VERSION ""

NS_ :

BS_:

BU_: GENERIC_GWMWakeup Generic_BCM TRM GWM _delete APIM SODL RTM FCIM PDM SCMH SCMG HSWM GPSM RSM SODR DDM RBM DSM SCME TSTR

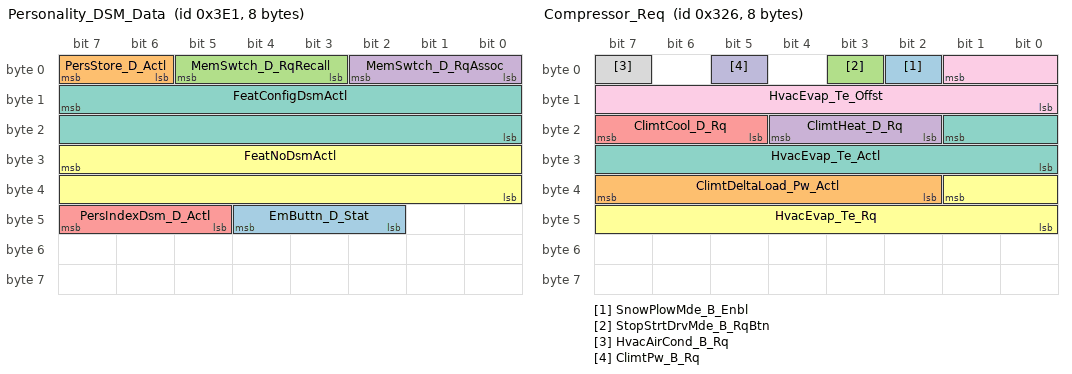
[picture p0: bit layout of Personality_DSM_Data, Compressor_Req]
BO_ 993 Personality_DSM_Data: 8 DSM
 SG_ EmButtn_D_Stat : 44|3@0+ (1,0) [0|7] "SED"  GWM
 SG_ PersStore_D_Actl : 7|2@0+ (1,0) [0|3] "SED"  GWM
 SG_ MemSwtch_D_RqRecall : 5|3@0+ (1,0) [0|7] "SED"  GWM
 SG_ MemSwtch_D_RqAssoc : 2|3@0+ (1,0) [0|7] "SED"  GWM
 SG_ PersIndexDsm_D_Actl : 47|3@0+ (1,0) [0|7] "SED"  GWM
 SG_ FeatNoDsmActl : 31|16@0+ (1,0) [0|65535] "Number"  GWM
 SG_ FeatConfigDsmActl : 15|16@0+ (1,0) [0|65535] "Undefined"  GWM

BO_ 1881 TesterPhysicalResRTM: 8 RTM
 SG_ TesterPhysicalResRTM : 7|64@0+ (1,0) [0|1.84467E+019] "unitless"  TSTR

BO_ 1873 TesterPhysicalReqRTM: 8 TSTR
 SG_ TesterPhysicalReqRTM : 7|64@0+ (1,0) [0|1.84467E+019] "unitless"  RTM

BO_ 2015 TesterFunctionalReq_M1: 8 TSTR
 SG_ TesterFunctionalReq : 7|64@0+ (1,0) [0|1.84467E+019] ""  APIM,PDM,SCMG,SCMH,TRM,RSM,RTM,GWM,DDM,DSM,FCIM,GPSM,HSWM,RBM,SCME,SODL,SODR

BO_ 806 Compressor_Req: 8 FCIM
 SG_ SnowPlowMde_B_Enbl : 2|1@0+ (1,0) [0|1] "SED"  GWM,SCMG,SCMH
 SG_ ClimtDeltaLoad_Pw_Actl : 39|6@0+ (50,-1600) [-1600|1450] "watts"  GWM
 SG_ StopStrtDrvMde_B_RqBtn : 3|1@0+ (1,0) [0|1] "SED"  GWM
 SG_ ClimtHeat_D_Rq : 20|3@0+ (1,0) [0|7] "SED"  GWM
 SG_ ClimtCool_D_Rq : 23|3@0+ (1,0) [0|7] "SED"  GWM
 SG_ HvacEvap_Te_Rq : 33|10@0+ (0.125,-50) [-50|77.875] "Degrees C"  GWM
 SG_ HvacEvap_Te_Actl : 17|10@0+ (0.125,-50) [-50|77.75] "Degrees C"  GWM
 SG_ HvacAirCond_B_Rq : 7|1@0+ (1,0) [0|1] "SED"  GWM
 SG_ HvacEvap_Te_Offst : 1|10@0+ (0.125,-50) [-50|77.875] "Degrees C"  GWM
 SG_ ClimtPw_B_Rq : 5|1@0+ (1,0) [0|1] "SED"  GWM

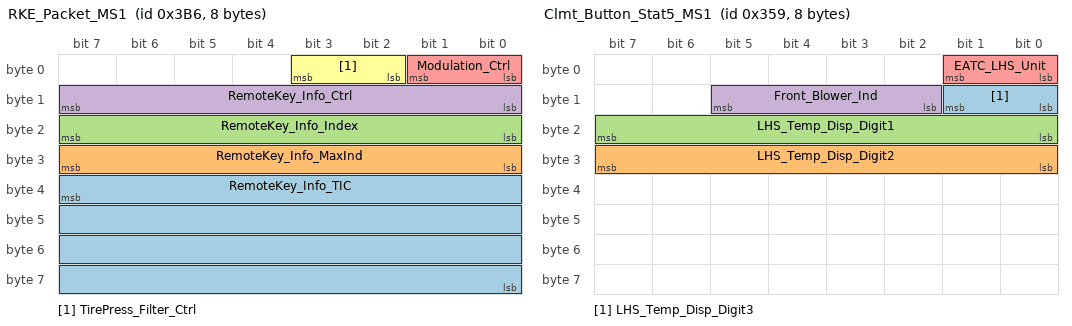
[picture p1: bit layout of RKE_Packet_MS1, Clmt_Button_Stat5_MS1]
BO_ 950 RKE_Packet_MS1: 8 GWM
 SG_ RemoteKey_Info_TIC : 39|32@0+ (1,0) [0|4294967295] "Unitless"  RTM
 SG_ RemoteKey_Info_MaxInd : 31|8@0+ (1,0) [0|255] "Unitless"  RTM
 SG_ RemoteKey_Info_Index : 23|8@0+ (1,0) [0|255] "Unitless"  RTM
 SG_ RemoteKey_Info_Ctrl : 15|8@0+ (1,0) [0|255] "Unitless" Vector__XXX
 SG_ Modulation_Ctrl : 1|2@0+ (1,0) [0|3] "SED" Vector__XXX
 SG_ TirePress_Filter_Ctrl : 3|2@0+ (1,0) [0|3] "SED"  RTM

BO_ 857 Clmt_Button_Stat5_MS1: 8 GWM
 SG_ LHS_Temp_Disp_Digit3 : 9|2@0+ (1,0) [0|3] "SED"  FCIM
 SG_ LHS_Temp_Disp_Digit2 : 31|8@0+ (1,0) [0|255] "ASCII"  FCIM
 SG_ LHS_Temp_Disp_Digit1 : 23|8@0+ (1,0) [0|255] "ASCII"  FCIM
 SG_ Front_Blower_Ind : 13|4@0+ (1,0) [0|15] "SED"  FCIM
 SG_ EATC_LHS_Unit : 1|2@0+ (1,0) [0|3] "SED"  FCIM

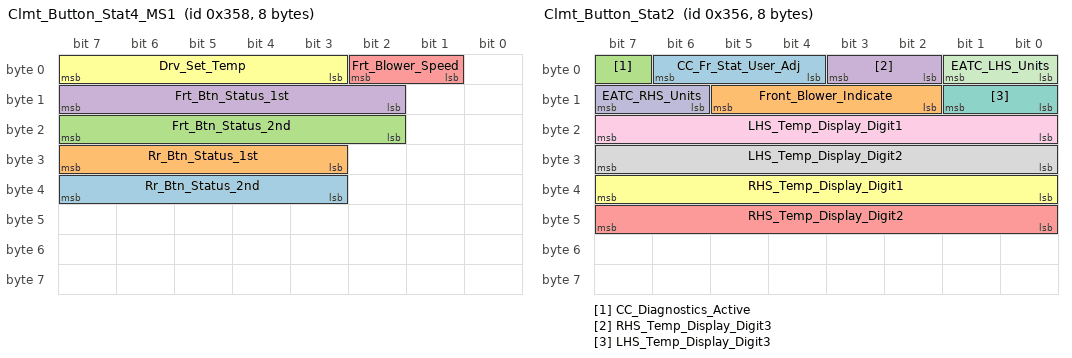
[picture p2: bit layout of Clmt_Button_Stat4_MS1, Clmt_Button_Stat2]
BO_ 856 Clmt_Button_Stat4_MS1: 8 GWM
 SG_ Rr_Btn_Status_2nd : 39|5@0+ (1,0) [0|31] "SED"  FCIM
 SG_ Rr_Btn_Status_1st : 31|5@0+ (1,0) [0|31] "SED"  FCIM
 SG_ Frt_Btn_Status_2nd : 23|6@0+ (1,0) [0|63] "SED"  FCIM
 SG_ Frt_Btn_Status_1st : 15|6@0+ (1,0) [0|63] "SED"  FCIM
 SG_ Frt_Blower_Speed : 2|2@0+ (1,0) [0|3] "SED"  FCIM
 SG_ Drv_Set_Temp : 7|5@0+ (1,0) [0|31] "SED"  FCIM

BO_ 854 Clmt_Button_Stat2: 8 FCIM
 SG_ CC_Fr_Stat_User_Adj : 6|3@0+ (1,0) [0|7] "SED"  GWM
 SG_ Front_Blower_Indicate : 13|4@0+ (1,0) [0|15] "SED"  GWM
 SG_ CC_Diagnostics_Active : 7|1@0+ (1,0) [0|1] "SED"  GWM
 SG_ RHS_Temp_Display_Digit3 : 3|2@0+ (1,0) [0|3] "SED"  GWM
 SG_ RHS_Temp_Display_Digit2 : 47|8@0+ (1,0) [0|255] "ASCII"  GWM
 SG_ RHS_Temp_Display_Digit1 : 39|8@0+ (1,0) [0|255] "ASCII"  GWM
 SG_ LHS_Temp_Display_Digit3 : 9|2@0+ (1,0) [0|3] "SED"  GWM
 SG_ LHS_Temp_Display_Digit2 : 31|8@0+ (1,0) [0|255] "ASCII"  GWM
 SG_ LHS_Temp_Display_Digit1 : 23|8@0+ (1,0) [0|255] "ASCII"  GWM
 SG_ EATC_RHS_Units : 15|2@0+ (1,0) [0|3] "SED"  GWM
 SG_ EATC_LHS_Units : 1|2@0+ (1,0) [0|3] "SED"  GWM

BO_ 1959 TesterPhysicalReqFCIM: 8 TSTR
 SG_ TesterPhysicalReqFCIM : 7|64@0+ (1,0) [0|1.84467E+019] "unitless"  FCIM

BO_ 1967 TesterPhysicalResFCIM: 8 FCIM
 SG_ TesterPhysicalResFCIM : 7|64@0+ (1,0) [0|1.84467E+019] "unitless"  TSTR

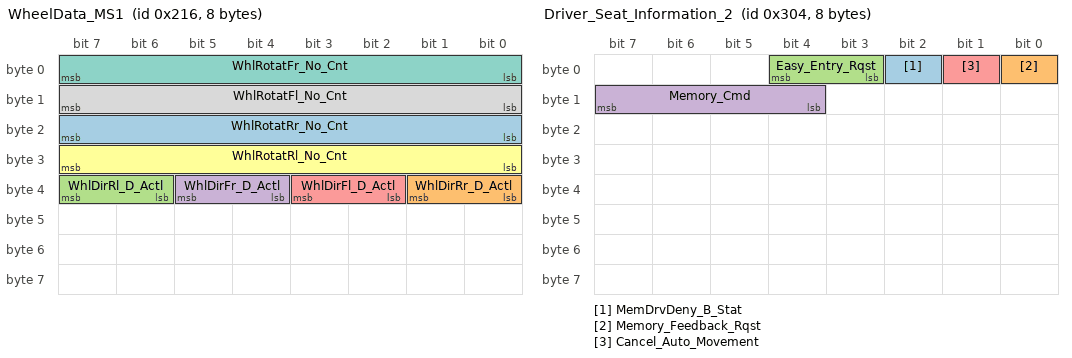
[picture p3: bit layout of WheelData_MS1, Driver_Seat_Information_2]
BO_ 534 WheelData_MS1: 8 GWM
 SG_ WhlRotatRr_No_Cnt : 23|8@0+ (1,0) [0|255] "Unitless"  GPSM
 SG_ WhlDirRr_D_Actl : 33|2@0+ (1,0) [0|3] "SED"  GPSM
 SG_ WhlDirRl_D_Actl : 39|2@0+ (1,0) [0|3] "SED"  GPSM
 SG_ WhlDirFr_D_Actl : 37|2@0+ (1,0) [0|3] "SED"  GPSM
 SG_ WhlDirFl_D_Actl : 35|2@0+ (1,0) [0|3] "SED"  GPSM
 SG_ WhlRotatRl_No_Cnt : 31|8@0+ (1,0) [0|255] "Unitless"  GPSM
 SG_ WhlRotatFr_No_Cnt : 7|8@0+ (1,0) [0|255] "Unitless"  SODL,SODR,GPSM
 SG_ WhlRotatFl_No_Cnt : 15|8@0+ (1,0) [0|255] "Unitless"  GPSM

BO_ 2008 TesterPhysicalResAPIM: 8 APIM
 SG_ TesterPhysicalResAPIM : 7|64@0+ (1,0) [0|1.84467E+019] "unitless"  TSTR

BO_ 772 Driver_Seat_Information_2: 8 DSM
 SG_ MemDrvDeny_B_Stat : 2|1@0+ (1,0) [0|1] "SED"  GWM
 SG_ Memory_Feedback_Rqst : 0|1@0+ (1,0) [0|1] "SED"  GWM
 SG_ Easy_Entry_Rqst : 4|2@0+ (1,0) [0|3] "SED"  SCMH,SCMG
 SG_ Memory_Cmd : 15|4@0+ (1,0) [0|15] "SED"  GWM,SCMH,DDM,PDM,SCMG
 SG_ Cancel_Auto_Movement : 1|1@0+ (1,0) [0|1] "SED"  PDM,DDM,SCMG

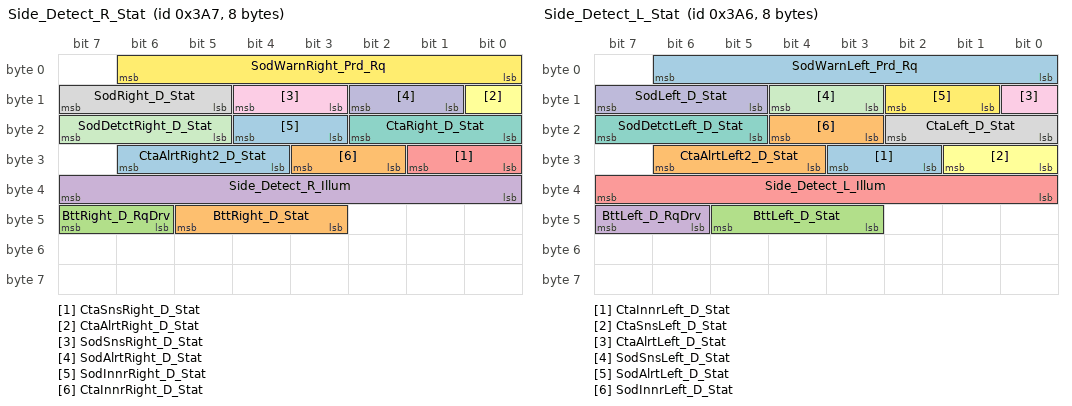
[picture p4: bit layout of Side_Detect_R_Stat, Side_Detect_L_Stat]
BO_ 935 Side_Detect_R_Stat: 8 SODR
 SG_ CtaAlrtRight2_D_Stat : 30|3@0+ (1,0) [0|7] "SED"  GWM
 SG_ BttRight_D_Stat : 45|3@0+ (1,0) [0|7] "SED"  GWM,SODL
 SG_ BttRight_D_RqDrv : 47|2@0+ (1,0) [0|3] "SED"  GWM,SODL
 SG_ Side_Detect_R_Illum : 39|8@0+ (1,0) [0|255] "Percent"  DDM,PDM,GWM
 SG_ CtaSnsRight_D_Stat : 25|2@0+ (1,0) [0|3] "SED"  SODL,GWM
 SG_ CtaAlrtRight_D_Stat : 8|1@0+ (1,0) [0|1] "SED"  DDM,PDM,GWM
 SG_ CtaRight_D_Stat : 18|3@0+ (1,0) [0|7] "SED"  SODL,GWM
 SG_ SodRight_D_Stat : 15|3@0+ (1,0) [0|7] "SED"  SODL,GWM
 SG_ SodSnsRight_D_Stat : 12|2@0+ (1,0) [0|3] "SED"  DDM,PDM,GWM,SODL
 SG_ SodAlrtRight_D_Stat : 10|2@0+ (1,0) [0|3] "SED"  DDM,PDM,GWM
 SG_ SodDetctRight_D_Stat : 23|3@0+ (1,0) [0|7] "SED"  GWM
 SG_ SodWarnRight_Prd_Rq : 6|7@0+ (1,0) [0|127] "millisecond"  DDM,PDM,GWM
 SG_ SodInnrRight_D_Stat : 20|2@0+ (1,0) [0|3] "SED"  GWM
 SG_ CtaInnrRight_D_Stat : 27|2@0+ (1,0) [0|3] "SED"  GWM

BO_ 934 Side_Detect_L_Stat: 8 SODL
 SG_ CtaInnrLeft_D_Stat : 27|2@0+ (1,0) [0|3] "SED"  GWM
 SG_ CtaAlrtLeft2_D_Stat : 30|3@0+ (1,0) [0|7] "SED"  GWM
 SG_ BttLeft_D_Stat : 45|3@0+ (1,0) [0|7] "SED"  GWM,SODR
 SG_ BttLeft_D_RqDrv : 47|2@0+ (1,0) [0|3] "SED"  GWM,SODR
 SG_ Side_Detect_L_Illum : 39|8@0+ (1,0) [0|255] "Percent"  GWM,DDM,PDM
 SG_ CtaSnsLeft_D_Stat : 25|2@0+ (1,0) [0|3] "SED"  SODR,GWM
 SG_ SodDetctLeft_D_Stat : 23|3@0+ (1,0) [0|7] "SED"  GWM
 SG_ CtaLeft_D_Stat : 18|3@0+ (1,0) [0|7] "SED"  SODR,GWM
 SG_ CtaAlrtLeft_D_Stat : 8|1@0+ (1,0) [0|1] "SED"  DDM,PDM,GWM
 SG_ SodLeft_D_Stat : 15|3@0+ (1,0) [0|7] "SED"  SODR,GWM
 SG_ SodSnsLeft_D_Stat : 12|2@0+ (1,0) [0|3] "SED"  DDM,PDM,SODR,GWM
 SG_ SodAlrtLeft_D_Stat : 10|2@0+ (1,0) [0|3] "SED"  DDM,PDM,GWM
 SG_ SodWarnLeft_Prd_Rq : 6|7@0+ (1,0) [0|127] "millisecond"  DDM,PDM,GWM
 SG_ SodInnrLeft_D_Stat : 20|2@0+ (1,0) [0|3] "SED"  GWM

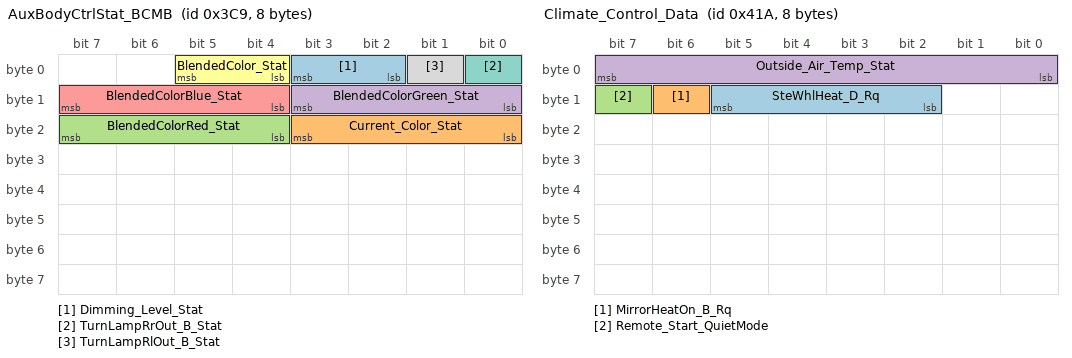
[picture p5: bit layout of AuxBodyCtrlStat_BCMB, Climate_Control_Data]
BO_ 969 AuxBodyCtrlStat_BCMB: 8 Generic_BCM
 SG_ Dimming_Level_Stat : 3|2@0+ (1,0) [0|3] "SED"  GWM
 SG_ Current_Color_Stat : 19|4@0+ (1,0) [0|15] "SED"  GWM
 SG_ BlendedColorRed_Stat : 23|4@0+ (1,0) [0|15] "SED"  GWM
 SG_ BlendedColorGreen_Stat : 11|4@0+ (1,0) [0|15] "SED"  GWM
 SG_ BlendedColorBlue_Stat : 15|4@0+ (1,0) [0|15] "SED"  GWM
 SG_ BlendedColor_Stat : 5|2@0+ (1,0) [0|3] "SED"  GWM
 SG_ TurnLampRrOut_B_Stat : 0|1@0+ (1,0) [0|1] "SED"  GWM
 SG_ TurnLampRlOut_B_Stat : 1|1@0+ (1,0) [0|1] "SED"  GWM

BO_ 1070 EngineData_2_MS1: 8 GWM
 SG_ StopStrtStdby_D_Indic_UB : 43|1@0+ (1,0) [0|1] "SED"  FCIM
 SG_ PassRstrnInd_Req_UB : 42|1@0+ (1,0) [0|1] "SED"  FCIM
 SG_ HiElPwInhbt_B_Stat_UB : 61|1@0+ (1,0) [0|1] "SED"  DDM,PDM
 SG_ HiElPwInhbt_B_Stat : 47|1@0+ (1,0) [0|1] "SED"  DDM,PDM
 SG_ StopStrtStdby_D_Indic : 46|3@0+ (1,0) [0|7] "SED"  FCIM
 SG_ CoolantFanStepAct_UB : 2|1@0+ (1,0) [0|1] "SED"  FCIM
 SG_ CoolantFanStepAct : 7|5@0+ (1,0) [0|31] "Steps"  FCIM
 SG_ VehVActlEng_D_Qf_UB : 1|1@0+ (1,0) [0|1] "SED"  DDM,PDM,RTM
 SG_ RstrnImpactEvntStatus_UB : 56|1@0+ (1,0) [0|1] "SED"  FCIM
 SG_ EngAirIn_Te_Actl_UB : 60|1@0+ (1,0) [0|1] "SED"  FCIM
 SG_ RstrnImpactEvntStatus : 59|3@0+ (1,0) [0|7] "SED"  FCIM
 SG_ EngAirIn_Te_Actl : 55|10@0+ (0.25,-128) [-128|127.25] "degC"  FCIM
 SG_ EngAout_N_Actl_UB : 0|1@0+ (1,0) [0|1] "SED"  FCIM
 SG_ EngAout_N_Actl : 28|13@0+ (2,0) [0|16382] "rpm"  FCIM
 SG_ VehVActlEng_D_Qf : 31|2@0+ (1,0) [0|3] "SED"  DSM,RBM,RTM,DDM,PDM,FCIM,SODL,SODR
 SG_ Veh_V_ActlEng_UB : 29|1@0+ (1,0) [0|1] "SED"  RBM,DSM,SCMG,SCMH,DDM,PDM,RTM,GPSM,FCIM,SODL,SODR
 SG_ Veh_V_ActlEng : 15|16@0+ (0.01,0) [0|655.35] "kph"  RBM,DSM,SCMG,SCMH,DDM,PDM,RTM,GPSM,FCIM,SODL,SODR
 SG_ PassRstrnInd_Req : 41|2@0+ (1,0) [0|3] "SED"  FCIM

BO_ 1050 Climate_Control_Data: 8 FCIM
 SG_ SteWhlHeat_D_Rq : 13|4@0+ (1,0) [0|15] "SED"  GWM,HSWM
 SG_ MirrorHeatOn_B_Rq : 14|1@0+ (1,0) [0|1] "SED"  DDM,PDM
 SG_ Remote_Start_QuietMode : 15|1@0+ (1,0) [0|1] "SED"  GWM
 SG_ Outside_Air_Temp_Stat : 7|8@0+ (0.5,-40) [-40|86.5] "Degrees C"  GWM,DDM,PDM

BO_ 1856 TesterPhysicalReqDDM: 8 TSTR
 SG_ TesterPhysicalReqDDM : 7|64@0+ (1,0) [0|1.84467E+019] "unitless"  DDM

BO_ 1864 TesterPhysicalResDDM: 8 DDM
 SG_ TesterPhysicalResDDM : 7|64@0+ (1,0) [0|1.84467E+019] "unitless"  TSTR

BO_ 1937 TesterPhysicalReqTRM: 8 TSTR
 SG_ TesterPhysicalReqTRM : 7|64@0+ (1,0) [0|1.84467E+019] "unitless"  TRM

BO_ 1364 TRM_Network_MgmtM: 8 TRM
 SG_ TRM_Network_Mgmt : 7|64@0+ (1,0) [0|1.844674407371E+019] "unitless"  DDM,DSM,FCIM,GPSM,GWM,PDM,RBM,RTM,SCME

BO_ 947 BodyInfo_3_MS1: 8 GWM
 SG_ ValetMode_D_Mem : 16|1@0+ (1,0) [0|1] "SED" Vector__XXX
 SG_ DrStatDrvErrCnt_B_Stat : 19|1@0+ (1,0) [0|1] "SED" Vector__XXX
 SG_ DimmingLvlEvnt_No_Actl : 18|2@0+ (1,0) [0|3] "unitless" Vector__XXX
 SG_ TurnLghtRightOn_B_Stat : 35|1@0+ (1,0) [0|1] "SED" Vector__XXX
 SG_ TurnLghtLeftOn_B_Stat : 54|1@0+ (1,0) [0|1] "SED" Vector__XXX
 SG_ Backlit_LED_Status : 23|4@0+ (1,0) [0|15] "SED"  DDM,FCIM,PDM
 SG_ FogLghtRearOn_B_Stat : 1|1@0+ (1,0) [0|1] "SED"  TRM
 SG_ IgnKeyType_D_Actl : 39|4@0+ (1,0) [0|15] "SED"  RSM,SODL,SODR
 SG_ TurnLghtRight_D_Rq : 63|2@0+ (1,0) [0|3] "SED"  RSM,DDM,PDM,TRM
 SG_ Parklamp_Status : 3|2@0+ (1,0) [0|3] "SED"  TRM,PDM,DDM,FCIM,SODL,SODR
 SG_ Litval : 47|8@0+ (1,0) [0|253] "SED"  DDM,FCIM,PDM,SODL,SODR
 SG_ Key_In_Ignition_Stat : 11|1@0+ (1,0) [0|1] "SED"  RSM,SCMG,SCMH,DSM,RTM
 SG_ Ignition_Status : 7|4@0+ (1,0) [0|15] "SED"  SCME,RSM,DDM,DSM,FCIM,GPSM,HSWM,PDM,RBM,RTM,SCMG,SCMH,TRM,SODL,SODR
 SG_ Dimming_Lvl : 31|8@0+ (1,0) [0|253] "SED"  DDM,FCIM,PDM
 SG_ Day_Night_Status : 15|2@0+ (1,0) [0|3] "SED"  DDM,FCIM,PDM
 SG_ Remote_Start_Status : 13|2@0+ (1,0) [0|3] "SED"  RSM,FCIM
 SG_ DrStatTgate_B_Actl : 0|1@0+ (1,0) [0|1] "SED"  RSM
 SG_ DrStatRr_B_Actl : 49|1@0+ (1,0) [0|1] "SED"  RBM,RSM
 SG_ DrStatRl_B_Actl : 48|1@0+ (1,0) [0|1] "SED"  RBM,RSM
 SG_ DrStatPsngr_B_Actl : 60|1@0+ (1,0) [0|1] "SED"  RBM,RSM
 SG_ DrStatInnrTgate_B_Actl : 58|1@0+ (1,0) [0|1] "SED"  RSM
 SG_ DrStatHood_B_Actl : 59|1@0+ (1,0) [0|1] "SED"  RSM
 SG_ DrStatDrv_B_Actl : 61|1@0+ (1,0) [0|1] "SED"  RBM,RSM
 SG_ PrkBrkActv_B_Actl : 55|1@0+ (1,0) [0|1] "SED" Vector__XXX
 SG_ LifeCycMde_D_Actl : 53|4@0+ (1,0) [0|15] "SED"  TRM,RTM,DDM,PDM,FCIM,HSWM
 SG_ Delay_Accy : 57|1@0+ (1,0) [0|1] "SED"  DDM,PDM
 SG_ FogLghtFrontOn_B_Stat : 56|1@0+ (1,0) [0|1] "SED" Vector__XXX
 SG_ TurnLghtLeft_D_Rq : 9|2@0+ (1,0) [0|3] "SED"  RSM,DDM,PDM,TRM
 SG_ CrashEvnt_D_Stat : 34|2@0+ (1,0) [0|3] "SED"  FCIM
 SG_ FuelPmpInhbt_B_Stat : 32|1@0+ (1,0) [0|1] "SED"  FCIM
 SG_ BodySrvcRqd_B_Rq : 10|1@0+ (1,0) [0|1] "SED" Vector__XXX

BO_ 293 ClmtCtrlSeatSet_Stat_v2: 8 SCME
 SG_ ClmtCtrlSeat_SetStat_Psgr : 15|8@0+ (1,0) [0|254] "SED"  FCIM
 SG_ ClmtCtrlSeat_SetStat_Dvr : 7|8@0+ (1,0) [0|254] "SED"  FCIM

CM_ BO_ 2015 "OBDII Request ($7DF) messages are for FNOS 1.0.1 only.
Diagnostic Functional Addressing ($7DF) and Dual Rate Periodic messages are for FNOS I3 only.";
CM_ SG_ 857 LHS_Temp_Disp_Digit3 "Added for MY 08";
CM_ SG_ 857 LHS_Temp_Disp_Digit2 "Added for MY 08";
CM_ SG_ 857 LHS_Temp_Disp_Digit1 "Added for MY 08";
CM_ SG_ 857 EATC_LHS_Unit "Added for MY 08";
CM_ SG_ 854 RHS_Temp_Display_Digit3 "Added for MY 08";
CM_ SG_ 854 RHS_Temp_Display_Digit2 "Added for MY 08";
CM_ SG_ 854 RHS_Temp_Display_Digit1 "Added for MY 08";
CM_ SG_ 854 LHS_Temp_Display_Digit3 "Added for MY 08";
CM_ SG_ 854 LHS_Temp_Display_Digit2 "Added for MY 08";
CM_ SG_ 854 LHS_Temp_Display_Digit1 "Added for MY 08";
CM_ SG_ 854 EATC_RHS_Units "Added for MY 08";
CM_ SG_ 854 EATC_LHS_Units "Added for MY 08";
CM_ SG_ 772 Memory_Feedback_Rqst "Updated to 1 bit for CGEA, Not backwards compatible";
CM_ SG_ 935 Side_Detect_R_Illum "DDMGenSigTimeoutTime=2000";
CM_ SG_ 935 SodRight_D_Stat "IPCGenSigTimeoutTime=1600";
CM_ SG_ 935 SodSnsRight_D_Stat "IPCGenSigTimeoutTime=1600";
CM_ SG_ 935 SodAlrtRight_D_Stat "DDMGenSigTimeoutTime=2000";
CM_ SG_ 935 CtaInnrRight_D_Stat "IPCGenSigTimeoutTime=1600";
CM_ SG_ 934 CtaInnrLeft_D_Stat "IPCGenSigTimeoutTime=1600";
CM_ SG_ 934 Side_Detect_L_Illum "DDMGenSigTimeoutTime=2000";
CM_ SG_ 934 SodLeft_D_Stat "IPCGenSigTimeoutTime=1600";
CM_ SG_ 934 SodSnsLeft_D_Stat "IPCGenSigTimeoutTime=1600";
CM_ SG_ 934 SodAlrtLeft_D_Stat "DDMGenSigTimeoutTime=2000";
CM_ SG_ 969 TurnLampRrOut_B_Stat "Signal not transmitted on vehicles without a BCMB module.";
CM_ SG_ 969 TurnLampRlOut_B_Stat "Signal not transmitted on vehicles without a BCMB module.";
CM_ SG_ 1070 HiElPwInhbt_B_Stat "Signal not transmitted on HEV programs";
CM_ SG_ 1050 Outside_Air_Temp_Stat "Filtered value, i.e. same as disply for customer";
CM_ SG_ 947 Dimming_Lvl "Refer to Vehicle Interior Illum Dimming Ctrl Sys Eng Spec, Table 2

";
CM_ SG_ 947 PrkBrkActv_B_Actl "Signal not transmitted on vehicles with electric park brake. ";
BA_DEF_ SG_  "U_V36X_MY18_5_Gas_Rx" ENUM  "No","Yes";
BA_DEF_ SG_  "U_V36X_MY18_5_Hev_Rx" ENUM  "No","Yes";
BA_DEF_ SG_  "U_U55x_MY18_Gas_Rx" ENUM  "No","Yes";
BA_DEF_ SG_  "U_V408_MY18_Gas_Rx" ENUM  "No","Yes";
BA_DEF_ SG_  "U_V408_MY18_Diesel_Rx" ENUM  "No","Yes";
BA_DEF_ SG_  "U_V36X_MY18_5_Diesel_Rx" ENUM  "No","Yes";
BA_DEF_ SG_  "U_V36X_MY19_5_Diesel_Rx" ENUM  "No","Yes";
BA_DEF_ SG_  "U_V363E_N_MY19_5_20_Gas_Rx" ENUM  "No","Yes";
BA_DEF_ SG_  "U_V363E_N_MY19_5_20_Diesel_Rx" ENUM  "No","Yes";
BA_DEF_ SG_  "U_U55x_MY18_Gas_Tx" ENUM  "No","Yes";
BA_DEF_ SG_  "GenSigTimeoutTime_SCMJ" INT 0 100000;
BA_DEF_ BO_  "FrameGatewayNetwork" STRING ;
BA_DEF_ SG_  "U_CD42_MY16_Diesel_Rx" ENUM  "No","Yes";
BA_DEF_ SG_  "U_CD42_MY16_Gas_Rx" ENUM  "No","Yes";
BA_DEF_ SG_  "U_CD43_MY17_Gas_Rx" ENUM  "No","Yes";
BA_DEF_ SG_  "U_P552_MY17_Gas_Rx" ENUM  "No","Yes";
BA_DEF_ SG_  "U_P552_MY17_Gas_Tx" ENUM  "No","Yes";
BA_DEF_ SG_  "GenSigTimeoutTime_SOBDMD_AHCM_F" INT 0 100000;
BA_DEF_ SG_  "GenSigTimeoutTime_SFMA" INT 0 100000;
BA_DEF_ SG_  "GenSigTimeoutTime_SFMB" INT 0 100000;
BA_DEF_ SG_  "GenSigTimeoutTime_SCMD" INT 0 100000;
BA_DEF_ SG_  "GenSigTimeoutTime_DCMH" INT 0 100000;
BA_DEF_ SG_  "GenSigTimeoutTime_DCMG" INT 0 100000;
BA_DEF_ SG_  "GenSigTimeoutTime_DCMF" INT 0 100000;
BA_DEF_ SG_  "GenSigTimeoutTime_DCME" INT 0 100000;
BA_DEF_ SG_  "GenSigTimeoutTime_BCMB_ABM" INT 0 100000;
BA_DEF_ SG_  "GenSigTimeoutTime_SCMC" INT 0 100000;
BA_DEF_ SG_  "GenSigTimeoutTime_BCMB_CAPM" INT 0 100000;
BA_DEF_ SG_  "GenSigTimeoutTime_GFM_ASM" INT 0 100000;
BA_DEF_ SG_  "GenSigTimeoutTime_SCMB_PSM" INT 0 100000;
BA_DEF_ SG_  "GenSigTimeoutTime_BCMB_ALCM" INT 0 100000;
BA_DEF_ SG_  "U_CD42_MY15_Diesel_Rx" ENUM  "No","Yes";
BA_DEF_ SG_  "U_CD42_MY15_Gas_Rx" ENUM  "No","Yes";
BA_DEF_ SG_  "U_U502_MY16_Gas_Rx" ENUM  "No","Yes";
BA_DEF_ SG_  "U_P558_MY17_Gas_Rx" ENUM  "No","Yes";
BA_DEF_ SG_  "U_P558_MY17_Diesel_Rx" ENUM  "No","Yes";
BA_DEF_ SG_  "U_CD42_MY15_Diesel_Tx" ENUM  "No","Yes";
BA_DEF_ SG_  "U_CD42_MY15_Gas_Tx" ENUM  "No","Yes";
BA_DEF_ SG_  "U_CD4_MY15_Diesel_Tx" ENUM  "No","Yes";
BA_DEF_ SG_  "U_CD4_MY15_Gas_Tx" ENUM  "No","Yes";
BA_DEF_ SG_  "U_CD4_MY15_Hev_Tx" ENUM  "No","Yes";
BA_DEF_ SG_  "U_CD4_MY15_Phev_Tx" ENUM  "No","Yes";
BA_DEF_ SG_  "U_P558_MY17_Gas_Tx" ENUM  "No","Yes";
BA_DEF_ SG_  "U_P558_MY17_Diesel_Tx" ENUM  "No","Yes";
BA_DEF_ SG_  "GenSigTimeoutTime_SCMF" INT 0 100000;
BA_DEF_ SG_  "GenSigTimeoutTime_RGTM" INT 0 100000;
BA_DEF_ SG_  "GenSigTimeoutTime_GENERIC" INT 0 100000;
BA_DEF_ SG_  "GenSigTimeoutTime_AHCM_FOH" INT 0 100000;
BA_DEF_ SG_  "GenSigTimeoutTime_RLCMA" INT 0 100000;
BA_DEF_ SG_  "GenSigTimeoutTime_BCMB" INT 0 100000;
BA_DEF_ SG_  "GenSigTimeoutTime_RHVAC" INT 0 100000;
BA_DEF_ SG_  "GenSigTimeoutTime_MRCMB" INT 0 100000;
BA_DEF_ SG_  "GenSigTimeoutTime_MRCMA" INT 0 100000;
BA_DEF_ SG_  "GenSigTimeoutTime_HVAC_RCCM" INT 0 100000;
BA_DEF_ SG_  "Gateway_ID" INT 0 0;
BA_DEF_ SG_  "GenSigTimeoutTime__delete" INT 0 100000;
BA_DEF_ SG_  "GenSigTimeoutTime_APIM" INT 0 100000;
BA_DEF_ SG_  "GenSigTimeoutTime_Generic_BCM" INT 0 100000;
BA_DEF_ SG_  "GenSigTimeoutTime_RSM" INT 0 100000;
BA_DEF_ SG_  "GenSigTimeoutTime_PDM" INT 0 100000;
BA_DEF_ SG_  "GenSigTimeoutTime_TRM" INT 0 100000;
BA_DEF_ SG_  "GenSigTimeoutTime_SCMG" INT 0 100000;
BA_DEF_ SG_  "GenSigTimeoutTime_SCMH" INT 0 100000;
BA_DEF_ SG_  "GenSigTimeoutTime_RTM" INT 0 100000;
BA_DEF_ SG_  "GenSigTimeoutTime_GWM" INT 0 100000;
BA_DEF_ SG_  "GenSigTimeoutTime_FCIM" INT 0 100000;
BA_DEF_ SG_  "GenSigTimeoutTime_HSWM" INT 0 100000;
BA_DEF_ SG_  "GenSigTimeoutTime_GPSM" INT 0 100000;
BA_DEF_ SG_  "GenSigTimeoutTime_RBM" INT 0 100000;
BA_DEF_ SG_  "GenSigTimeoutTime_DDM" INT 0 100000;
BA_DEF_ SG_  "GenSigTimeoutTime_DSM" INT 0 100000;
BA_DEF_ SG_  "GenSigTimeoutTime_SODR" INT 0 100000;
BA_DEF_ SG_  "GenSigTimeoutTime_SODL" INT 0 100000;
BA_DEF_ SG_  "GenSigTimeoutTime_TSTR" INT 0 100000;
BA_DEF_ SG_  "GenSigTimeoutTime_SCME" INT 0 100000;
BA_DEF_ BO_  "FrameGatewayMS1" HEX 0 1407;
BA_DEF_ BO_  "FrameGatewayHS3" HEX 0 1407;
BA_DEF_ BO_  "FrameGatewayHS2" HEX 0 1407;
BA_DEF_ BO_  "FrameGatewayHS1" HEX 0 1407;
BA_DEF_ BO_  "NetworkInitialization" ENUM  "No","Yes";
BA_DEF_ BO_  "FrameGatewayId" HEX 0 1407;
BA_DEF_ BO_  "EventRateOfChange" INT 10 10000;
BA_DEF_ BO_  "GenMsgStartDelayTime" INT 0 10000;
BA_DEF_ BO_  "GenMsgNrOfRepetition" INT 0 100;
BA_DEF_ BO_  "GenMsgDelayTime" INT 0 1000;
BA_DEF_ BO_  "GenMsgCycleTime" INT 0 100000;
BA_DEF_ BO_  "GenMsgSendType" ENUM  "FixedPeriodic","Event","EnabledPeriodic","NotUsed","NotUsed","EventPeriodic","NotUsed","NotUsed","NoMsgSendType";
BA_DEF_ SG_  "U_CD4_MY14_Phev_Tx" ENUM  "No","Yes";
BA_DEF_ SG_  "U_CD4_MY14_Hev_Tx" ENUM  "No","Yes";
BA_DEF_ SG_  "U_CD4_MY14_Gas_Tx" ENUM  "No","Yes";
BA_DEF_ SG_  "U_CD4_MY14_Diesel_Tx" ENUM  "No","Yes";
BA_DEF_ SG_  "U_CD43_MY16_Gas_Tx" ENUM  "No","Yes";
BA_DEF_ SG_  "U_UP375_MY15_Diesel_Tx" ENUM  "No","Yes";
BA_DEF_ SG_  "U_UP375_MY15_Gas_Tx" ENUM  "No","Yes";
BA_DEF_ SG_  "U_U502_MY15_Gas_Tx" ENUM  "No","Yes";
BA_DEF_ SG_  "U_B562LC_MY14_Gas_Tx" ENUM  "No","Yes";
BA_DEF_ SG_  "U_B562LC_MY14_Diesel_Tx" ENUM  "No","Yes";
BA_DEF_ SG_  "U_C489_MY14_Gas_Tx" ENUM  "No","Yes";
BA_DEF_ SG_  "U_S550_MY15_Gas_Tx" ENUM  "No","Yes";
BA_DEF_ SG_  "U_P552_MY15_Gas_Tx" ENUM  "No","Yes";
BA_DEF_ SG_  "U_CD42_MY14_Gas_Tx" ENUM  "No","Yes";
BA_DEF_ SG_  "U_CD42_MY14_Diesel_Tx" ENUM  "No","Yes";
BA_DEF_ SG_  "U_CD4_MY13_Phev_Tx" ENUM  "No","Yes";
BA_DEF_ SG_  "U_CD4_MY13_Hev_Tx" ENUM  "No","Yes";
BA_DEF_ SG_  "U_CD4_MY13_Gas_Tx" ENUM  "No","Yes";
BA_DEF_ SG_  "U_CD4_MY13_Diesel_Tx" ENUM  "No","Yes";
BA_DEF_ SG_  "U_CD4_MY14_Phev_Rx" ENUM  "No","Yes";
BA_DEF_ SG_  "U_CD4_MY14_Hev_Rx" ENUM  "No","Yes";
BA_DEF_ SG_  "U_CD4_MY14_Gas_Rx" ENUM  "No","Yes";
BA_DEF_ SG_  "U_CD4_MY14_Diesel_Rx" ENUM  "No","Yes";
BA_DEF_ SG_  "U_CD43_MY16_Gas_Rx" ENUM  "No","Yes";
BA_DEF_ SG_  "U_UP375_MY15_Diesel_Rx" ENUM  "No","Yes";
BA_DEF_ SG_  "U_UP375_MY15_Gas_Rx" ENUM  "No","Yes";
BA_DEF_ SG_  "U_B479_MY15_Gas_Rx" ENUM  "No","Yes";
BA_DEF_ SG_  "U_U502_MY15_Gas_Rx" ENUM  "No","Yes";
BA_DEF_ SG_  "U_B562LC_MY14_Gas_Rx" ENUM  "No","Yes";
BA_DEF_ SG_  "U_B562LC_MY14_Diesel_Rx" ENUM  "No","Yes";
BA_DEF_ SG_  "U_C489_MY14_Gas_Rx" ENUM  "No","Yes";
BA_DEF_ SG_  "U_S550_MY15_Gas_Rx" ENUM  "No","Yes";
BA_DEF_ SG_  "U_P552_MY15_Gas_Rx" ENUM  "No","Yes";
BA_DEF_ SG_  "U_CD42_MY14_Gas_Rx" ENUM  "No","Yes";
BA_DEF_ SG_  "U_CD42_MY14_Diesel_Rx" ENUM  "No","Yes";
BA_DEF_ SG_  "U_CD4_MY13_Phev_Rx" ENUM  "No","Yes";
BA_DEF_ SG_  "U_CD4_MY13_Hev_Rx" ENUM  "No","Yes";
BA_DEF_ SG_  "U_CD4_MY13_Gas_Rx" ENUM  "No","Yes";
BA_DEF_ SG_  "U_CD4_MY13_Diesel_Rx" ENUM  "No","Yes";
BA_DEF_ SG_  "ContentDependant" ENUM  "No","Yes";
BA_DEF_ SG_  "GenSigStartValue" INT 0 1000000000;
BA_DEF_ SG_  "UsedOnPgmDBC" ENUM  "No","Yes";
BA_DEF_ SG_  "CrossOver_LIN" ENUM  "No","Yes";
BA_DEF_ SG_  "CrossOver_InfoCAN" ENUM  "No","Yes";
BA_DEF_ SG_  "WakeupSignal" ENUM  "No","Yes";
BA_DEF_ SG_  "FMC_SIG_SSPEC" STRING ;
BA_DEF_ SG_  "GenSigMissingSourceValue" INT 0 1000000000;
BA_DEF_ SG_  "GenSigInactiveValue" INT 0 100000;
BA_DEF_ SG_  "GenSigSendType" ENUM  "Cyclic","OnWrite","vector_leerstring","OnChange","vector_leerstring","IfActive","vector_leerstring","NoSigSendType";
BA_DEF_ BO_  "DiagState" ENUM  "No","Yes";
BA_DEF_ BO_  "TpTxIndex" INT 0 255;
BA_DEF_ BO_  "DiagRequest" ENUM  "No","Yes";
BA_DEF_ BO_  "DiagResponse" ENUM  "No","Yes";
BA_DEF_ BO_  "NmMessage" ENUM  "No","Yes";
BA_DEF_ BO_  "GenMsgILSupport" ENUM  "No","Yes";
BA_DEF_DEF_  "U_V36X_MY18_5_Gas_Rx" "No";
BA_DEF_DEF_  "U_V36X_MY18_5_Hev_Rx" "No";
BA_DEF_DEF_  "U_U55x_MY18_Gas_Rx" "No";
BA_DEF_DEF_  "U_V408_MY18_Gas_Rx" "No";
BA_DEF_DEF_  "U_V408_MY18_Diesel_Rx" "No";
BA_DEF_DEF_  "U_V36X_MY18_5_Diesel_Rx" "No";
BA_DEF_DEF_  "U_V36X_MY19_5_Diesel_Rx" "No";
BA_DEF_DEF_  "U_V363E_N_MY19_5_20_Gas_Rx" "No";
BA_DEF_DEF_  "U_V363E_N_MY19_5_20_Diesel_Rx" "No";
BA_DEF_DEF_  "U_U55x_MY18_Gas_Tx" "No";
BA_DEF_DEF_  "GenSigTimeoutTime_SCMJ" 5000;
BA_DEF_DEF_  "FrameGatewayNetwork" "NONE";
BA_DEF_DEF_  "U_CD42_MY16_Diesel_Rx" "No";
BA_DEF_DEF_  "U_CD42_MY16_Gas_Rx" "No";
BA_DEF_DEF_  "U_CD43_MY17_Gas_Rx" "No";
BA_DEF_DEF_  "U_P552_MY17_Gas_Rx" "No";
BA_DEF_DEF_  "U_P552_MY17_Gas_Tx" "No";
BA_DEF_DEF_  "GenSigTimeoutTime_SOBDMD_AHCM_F" 5000;
BA_DEF_DEF_  "GenSigTimeoutTime_SFMA" 5000;
BA_DEF_DEF_  "GenSigTimeoutTime_SFMB" 5000;
BA_DEF_DEF_  "GenSigTimeoutTime_SCMD" 5000;
BA_DEF_DEF_  "GenSigTimeoutTime_DCMH" 5000;
BA_DEF_DEF_  "GenSigTimeoutTime_DCMG" 5000;
BA_DEF_DEF_  "GenSigTimeoutTime_DCMF" 5000;
BA_DEF_DEF_  "GenSigTimeoutTime_DCME" 5000;
BA_DEF_DEF_  "GenSigTimeoutTime_BCMB_ABM" 5000;
BA_DEF_DEF_  "GenSigTimeoutTime_SCMC" 5000;
BA_DEF_DEF_  "GenSigTimeoutTime_BCMB_CAPM" 5000;
BA_DEF_DEF_  "GenSigTimeoutTime_GFM_ASM" 5000;
BA_DEF_DEF_  "GenSigTimeoutTime_SCMB_PSM" 5000;
BA_DEF_DEF_  "GenSigTimeoutTime_BCMB_ALCM" 5000;
BA_DEF_DEF_  "U_CD42_MY15_Diesel_Rx" "No";
BA_DEF_DEF_  "U_CD42_MY15_Gas_Rx" "No";
BA_DEF_DEF_  "U_U502_MY16_Gas_Rx" "No";
BA_DEF_DEF_  "U_P558_MY17_Gas_Rx" "No";
BA_DEF_DEF_  "U_P558_MY17_Diesel_Rx" "No";
BA_DEF_DEF_  "U_CD42_MY15_Diesel_Tx" "No";
BA_DEF_DEF_  "U_CD42_MY15_Gas_Tx" "No";
BA_DEF_DEF_  "U_CD4_MY15_Diesel_Tx" "No";
BA_DEF_DEF_  "U_CD4_MY15_Gas_Tx" "No";
BA_DEF_DEF_  "U_CD4_MY15_Hev_Tx" "No";
BA_DEF_DEF_  "U_CD4_MY15_Phev_Tx" "No";
BA_DEF_DEF_  "U_P558_MY17_Gas_Tx" "No";
BA_DEF_DEF_  "U_P558_MY17_Diesel_Tx" "No";
BA_DEF_DEF_  "GenSigTimeoutTime_SCMF" 5000;
BA_DEF_DEF_  "GenSigTimeoutTime_RGTM" 5000;
BA_DEF_DEF_  "GenSigTimeoutTime_GENERIC" 5000;
BA_DEF_DEF_  "GenSigTimeoutTime_AHCM_FOH" 5000;
BA_DEF_DEF_  "GenSigTimeoutTime_RLCMA" 5000;
BA_DEF_DEF_  "GenSigTimeoutTime_BCMB" 5000;
BA_DEF_DEF_  "GenSigTimeoutTime_RHVAC" 5000;
BA_DEF_DEF_  "GenSigTimeoutTime_MRCMB" 5000;
BA_DEF_DEF_  "GenSigTimeoutTime_MRCMA" 5000;
BA_DEF_DEF_  "GenSigTimeoutTime_HVAC_RCCM" 5000;
BA_DEF_DEF_  "Gateway_ID" 0;
BA_DEF_DEF_  "GenSigTimeoutTime__delete" 5000;
BA_DEF_DEF_  "GenSigTimeoutTime_APIM" 5000;
BA_DEF_DEF_  "GenSigTimeoutTime_Generic_BCM" 5000;
BA_DEF_DEF_  "GenSigTimeoutTime_RSM" 5000;
BA_DEF_DEF_  "GenSigTimeoutTime_PDM" 5000;
BA_DEF_DEF_  "GenSigTimeoutTime_TRM" 5000;
BA_DEF_DEF_  "GenSigTimeoutTime_SCMG" 5000;
BA_DEF_DEF_  "GenSigTimeoutTime_SCMH" 5000;
BA_DEF_DEF_  "GenSigTimeoutTime_RTM" 5000;
BA_DEF_DEF_  "GenSigTimeoutTime_GWM" 5000;
BA_DEF_DEF_  "GenSigTimeoutTime_FCIM" 5000;
BA_DEF_DEF_  "GenSigTimeoutTime_HSWM" 5000;
BA_DEF_DEF_  "GenSigTimeoutTime_GPSM" 5000;
BA_DEF_DEF_  "GenSigTimeoutTime_RBM" 5000;
BA_DEF_DEF_  "GenSigTimeoutTime_DDM" 5000;
BA_DEF_DEF_  "GenSigTimeoutTime_DSM" 5000;
BA_DEF_DEF_  "GenSigTimeoutTime_SODR" 5000;
BA_DEF_DEF_  "GenSigTimeoutTime_SODL" 5000;
BA_DEF_DEF_  "GenSigTimeoutTime_TSTR" 5000;
BA_DEF_DEF_  "GenSigTimeoutTime_SCME" 5000;
BA_DEF_DEF_  "FrameGatewayMS1" 0;
BA_DEF_DEF_  "FrameGatewayHS3" 0;
BA_DEF_DEF_  "FrameGatewayHS2" 0;
BA_DEF_DEF_  "FrameGatewayHS1" 0;
BA_DEF_DEF_  "NetworkInitialization" "No";
BA_DEF_DEF_  "FrameGatewayId" 0;
BA_DEF_DEF_  "EventRateOfChange" 10000;
BA_DEF_DEF_  "GenMsgStartDelayTime" 0;
BA_DEF_DEF_  "GenMsgNrOfRepetition" 1;
BA_DEF_DEF_  "GenMsgDelayTime" 20;
BA_DEF_DEF_  "GenMsgCycleTime" 0;
BA_DEF_DEF_  "GenMsgSendType" "NoMsgSendType";
BA_DEF_DEF_  "U_CD4_MY14_Phev_Tx" "No";
BA_DEF_DEF_  "U_CD4_MY14_Hev_Tx" "No";
BA_DEF_DEF_  "U_CD4_MY14_Gas_Tx" "No";
BA_DEF_DEF_  "U_CD4_MY14_Diesel_Tx" "No";
BA_DEF_DEF_  "U_CD43_MY16_Gas_Tx" "No";
BA_DEF_DEF_  "U_UP375_MY15_Diesel_Tx" "No";
BA_DEF_DEF_  "U_UP375_MY15_Gas_Tx" "No";
BA_DEF_DEF_  "U_U502_MY15_Gas_Tx" "No";
BA_DEF_DEF_  "U_B562LC_MY14_Gas_Tx" "No";
BA_DEF_DEF_  "U_B562LC_MY14_Diesel_Tx" "No";
BA_DEF_DEF_  "U_C489_MY14_Gas_Tx" "No";
BA_DEF_DEF_  "U_S550_MY15_Gas_Tx" "No";
BA_DEF_DEF_  "U_P552_MY15_Gas_Tx" "No";
BA_DEF_DEF_  "U_CD42_MY14_Gas_Tx" "No";
BA_DEF_DEF_  "U_CD42_MY14_Diesel_Tx" "No";
BA_DEF_DEF_  "U_CD4_MY13_Phev_Tx" "No";
BA_DEF_DEF_  "U_CD4_MY13_Hev_Tx" "No";
BA_DEF_DEF_  "U_CD4_MY13_Gas_Tx" "No";
BA_DEF_DEF_  "U_CD4_MY13_Diesel_Tx" "No";
BA_DEF_DEF_  "U_CD4_MY14_Phev_Rx" "No";
BA_DEF_DEF_  "U_CD4_MY14_Hev_Rx" "No";
BA_DEF_DEF_  "U_CD4_MY14_Gas_Rx" "No";
BA_DEF_DEF_  "U_CD4_MY14_Diesel_Rx" "No";
BA_DEF_DEF_  "U_CD43_MY16_Gas_Rx" "No";
BA_DEF_DEF_  "U_UP375_MY15_Diesel_Rx" "No";
BA_DEF_DEF_  "U_UP375_MY15_Gas_Rx" "No";
BA_DEF_DEF_  "U_B479_MY15_Gas_Rx" "No";
BA_DEF_DEF_  "U_U502_MY15_Gas_Rx" "No";
BA_DEF_DEF_  "U_B562LC_MY14_Gas_Rx" "No";
BA_DEF_DEF_  "U_B562LC_MY14_Diesel_Rx" "No";
BA_DEF_DEF_  "U_C489_MY14_Gas_Rx" "No";
BA_DEF_DEF_  "U_S550_MY15_Gas_Rx" "No";
BA_DEF_DEF_  "U_P552_MY15_Gas_Rx" "No";
BA_DEF_DEF_  "U_CD42_MY14_Gas_Rx" "No";
BA_DEF_DEF_  "U_CD42_MY14_Diesel_Rx" "No";
BA_DEF_DEF_  "U_CD4_MY13_Phev_Rx" "No";
BA_DEF_DEF_  "U_CD4_MY13_Hev_Rx" "No";
BA_DEF_DEF_  "U_CD4_MY13_Gas_Rx" "No";
BA_DEF_DEF_  "U_CD4_MY13_Diesel_Rx" "No";
BA_DEF_DEF_  "ContentDependant" "No";
BA_DEF_DEF_  "GenSigStartValue" 0;
BA_DEF_DEF_  "UsedOnPgmDBC" "Yes";
BA_DEF_DEF_  "CrossOver_LIN" "No";
BA_DEF_DEF_  "CrossOver_InfoCAN" "No";
BA_DEF_DEF_  "WakeupSignal" "No";
BA_DEF_DEF_  "FMC_SIG_SSPEC" "Unknown";
BA_DEF_DEF_  "GenSigMissingSourceValue" 0;
BA_DEF_DEF_  "GenSigInactiveValue" 0;
BA_DEF_DEF_  "GenSigSendType" "NoSigSendType";
BA_DEF_DEF_  "DiagState" "No";
BA_DEF_DEF_  "TpTxIndex" 0;
BA_DEF_DEF_  "DiagRequest" "No";
BA_DEF_DEF_  "DiagResponse" "No";
BA_DEF_DEF_  "NmMessage" "No";
BA_DEF_DEF_  "GenMsgILSupport" "Yes";
BA_ "NetworkInitialization" BO_ 993 1;
BA_ "GenMsgSendType" BO_ 993 5;
BA_ "GenMsgCycleTime" BO_ 993 1000;
BA_ "GenMsgStartDelayTime" BO_ 993 100;
BA_ "GenMsgILSupport" BO_ 1881 0;
BA_ "DiagResponse" BO_ 1881 1;
BA_ "GenMsgSendType" BO_ 1881 1;
BA_ "GenMsgDelayTime" BO_ 1881 0;
BA_ "GenMsgILSupport" BO_ 1873 0;
BA_ "DiagRequest" BO_ 1873 1;
BA_ "GenMsgSendType" BO_ 1873 1;
BA_ "GenMsgDelayTime" BO_ 1873 0;
BA_ "GenMsgILSupport" BO_ 2015 0;
BA_ "DiagState" BO_ 2015 1;
BA_ "GenMsgSendType" BO_ 2015 1;
BA_ "GenMsgDelayTime" BO_ 2015 0;
BA_ "GenMsgSendType" BO_ 806 0;
BA_ "GenMsgCycleTime" BO_ 806 100;
BA_ "FrameGatewayNetwork" BO_ 950 "HS1_CAN";
BA_ "FrameGatewayId" BO_ 950 950;
BA_ "FrameGatewayHS1" BO_ 950 950;
BA_ "FrameGatewayNetwork" BO_ 857 "HS3_CAN";
BA_ "FrameGatewayId" BO_ 857 867;
BA_ "FrameGatewayHS3" BO_ 857 867;
BA_ "FrameGatewayNetwork" BO_ 856 "HS3_CAN";
BA_ "FrameGatewayId" BO_ 856 866;
BA_ "FrameGatewayHS3" BO_ 856 866;
BA_ "GenMsgSendType" BO_ 854 5;
BA_ "GenMsgCycleTime" BO_ 854 1000;
BA_ "GenMsgILSupport" BO_ 1959 0;
BA_ "DiagRequest" BO_ 1959 1;
BA_ "GenMsgSendType" BO_ 1959 1;
BA_ "GenMsgDelayTime" BO_ 1959 0;
BA_ "GenMsgILSupport" BO_ 1967 0;
BA_ "DiagResponse" BO_ 1967 1;
BA_ "GenMsgSendType" BO_ 1967 1;
BA_ "GenMsgDelayTime" BO_ 1967 0;
BA_ "FrameGatewayNetwork" BO_ 534 "HS2_CAN";
BA_ "GenMsgDelayTime" BO_ 534 10;
BA_ "FrameGatewayId" BO_ 534 534;
BA_ "FrameGatewayHS2" BO_ 534 534;
BA_ "GenMsgILSupport" BO_ 2008 0;
BA_ "DiagResponse" BO_ 2008 1;
BA_ "GenMsgSendType" BO_ 2008 1;
BA_ "GenMsgDelayTime" BO_ 2008 0;
BA_ "GenMsgSendType" BO_ 772 5;
BA_ "GenMsgCycleTime" BO_ 772 1000;
BA_ "NetworkInitialization" BO_ 935 1;
BA_ "GenMsgSendType" BO_ 935 5;
BA_ "GenMsgCycleTime" BO_ 935 200;
BA_ "NetworkInitialization" BO_ 934 1;
BA_ "GenMsgSendType" BO_ 934 5;
BA_ "GenMsgCycleTime" BO_ 934 200;
BA_ "GenMsgSendType" BO_ 1070 0;
BA_ "GenMsgCycleTime" BO_ 1070 50;
BA_ "GenMsgSendType" BO_ 1050 5;
BA_ "GenMsgCycleTime" BO_ 1050 1000;
BA_ "GenMsgILSupport" BO_ 1856 0;
BA_ "DiagRequest" BO_ 1856 1;
BA_ "GenMsgSendType" BO_ 1856 1;
BA_ "GenMsgDelayTime" BO_ 1856 0;
BA_ "GenMsgILSupport" BO_ 1864 0;
BA_ "DiagResponse" BO_ 1864 1;
BA_ "GenMsgSendType" BO_ 1864 1;
BA_ "GenMsgDelayTime" BO_ 1864 0;
BA_ "GenMsgILSupport" BO_ 1937 0;
BA_ "DiagRequest" BO_ 1937 1;
BA_ "GenMsgSendType" BO_ 1937 1;
BA_ "GenMsgDelayTime" BO_ 1937 0;
BA_ "GenMsgILSupport" BO_ 1364 0;
BA_ "NmMessage" BO_ 1364 1;
BA_ "GenMsgSendType" BO_ 1364 1;
BA_ "NetworkInitialization" BO_ 947 1;
BA_ "FrameGatewayNetwork" BO_ 947 "HS1_CAN";
BA_ "FrameGatewayId" BO_ 947 947;
BA_ "FrameGatewayHS1" BO_ 947 947;
BA_ "GenMsgSendType" BO_ 293 5;
BA_ "GenMsgCycleTime" BO_ 293 1000;
BA_ "GenSigSendType" SG_ 993 EmButtn_D_Stat 3;
BA_ "U_U55x_MY18_Gas_Tx" SG_ 993 EmButtn_D_Stat 1;
BA_ "CrossOver_InfoCAN" SG_ 993 PersStore_D_Actl 1;
BA_ "GenSigSendType" SG_ 993 PersStore_D_Actl 3;
BA_ "U_CD4_MY13_Diesel_Tx" SG_ 993 PersStore_D_Actl 1;
BA_ "U_CD4_MY13_Gas_Tx" SG_ 993 PersStore_D_Actl 1;
BA_ "U_CD4_MY13_Hev_Tx" SG_ 993 PersStore_D_Actl 1;
BA_ "U_CD4_MY13_Phev_Tx" SG_ 993 PersStore_D_Actl 1;
BA_ "U_CD42_MY14_Diesel_Tx" SG_ 993 PersStore_D_Actl 1;
BA_ "U_CD42_MY14_Gas_Tx" SG_ 993 PersStore_D_Actl 1;
BA_ "U_P552_MY15_Gas_Tx" SG_ 993 PersStore_D_Actl 1;
BA_ "U_S550_MY15_Gas_Tx" SG_ 993 PersStore_D_Actl 1;
BA_ "U_C489_MY14_Gas_Tx" SG_ 993 PersStore_D_Actl 1;
BA_ "U_U502_MY15_Gas_Tx" SG_ 993 PersStore_D_Actl 1;
BA_ "U_CD43_MY16_Gas_Tx" SG_ 993 PersStore_D_Actl 1;
BA_ "WakeupSignal" SG_ 993 MemSwtch_D_RqRecall 1;
BA_ "CrossOver_InfoCAN" SG_ 993 MemSwtch_D_RqRecall 1;
BA_ "GenSigSendType" SG_ 993 MemSwtch_D_RqRecall 3;
BA_ "U_CD4_MY13_Diesel_Rx" SG_ 993 MemSwtch_D_RqRecall 1;
BA_ "U_CD4_MY13_Gas_Rx" SG_ 993 MemSwtch_D_RqRecall 1;
BA_ "U_CD4_MY13_Hev_Rx" SG_ 993 MemSwtch_D_RqRecall 1;
BA_ "U_CD4_MY13_Phev_Rx" SG_ 993 MemSwtch_D_RqRecall 1;
BA_ "U_CD42_MY14_Diesel_Rx" SG_ 993 MemSwtch_D_RqRecall 1;
BA_ "U_CD42_MY14_Gas_Rx" SG_ 993 MemSwtch_D_RqRecall 1;
BA_ "U_P552_MY15_Gas_Rx" SG_ 993 MemSwtch_D_RqRecall 1;
BA_ "U_S550_MY15_Gas_Rx" SG_ 993 MemSwtch_D_RqRecall 1;
BA_ "U_C489_MY14_Gas_Rx" SG_ 993 MemSwtch_D_RqRecall 1;
BA_ "U_U502_MY15_Gas_Rx" SG_ 993 MemSwtch_D_RqRecall 1;
BA_ "U_B479_MY15_Gas_Rx" SG_ 993 MemSwtch_D_RqRecall 1;
BA_ "U_UP375_MY15_Gas_Rx" SG_ 993 MemSwtch_D_RqRecall 1;
BA_ "U_UP375_MY15_Diesel_Rx" SG_ 993 MemSwtch_D_RqRecall 1;
BA_ "U_CD4_MY13_Diesel_Tx" SG_ 993 MemSwtch_D_RqRecall 1;
BA_ "U_CD4_MY13_Gas_Tx" SG_ 993 MemSwtch_D_RqRecall 1;
BA_ "U_CD4_MY13_Hev_Tx" SG_ 993 MemSwtch_D_RqRecall 1;
BA_ "U_CD4_MY13_Phev_Tx" SG_ 993 MemSwtch_D_RqRecall 1;
BA_ "U_CD42_MY14_Diesel_Tx" SG_ 993 MemSwtch_D_RqRecall 1;
BA_ "U_CD42_MY14_Gas_Tx" SG_ 993 MemSwtch_D_RqRecall 1;
BA_ "U_P552_MY15_Gas_Tx" SG_ 993 MemSwtch_D_RqRecall 1;
BA_ "U_S550_MY15_Gas_Tx" SG_ 993 MemSwtch_D_RqRecall 1;
BA_ "U_C489_MY14_Gas_Tx" SG_ 993 MemSwtch_D_RqRecall 1;
BA_ "U_U502_MY15_Gas_Tx" SG_ 993 MemSwtch_D_RqRecall 1;
BA_ "U_CD43_MY16_Gas_Tx" SG_ 993 MemSwtch_D_RqRecall 1;
BA_ "WakeupSignal" SG_ 993 MemSwtch_D_RqAssoc 1;
BA_ "CrossOver_InfoCAN" SG_ 993 MemSwtch_D_RqAssoc 1;
BA_ "GenSigSendType" SG_ 993 MemSwtch_D_RqAssoc 3;
BA_ "U_CD4_MY13_Diesel_Rx" SG_ 993 MemSwtch_D_RqAssoc 1;
BA_ "U_CD4_MY13_Gas_Rx" SG_ 993 MemSwtch_D_RqAssoc 1;
BA_ "U_CD4_MY13_Hev_Rx" SG_ 993 MemSwtch_D_RqAssoc 1;
BA_ "U_CD4_MY13_Phev_Rx" SG_ 993 MemSwtch_D_RqAssoc 1;
BA_ "U_CD42_MY14_Diesel_Rx" SG_ 993 MemSwtch_D_RqAssoc 1;
BA_ "U_CD42_MY14_Gas_Rx" SG_ 993 MemSwtch_D_RqAssoc 1;
BA_ "U_P552_MY15_Gas_Rx" SG_ 993 MemSwtch_D_RqAssoc 1;
BA_ "U_S550_MY15_Gas_Rx" SG_ 993 MemSwtch_D_RqAssoc 1;
BA_ "U_C489_MY14_Gas_Rx" SG_ 993 MemSwtch_D_RqAssoc 1;
BA_ "U_U502_MY15_Gas_Rx" SG_ 993 MemSwtch_D_RqAssoc 1;
BA_ "U_B479_MY15_Gas_Rx" SG_ 993 MemSwtch_D_RqAssoc 1;
BA_ "U_UP375_MY15_Gas_Rx" SG_ 993 MemSwtch_D_RqAssoc 1;
BA_ "U_UP375_MY15_Diesel_Rx" SG_ 993 MemSwtch_D_RqAssoc 1;
BA_ "U_CD4_MY13_Diesel_Tx" SG_ 993 MemSwtch_D_RqAssoc 1;
BA_ "U_CD4_MY13_Gas_Tx" SG_ 993 MemSwtch_D_RqAssoc 1;
BA_ "U_CD4_MY13_Hev_Tx" SG_ 993 MemSwtch_D_RqAssoc 1;
BA_ "U_CD4_MY13_Phev_Tx" SG_ 993 MemSwtch_D_RqAssoc 1;
BA_ "U_CD42_MY14_Diesel_Tx" SG_ 993 MemSwtch_D_RqAssoc 1;
BA_ "U_CD42_MY14_Gas_Tx" SG_ 993 MemSwtch_D_RqAssoc 1;
BA_ "U_P552_MY15_Gas_Tx" SG_ 993 MemSwtch_D_RqAssoc 1;
BA_ "U_S550_MY15_Gas_Tx" SG_ 993 MemSwtch_D_RqAssoc 1;
BA_ "U_C489_MY14_Gas_Tx" SG_ 993 MemSwtch_D_RqAssoc 1;
BA_ "U_U502_MY15_Gas_Tx" SG_ 993 MemSwtch_D_RqAssoc 1;
BA_ "U_CD43_MY16_Gas_Tx" SG_ 993 MemSwtch_D_RqAssoc 1;
BA_ "CrossOver_InfoCAN" SG_ 993 PersIndexDsm_D_Actl 1;
BA_ "GenSigStartValue" SG_ 993 PersIndexDsm_D_Actl 4;
BA_ "GenSigSendType" SG_ 993 PersIndexDsm_D_Actl 3;
BA_ "U_CD4_MY13_Diesel_Tx" SG_ 993 PersIndexDsm_D_Actl 1;
BA_ "U_CD4_MY13_Gas_Tx" SG_ 993 PersIndexDsm_D_Actl 1;
BA_ "U_CD4_MY13_Hev_Tx" SG_ 993 PersIndexDsm_D_Actl 1;
BA_ "U_CD4_MY13_Phev_Tx" SG_ 993 PersIndexDsm_D_Actl 1;
BA_ "U_CD42_MY14_Diesel_Tx" SG_ 993 PersIndexDsm_D_Actl 1;
BA_ "U_CD42_MY14_Gas_Tx" SG_ 993 PersIndexDsm_D_Actl 1;
BA_ "U_P552_MY15_Gas_Tx" SG_ 993 PersIndexDsm_D_Actl 1;
BA_ "U_S550_MY15_Gas_Tx" SG_ 993 PersIndexDsm_D_Actl 1;
BA_ "U_C489_MY14_Gas_Tx" SG_ 993 PersIndexDsm_D_Actl 1;
BA_ "U_U502_MY15_Gas_Tx" SG_ 993 PersIndexDsm_D_Actl 1;
BA_ "U_CD43_MY16_Gas_Tx" SG_ 993 PersIndexDsm_D_Actl 1;
BA_ "CrossOver_InfoCAN" SG_ 993 FeatNoDsmActl 1;
BA_ "GenSigSendType" SG_ 993 FeatNoDsmActl 3;
BA_ "U_CD4_MY13_Diesel_Tx" SG_ 993 FeatNoDsmActl 1;
BA_ "U_CD4_MY13_Gas_Tx" SG_ 993 FeatNoDsmActl 1;
BA_ "U_CD4_MY13_Hev_Tx" SG_ 993 FeatNoDsmActl 1;
BA_ "U_CD4_MY13_Phev_Tx" SG_ 993 FeatNoDsmActl 1;
BA_ "U_CD42_MY14_Diesel_Tx" SG_ 993 FeatNoDsmActl 1;
BA_ "U_CD42_MY14_Gas_Tx" SG_ 993 FeatNoDsmActl 1;
BA_ "U_P552_MY15_Gas_Tx" SG_ 993 FeatNoDsmActl 1;
BA_ "U_S550_MY15_Gas_Tx" SG_ 993 FeatNoDsmActl 1;
BA_ "U_C489_MY14_Gas_Tx" SG_ 993 FeatNoDsmActl 1;
BA_ "U_U502_MY15_Gas_Tx" SG_ 993 FeatNoDsmActl 1;
BA_ "U_CD43_MY16_Gas_Tx" SG_ 993 FeatNoDsmActl 1;
BA_ "CrossOver_InfoCAN" SG_ 993 FeatConfigDsmActl 1;
BA_ "GenSigSendType" SG_ 993 FeatConfigDsmActl 3;
BA_ "U_CD4_MY13_Diesel_Tx" SG_ 993 FeatConfigDsmActl 1;
BA_ "U_CD4_MY13_Gas_Tx" SG_ 993 FeatConfigDsmActl 1;
BA_ "U_CD4_MY13_Hev_Tx" SG_ 993 FeatConfigDsmActl 1;
BA_ "U_CD4_MY13_Phev_Tx" SG_ 993 FeatConfigDsmActl 1;
BA_ "U_CD42_MY14_Diesel_Tx" SG_ 993 FeatConfigDsmActl 1;
BA_ "U_CD42_MY14_Gas_Tx" SG_ 993 FeatConfigDsmActl 1;
BA_ "U_P552_MY15_Gas_Tx" SG_ 993 FeatConfigDsmActl 1;
BA_ "U_S550_MY15_Gas_Tx" SG_ 993 FeatConfigDsmActl 1;
BA_ "U_C489_MY14_Gas_Tx" SG_ 993 FeatConfigDsmActl 1;
BA_ "U_U502_MY15_Gas_Tx" SG_ 993 FeatConfigDsmActl 1;
BA_ "U_CD43_MY16_Gas_Tx" SG_ 993 FeatConfigDsmActl 1;
BA_ "GenSigSendType" SG_ 1881 TesterPhysicalResRTM 3;
BA_ "U_CD4_MY13_Diesel_Tx" SG_ 1881 TesterPhysicalResRTM 1;
BA_ "U_CD4_MY13_Gas_Tx" SG_ 1881 TesterPhysicalResRTM 1;
BA_ "U_CD4_MY13_Hev_Tx" SG_ 1881 TesterPhysicalResRTM 1;
BA_ "U_CD4_MY13_Phev_Tx" SG_ 1881 TesterPhysicalResRTM 1;
BA_ "U_CD42_MY14_Diesel_Tx" SG_ 1881 TesterPhysicalResRTM 1;
BA_ "U_CD42_MY14_Gas_Tx" SG_ 1881 TesterPhysicalResRTM 1;
BA_ "U_P552_MY15_Gas_Tx" SG_ 1881 TesterPhysicalResRTM 1;
BA_ "U_S550_MY15_Gas_Tx" SG_ 1881 TesterPhysicalResRTM 1;
BA_ "U_C489_MY14_Gas_Tx" SG_ 1881 TesterPhysicalResRTM 1;
BA_ "U_U502_MY15_Gas_Tx" SG_ 1881 TesterPhysicalResRTM 1;
BA_ "U_UP375_MY15_Gas_Tx" SG_ 1881 TesterPhysicalResRTM 1;
BA_ "U_UP375_MY15_Diesel_Tx" SG_ 1881 TesterPhysicalResRTM 1;
BA_ "U_CD43_MY16_Gas_Tx" SG_ 1881 TesterPhysicalResRTM 1;
BA_ "GenSigSendType" SG_ 1873 TesterPhysicalReqRTM 3;
BA_ "U_CD4_MY13_Diesel_Rx" SG_ 1873 TesterPhysicalReqRTM 1;
BA_ "U_CD4_MY13_Gas_Rx" SG_ 1873 TesterPhysicalReqRTM 1;
BA_ "U_CD4_MY13_Hev_Rx" SG_ 1873 TesterPhysicalReqRTM 1;
BA_ "U_CD4_MY13_Phev_Rx" SG_ 1873 TesterPhysicalReqRTM 1;
BA_ "U_CD42_MY14_Diesel_Rx" SG_ 1873 TesterPhysicalReqRTM 1;
BA_ "U_CD42_MY14_Gas_Rx" SG_ 1873 TesterPhysicalReqRTM 1;
BA_ "U_P552_MY15_Gas_Rx" SG_ 1873 TesterPhysicalReqRTM 1;
BA_ "U_S550_MY15_Gas_Rx" SG_ 1873 TesterPhysicalReqRTM 1;
BA_ "U_C489_MY14_Gas_Rx" SG_ 1873 TesterPhysicalReqRTM 1;
BA_ "U_U502_MY15_Gas_Rx" SG_ 1873 TesterPhysicalReqRTM 1;
BA_ "U_UP375_MY15_Gas_Rx" SG_ 1873 TesterPhysicalReqRTM 1;
BA_ "U_UP375_MY15_Diesel_Rx" SG_ 1873 TesterPhysicalReqRTM 1;
BA_ "U_CD43_MY16_Gas_Rx" SG_ 1873 TesterPhysicalReqRTM 1;
BA_ "CrossOver_InfoCAN" SG_ 2015 TesterFunctionalReq 1;
BA_ "GenSigSendType" SG_ 2015 TesterFunctionalReq 3;
BA_ "U_CD4_MY13_Diesel_Rx" SG_ 2015 TesterFunctionalReq 1;
BA_ "U_CD4_MY13_Gas_Rx" SG_ 2015 TesterFunctionalReq 1;
BA_ "U_CD4_MY13_Hev_Rx" SG_ 2015 TesterFunctionalReq 1;
BA_ "U_CD4_MY13_Phev_Rx" SG_ 2015 TesterFunctionalReq 1;
BA_ "U_CD42_MY14_Diesel_Rx" SG_ 2015 TesterFunctionalReq 1;
BA_ "U_CD42_MY14_Gas_Rx" SG_ 2015 TesterFunctionalReq 1;
BA_ "U_P552_MY15_Gas_Rx" SG_ 2015 TesterFunctionalReq 1;
BA_ "U_S550_MY15_Gas_Rx" SG_ 2015 TesterFunctionalReq 1;
BA_ "U_C489_MY14_Gas_Rx" SG_ 2015 TesterFunctionalReq 1;
BA_ "U_B562LC_MY14_Gas_Rx" SG_ 2015 TesterFunctionalReq 1;
BA_ "U_U502_MY15_Gas_Rx" SG_ 2015 TesterFunctionalReq 1;
BA_ "U_UP375_MY15_Gas_Rx" SG_ 2015 TesterFunctionalReq 1;
BA_ "U_UP375_MY15_Diesel_Rx" SG_ 2015 TesterFunctionalReq 1;
BA_ "U_CD43_MY16_Gas_Rx" SG_ 2015 TesterFunctionalReq 1;
BA_ "U_CD4_MY14_Diesel_Rx" SG_ 2015 TesterFunctionalReq 1;
BA_ "U_CD4_MY14_Gas_Rx" SG_ 2015 TesterFunctionalReq 1;
BA_ "U_CD4_MY14_Hev_Rx" SG_ 2015 TesterFunctionalReq 1;
BA_ "U_CD4_MY14_Phev_Rx" SG_ 2015 TesterFunctionalReq 1;
BA_ "Gateway_ID" SG_ 806 SnowPlowMde_B_Enbl 27631;
BA_ "GenSigStartValue" SG_ 806 ClimtDeltaLoad_Pw_Actl 32;
BA_ "U_P552_MY15_Gas_Tx" SG_ 806 ClimtDeltaLoad_Pw_Actl 1;
BA_ "U_CD43_MY16_Gas_Tx" SG_ 806 ClimtDeltaLoad_Pw_Actl 1;
BA_ "U_CD4_MY13_Diesel_Tx" SG_ 806 StopStrtDrvMde_B_RqBtn 1;
BA_ "U_CD4_MY13_Gas_Tx" SG_ 806 StopStrtDrvMde_B_RqBtn 1;
BA_ "U_CD4_MY13_Hev_Tx" SG_ 806 StopStrtDrvMde_B_RqBtn 1;
BA_ "U_CD4_MY13_Phev_Tx" SG_ 806 StopStrtDrvMde_B_RqBtn 1;
BA_ "U_CD42_MY14_Diesel_Tx" SG_ 806 StopStrtDrvMde_B_RqBtn 1;
BA_ "U_CD42_MY14_Gas_Tx" SG_ 806 StopStrtDrvMde_B_RqBtn 1;
BA_ "U_P552_MY15_Gas_Tx" SG_ 806 StopStrtDrvMde_B_RqBtn 1;
BA_ "U_U502_MY15_Gas_Tx" SG_ 806 StopStrtDrvMde_B_RqBtn 1;
BA_ "U_UP375_MY15_Gas_Tx" SG_ 806 StopStrtDrvMde_B_RqBtn 1;
BA_ "U_UP375_MY15_Diesel_Tx" SG_ 806 StopStrtDrvMde_B_RqBtn 1;
BA_ "U_CD43_MY16_Gas_Tx" SG_ 806 StopStrtDrvMde_B_RqBtn 1;
BA_ "U_CD4_MY13_Diesel_Tx" SG_ 806 ClimtHeat_D_Rq 1;
BA_ "U_CD4_MY13_Gas_Tx" SG_ 806 ClimtHeat_D_Rq 1;
BA_ "U_CD4_MY13_Hev_Tx" SG_ 806 ClimtHeat_D_Rq 1;
BA_ "U_CD4_MY13_Phev_Tx" SG_ 806 ClimtHeat_D_Rq 1;
BA_ "U_CD42_MY14_Diesel_Tx" SG_ 806 ClimtHeat_D_Rq 1;
BA_ "U_CD42_MY14_Gas_Tx" SG_ 806 ClimtHeat_D_Rq 1;
BA_ "U_P552_MY15_Gas_Tx" SG_ 806 ClimtHeat_D_Rq 1;
BA_ "U_U502_MY15_Gas_Tx" SG_ 806 ClimtHeat_D_Rq 1;
BA_ "U_UP375_MY15_Gas_Tx" SG_ 806 ClimtHeat_D_Rq 1;
BA_ "U_UP375_MY15_Diesel_Tx" SG_ 806 ClimtHeat_D_Rq 1;
BA_ "U_CD43_MY16_Gas_Tx" SG_ 806 ClimtHeat_D_Rq 1;
BA_ "U_CD4_MY13_Diesel_Tx" SG_ 806 ClimtCool_D_Rq 1;
BA_ "U_CD4_MY13_Gas_Tx" SG_ 806 ClimtCool_D_Rq 1;
BA_ "U_CD4_MY13_Hev_Tx" SG_ 806 ClimtCool_D_Rq 1;
BA_ "U_CD4_MY13_Phev_Tx" SG_ 806 ClimtCool_D_Rq 1;
BA_ "U_CD42_MY14_Diesel_Tx" SG_ 806 ClimtCool_D_Rq 1;
BA_ "U_CD42_MY14_Gas_Tx" SG_ 806 ClimtCool_D_Rq 1;
BA_ "U_P552_MY15_Gas_Tx" SG_ 806 ClimtCool_D_Rq 1;
BA_ "U_U502_MY15_Gas_Tx" SG_ 806 ClimtCool_D_Rq 1;
BA_ "U_UP375_MY15_Gas_Tx" SG_ 806 ClimtCool_D_Rq 1;
BA_ "U_UP375_MY15_Diesel_Tx" SG_ 806 ClimtCool_D_Rq 1;
BA_ "U_CD43_MY16_Gas_Tx" SG_ 806 ClimtCool_D_Rq 1;
BA_ "GenSigStartValue" SG_ 806 HvacEvap_Te_Rq 400;
BA_ "U_CD4_MY13_Diesel_Tx" SG_ 806 HvacEvap_Te_Rq 1;
BA_ "U_CD4_MY13_Gas_Tx" SG_ 806 HvacEvap_Te_Rq 1;
BA_ "U_CD4_MY13_Hev_Tx" SG_ 806 HvacEvap_Te_Rq 1;
BA_ "U_CD4_MY13_Phev_Tx" SG_ 806 HvacEvap_Te_Rq 1;
BA_ "U_CD42_MY14_Diesel_Tx" SG_ 806 HvacEvap_Te_Rq 1;
BA_ "U_CD42_MY14_Gas_Tx" SG_ 806 HvacEvap_Te_Rq 1;
BA_ "U_P552_MY15_Gas_Tx" SG_ 806 HvacEvap_Te_Rq 1;
BA_ "U_S550_MY15_Gas_Tx" SG_ 806 HvacEvap_Te_Rq 1;
BA_ "U_C489_MY14_Gas_Tx" SG_ 806 HvacEvap_Te_Rq 1;
BA_ "U_U502_MY15_Gas_Tx" SG_ 806 HvacEvap_Te_Rq 1;
BA_ "U_UP375_MY15_Gas_Tx" SG_ 806 HvacEvap_Te_Rq 1;
BA_ "U_UP375_MY15_Diesel_Tx" SG_ 806 HvacEvap_Te_Rq 1;
BA_ "U_CD43_MY16_Gas_Tx" SG_ 806 HvacEvap_Te_Rq 1;
BA_ "GenSigStartValue" SG_ 806 HvacEvap_Te_Actl 400;
BA_ "U_CD4_MY13_Diesel_Tx" SG_ 806 HvacEvap_Te_Actl 1;
BA_ "U_CD4_MY13_Gas_Tx" SG_ 806 HvacEvap_Te_Actl 1;
BA_ "U_CD4_MY13_Hev_Tx" SG_ 806 HvacEvap_Te_Actl 1;
BA_ "U_CD4_MY13_Phev_Tx" SG_ 806 HvacEvap_Te_Actl 1;
BA_ "U_CD42_MY14_Diesel_Tx" SG_ 806 HvacEvap_Te_Actl 1;
BA_ "U_CD42_MY14_Gas_Tx" SG_ 806 HvacEvap_Te_Actl 1;
BA_ "U_P552_MY15_Gas_Tx" SG_ 806 HvacEvap_Te_Actl 1;
BA_ "U_S550_MY15_Gas_Tx" SG_ 806 HvacEvap_Te_Actl 1;
BA_ "U_C489_MY14_Gas_Tx" SG_ 806 HvacEvap_Te_Actl 1;
BA_ "U_U502_MY15_Gas_Tx" SG_ 806 HvacEvap_Te_Actl 1;
BA_ "U_UP375_MY15_Gas_Tx" SG_ 806 HvacEvap_Te_Actl 1;
BA_ "U_UP375_MY15_Diesel_Tx" SG_ 806 HvacEvap_Te_Actl 1;
BA_ "U_CD43_MY16_Gas_Tx" SG_ 806 HvacEvap_Te_Actl 1;
BA_ "U_CD4_MY13_Diesel_Tx" SG_ 806 HvacAirCond_B_Rq 1;
BA_ "U_CD4_MY13_Gas_Tx" SG_ 806 HvacAirCond_B_Rq 1;
BA_ "U_CD4_MY13_Hev_Tx" SG_ 806 HvacAirCond_B_Rq 1;
BA_ "U_CD4_MY13_Phev_Tx" SG_ 806 HvacAirCond_B_Rq 1;
BA_ "U_CD42_MY14_Diesel_Tx" SG_ 806 HvacAirCond_B_Rq 1;
BA_ "U_CD42_MY14_Gas_Tx" SG_ 806 HvacAirCond_B_Rq 1;
BA_ "U_P552_MY15_Gas_Tx" SG_ 806 HvacAirCond_B_Rq 1;
BA_ "U_S550_MY15_Gas_Tx" SG_ 806 HvacAirCond_B_Rq 1;
BA_ "U_C489_MY14_Gas_Tx" SG_ 806 HvacAirCond_B_Rq 1;
BA_ "U_U502_MY15_Gas_Tx" SG_ 806 HvacAirCond_B_Rq 1;
BA_ "U_UP375_MY15_Gas_Tx" SG_ 806 HvacAirCond_B_Rq 1;
BA_ "U_UP375_MY15_Diesel_Tx" SG_ 806 HvacAirCond_B_Rq 1;
BA_ "U_CD43_MY16_Gas_Tx" SG_ 806 HvacAirCond_B_Rq 1;
BA_ "GenSigStartValue" SG_ 806 HvacEvap_Te_Offst 400;
BA_ "U_CD4_MY13_Diesel_Tx" SG_ 806 HvacEvap_Te_Offst 1;
BA_ "U_CD4_MY13_Gas_Tx" SG_ 806 HvacEvap_Te_Offst 1;
BA_ "U_CD4_MY13_Hev_Tx" SG_ 806 HvacEvap_Te_Offst 1;
BA_ "U_CD4_MY13_Phev_Tx" SG_ 806 HvacEvap_Te_Offst 1;
BA_ "U_CD42_MY14_Diesel_Tx" SG_ 806 HvacEvap_Te_Offst 1;
BA_ "U_CD42_MY14_Gas_Tx" SG_ 806 HvacEvap_Te_Offst 1;
BA_ "U_P552_MY15_Gas_Tx" SG_ 806 HvacEvap_Te_Offst 1;
BA_ "U_S550_MY15_Gas_Tx" SG_ 806 HvacEvap_Te_Offst 1;
BA_ "U_C489_MY14_Gas_Tx" SG_ 806 HvacEvap_Te_Offst 1;
BA_ "U_U502_MY15_Gas_Tx" SG_ 806 HvacEvap_Te_Offst 1;
BA_ "U_UP375_MY15_Gas_Tx" SG_ 806 HvacEvap_Te_Offst 1;
BA_ "U_UP375_MY15_Diesel_Tx" SG_ 806 HvacEvap_Te_Offst 1;
BA_ "U_CD43_MY16_Gas_Tx" SG_ 806 HvacEvap_Te_Offst 1;
BA_ "U_CD4_MY13_Diesel_Tx" SG_ 806 ClimtPw_B_Rq 1;
BA_ "U_CD4_MY13_Gas_Tx" SG_ 806 ClimtPw_B_Rq 1;
BA_ "U_CD4_MY13_Hev_Tx" SG_ 806 ClimtPw_B_Rq 1;
BA_ "U_CD4_MY13_Phev_Tx" SG_ 806 ClimtPw_B_Rq 1;
BA_ "U_CD42_MY14_Diesel_Tx" SG_ 806 ClimtPw_B_Rq 1;
BA_ "U_CD42_MY14_Gas_Tx" SG_ 806 ClimtPw_B_Rq 1;
BA_ "U_P552_MY15_Gas_Tx" SG_ 806 ClimtPw_B_Rq 1;
BA_ "U_U502_MY15_Gas_Tx" SG_ 806 ClimtPw_B_Rq 1;
BA_ "U_UP375_MY15_Gas_Tx" SG_ 806 ClimtPw_B_Rq 1;
BA_ "U_UP375_MY15_Diesel_Tx" SG_ 806 ClimtPw_B_Rq 1;
BA_ "U_CD43_MY16_Gas_Tx" SG_ 806 ClimtPw_B_Rq 1;
BA_ "U_CD4_MY13_Diesel_Rx" SG_ 950 RemoteKey_Info_TIC 1;
BA_ "U_CD4_MY13_Gas_Rx" SG_ 950 RemoteKey_Info_TIC 1;
BA_ "U_CD4_MY13_Hev_Rx" SG_ 950 RemoteKey_Info_TIC 1;
BA_ "U_CD4_MY13_Phev_Rx" SG_ 950 RemoteKey_Info_TIC 1;
BA_ "U_CD42_MY14_Diesel_Rx" SG_ 950 RemoteKey_Info_TIC 1;
BA_ "U_CD42_MY14_Gas_Rx" SG_ 950 RemoteKey_Info_TIC 1;
BA_ "U_P552_MY15_Gas_Rx" SG_ 950 RemoteKey_Info_TIC 1;
BA_ "U_S550_MY15_Gas_Rx" SG_ 950 RemoteKey_Info_TIC 1;
BA_ "U_C489_MY14_Gas_Rx" SG_ 950 RemoteKey_Info_TIC 1;
BA_ "U_U502_MY15_Gas_Rx" SG_ 950 RemoteKey_Info_TIC 1;
BA_ "U_UP375_MY15_Gas_Rx" SG_ 950 RemoteKey_Info_TIC 1;
BA_ "U_UP375_MY15_Diesel_Rx" SG_ 950 RemoteKey_Info_TIC 1;
BA_ "U_CD43_MY16_Gas_Rx" SG_ 950 RemoteKey_Info_TIC 1;
BA_ "U_CD4_MY13_Diesel_Rx" SG_ 950 RemoteKey_Info_MaxInd 1;
BA_ "U_CD4_MY13_Gas_Rx" SG_ 950 RemoteKey_Info_MaxInd 1;
BA_ "U_CD4_MY13_Hev_Rx" SG_ 950 RemoteKey_Info_MaxInd 1;
BA_ "U_CD4_MY13_Phev_Rx" SG_ 950 RemoteKey_Info_MaxInd 1;
BA_ "U_CD42_MY14_Diesel_Rx" SG_ 950 RemoteKey_Info_MaxInd 1;
BA_ "U_CD42_MY14_Gas_Rx" SG_ 950 RemoteKey_Info_MaxInd 1;
BA_ "U_P552_MY15_Gas_Rx" SG_ 950 RemoteKey_Info_MaxInd 1;
BA_ "U_S550_MY15_Gas_Rx" SG_ 950 RemoteKey_Info_MaxInd 1;
BA_ "U_C489_MY14_Gas_Rx" SG_ 950 RemoteKey_Info_MaxInd 1;
BA_ "U_U502_MY15_Gas_Rx" SG_ 950 RemoteKey_Info_MaxInd 1;
BA_ "U_UP375_MY15_Gas_Rx" SG_ 950 RemoteKey_Info_MaxInd 1;
BA_ "U_UP375_MY15_Diesel_Rx" SG_ 950 RemoteKey_Info_MaxInd 1;
BA_ "U_CD43_MY16_Gas_Rx" SG_ 950 RemoteKey_Info_MaxInd 1;
BA_ "U_CD4_MY13_Diesel_Rx" SG_ 950 RemoteKey_Info_Index 1;
BA_ "U_CD4_MY13_Gas_Rx" SG_ 950 RemoteKey_Info_Index 1;
BA_ "U_CD4_MY13_Hev_Rx" SG_ 950 RemoteKey_Info_Index 1;
BA_ "U_CD4_MY13_Phev_Rx" SG_ 950 RemoteKey_Info_Index 1;
BA_ "U_CD42_MY14_Diesel_Rx" SG_ 950 RemoteKey_Info_Index 1;
BA_ "U_CD42_MY14_Gas_Rx" SG_ 950 RemoteKey_Info_Index 1;
BA_ "U_P552_MY15_Gas_Rx" SG_ 950 RemoteKey_Info_Index 1;
BA_ "U_S550_MY15_Gas_Rx" SG_ 950 RemoteKey_Info_Index 1;
BA_ "U_C489_MY14_Gas_Rx" SG_ 950 RemoteKey_Info_Index 1;
BA_ "U_U502_MY15_Gas_Rx" SG_ 950 RemoteKey_Info_Index 1;
BA_ "U_UP375_MY15_Gas_Rx" SG_ 950 RemoteKey_Info_Index 1;
BA_ "U_UP375_MY15_Diesel_Rx" SG_ 950 RemoteKey_Info_Index 1;
BA_ "U_CD43_MY16_Gas_Rx" SG_ 950 RemoteKey_Info_Index 1;
BA_ "GenSigStartValue" SG_ 950 TirePress_Filter_Ctrl 2;
BA_ "U_CD4_MY13_Diesel_Rx" SG_ 950 TirePress_Filter_Ctrl 1;
BA_ "U_CD4_MY13_Gas_Rx" SG_ 950 TirePress_Filter_Ctrl 1;
BA_ "U_CD4_MY13_Hev_Rx" SG_ 950 TirePress_Filter_Ctrl 1;
BA_ "U_CD4_MY13_Phev_Rx" SG_ 950 TirePress_Filter_Ctrl 1;
BA_ "U_CD42_MY14_Diesel_Rx" SG_ 950 TirePress_Filter_Ctrl 1;
BA_ "U_CD42_MY14_Gas_Rx" SG_ 950 TirePress_Filter_Ctrl 1;
BA_ "U_P552_MY15_Gas_Rx" SG_ 950 TirePress_Filter_Ctrl 1;
BA_ "U_S550_MY15_Gas_Rx" SG_ 950 TirePress_Filter_Ctrl 1;
BA_ "U_C489_MY14_Gas_Rx" SG_ 950 TirePress_Filter_Ctrl 1;
BA_ "U_U502_MY15_Gas_Rx" SG_ 950 TirePress_Filter_Ctrl 1;
BA_ "U_UP375_MY15_Gas_Rx" SG_ 950 TirePress_Filter_Ctrl 1;
BA_ "U_UP375_MY15_Diesel_Rx" SG_ 950 TirePress_Filter_Ctrl 1;
BA_ "U_CD43_MY16_Gas_Rx" SG_ 950 TirePress_Filter_Ctrl 1;
BA_ "CrossOver_InfoCAN" SG_ 857 LHS_Temp_Disp_Digit3 1;
BA_ "U_CD4_MY13_Diesel_Rx" SG_ 857 LHS_Temp_Disp_Digit3 1;
BA_ "U_CD4_MY13_Gas_Rx" SG_ 857 LHS_Temp_Disp_Digit3 1;
BA_ "U_CD4_MY13_Hev_Rx" SG_ 857 LHS_Temp_Disp_Digit3 1;
BA_ "U_CD4_MY13_Phev_Rx" SG_ 857 LHS_Temp_Disp_Digit3 1;
BA_ "U_CD42_MY14_Diesel_Rx" SG_ 857 LHS_Temp_Disp_Digit3 1;
BA_ "U_CD42_MY14_Gas_Rx" SG_ 857 LHS_Temp_Disp_Digit3 1;
BA_ "U_P552_MY15_Gas_Rx" SG_ 857 LHS_Temp_Disp_Digit3 1;
BA_ "U_S550_MY15_Gas_Rx" SG_ 857 LHS_Temp_Disp_Digit3 1;
BA_ "U_C489_MY14_Gas_Rx" SG_ 857 LHS_Temp_Disp_Digit3 1;
BA_ "U_U502_MY15_Gas_Rx" SG_ 857 LHS_Temp_Disp_Digit3 1;
BA_ "U_UP375_MY15_Gas_Rx" SG_ 857 LHS_Temp_Disp_Digit3 1;
BA_ "U_UP375_MY15_Diesel_Rx" SG_ 857 LHS_Temp_Disp_Digit3 1;
BA_ "U_CD43_MY16_Gas_Rx" SG_ 857 LHS_Temp_Disp_Digit3 1;
BA_ "CrossOver_InfoCAN" SG_ 857 LHS_Temp_Disp_Digit2 1;
BA_ "U_CD4_MY13_Diesel_Rx" SG_ 857 LHS_Temp_Disp_Digit2 1;
BA_ "U_CD4_MY13_Gas_Rx" SG_ 857 LHS_Temp_Disp_Digit2 1;
BA_ "U_CD4_MY13_Hev_Rx" SG_ 857 LHS_Temp_Disp_Digit2 1;
BA_ "U_CD4_MY13_Phev_Rx" SG_ 857 LHS_Temp_Disp_Digit2 1;
BA_ "U_CD42_MY14_Diesel_Rx" SG_ 857 LHS_Temp_Disp_Digit2 1;
BA_ "U_CD42_MY14_Gas_Rx" SG_ 857 LHS_Temp_Disp_Digit2 1;
BA_ "U_P552_MY15_Gas_Rx" SG_ 857 LHS_Temp_Disp_Digit2 1;
BA_ "U_S550_MY15_Gas_Rx" SG_ 857 LHS_Temp_Disp_Digit2 1;
BA_ "U_C489_MY14_Gas_Rx" SG_ 857 LHS_Temp_Disp_Digit2 1;
BA_ "U_U502_MY15_Gas_Rx" SG_ 857 LHS_Temp_Disp_Digit2 1;
BA_ "U_UP375_MY15_Gas_Rx" SG_ 857 LHS_Temp_Disp_Digit2 1;
BA_ "U_UP375_MY15_Diesel_Rx" SG_ 857 LHS_Temp_Disp_Digit2 1;
BA_ "U_CD43_MY16_Gas_Rx" SG_ 857 LHS_Temp_Disp_Digit2 1;
BA_ "CrossOver_InfoCAN" SG_ 857 LHS_Temp_Disp_Digit1 1;
BA_ "U_CD4_MY13_Diesel_Rx" SG_ 857 LHS_Temp_Disp_Digit1 1;
BA_ "U_CD4_MY13_Gas_Rx" SG_ 857 LHS_Temp_Disp_Digit1 1;
BA_ "U_CD4_MY13_Hev_Rx" SG_ 857 LHS_Temp_Disp_Digit1 1;
BA_ "U_CD4_MY13_Phev_Rx" SG_ 857 LHS_Temp_Disp_Digit1 1;
BA_ "U_CD42_MY14_Diesel_Rx" SG_ 857 LHS_Temp_Disp_Digit1 1;
BA_ "U_CD42_MY14_Gas_Rx" SG_ 857 LHS_Temp_Disp_Digit1 1;
BA_ "U_P552_MY15_Gas_Rx" SG_ 857 LHS_Temp_Disp_Digit1 1;
BA_ "U_S550_MY15_Gas_Rx" SG_ 857 LHS_Temp_Disp_Digit1 1;
BA_ "U_C489_MY14_Gas_Rx" SG_ 857 LHS_Temp_Disp_Digit1 1;
BA_ "U_U502_MY15_Gas_Rx" SG_ 857 LHS_Temp_Disp_Digit1 1;
BA_ "U_UP375_MY15_Gas_Rx" SG_ 857 LHS_Temp_Disp_Digit1 1;
BA_ "U_UP375_MY15_Diesel_Rx" SG_ 857 LHS_Temp_Disp_Digit1 1;
BA_ "U_CD43_MY16_Gas_Rx" SG_ 857 LHS_Temp_Disp_Digit1 1;
BA_ "CrossOver_InfoCAN" SG_ 857 Front_Blower_Ind 1;
BA_ "GenSigStartValue" SG_ 857 Front_Blower_Ind 15;
BA_ "U_CD4_MY13_Diesel_Rx" SG_ 857 Front_Blower_Ind 1;
BA_ "U_CD4_MY13_Gas_Rx" SG_ 857 Front_Blower_Ind 1;
BA_ "U_CD4_MY13_Hev_Rx" SG_ 857 Front_Blower_Ind 1;
BA_ "U_CD4_MY13_Phev_Rx" SG_ 857 Front_Blower_Ind 1;
BA_ "U_CD42_MY14_Diesel_Rx" SG_ 857 Front_Blower_Ind 1;
BA_ "U_CD42_MY14_Gas_Rx" SG_ 857 Front_Blower_Ind 1;
BA_ "U_P552_MY15_Gas_Rx" SG_ 857 Front_Blower_Ind 1;
BA_ "U_S550_MY15_Gas_Rx" SG_ 857 Front_Blower_Ind 1;
BA_ "U_C489_MY14_Gas_Rx" SG_ 857 Front_Blower_Ind 1;
BA_ "U_U502_MY15_Gas_Rx" SG_ 857 Front_Blower_Ind 1;
BA_ "U_UP375_MY15_Gas_Rx" SG_ 857 Front_Blower_Ind 1;
BA_ "U_UP375_MY15_Diesel_Rx" SG_ 857 Front_Blower_Ind 1;
BA_ "U_CD43_MY16_Gas_Rx" SG_ 857 Front_Blower_Ind 1;
BA_ "CrossOver_InfoCAN" SG_ 857 EATC_LHS_Unit 1;
BA_ "U_CD4_MY13_Diesel_Rx" SG_ 857 EATC_LHS_Unit 1;
BA_ "U_CD4_MY13_Gas_Rx" SG_ 857 EATC_LHS_Unit 1;
BA_ "U_CD4_MY13_Hev_Rx" SG_ 857 EATC_LHS_Unit 1;
BA_ "U_CD4_MY13_Phev_Rx" SG_ 857 EATC_LHS_Unit 1;
BA_ "U_CD42_MY14_Diesel_Rx" SG_ 857 EATC_LHS_Unit 1;
BA_ "U_CD42_MY14_Gas_Rx" SG_ 857 EATC_LHS_Unit 1;
BA_ "U_P552_MY15_Gas_Rx" SG_ 857 EATC_LHS_Unit 1;
BA_ "U_S550_MY15_Gas_Rx" SG_ 857 EATC_LHS_Unit 1;
BA_ "U_C489_MY14_Gas_Rx" SG_ 857 EATC_LHS_Unit 1;
BA_ "U_U502_MY15_Gas_Rx" SG_ 857 EATC_LHS_Unit 1;
BA_ "U_UP375_MY15_Gas_Rx" SG_ 857 EATC_LHS_Unit 1;
BA_ "U_UP375_MY15_Diesel_Rx" SG_ 857 EATC_LHS_Unit 1;
BA_ "U_CD43_MY16_Gas_Rx" SG_ 857 EATC_LHS_Unit 1;
BA_ "CrossOver_InfoCAN" SG_ 856 Rr_Btn_Status_2nd 1;
BA_ "U_CD4_MY13_Diesel_Rx" SG_ 856 Rr_Btn_Status_2nd 1;
BA_ "U_CD4_MY13_Gas_Rx" SG_ 856 Rr_Btn_Status_2nd 1;
BA_ "U_CD4_MY13_Hev_Rx" SG_ 856 Rr_Btn_Status_2nd 1;
BA_ "U_CD4_MY13_Phev_Rx" SG_ 856 Rr_Btn_Status_2nd 1;
BA_ "U_CD42_MY14_Diesel_Rx" SG_ 856 Rr_Btn_Status_2nd 1;
BA_ "U_CD42_MY14_Gas_Rx" SG_ 856 Rr_Btn_Status_2nd 1;
BA_ "U_P552_MY15_Gas_Rx" SG_ 856 Rr_Btn_Status_2nd 1;
BA_ "U_S550_MY15_Gas_Rx" SG_ 856 Rr_Btn_Status_2nd 1;
BA_ "U_C489_MY14_Gas_Rx" SG_ 856 Rr_Btn_Status_2nd 1;
BA_ "U_U502_MY15_Gas_Rx" SG_ 856 Rr_Btn_Status_2nd 1;
BA_ "U_UP375_MY15_Gas_Rx" SG_ 856 Rr_Btn_Status_2nd 1;
BA_ "U_UP375_MY15_Diesel_Rx" SG_ 856 Rr_Btn_Status_2nd 1;
BA_ "U_CD43_MY16_Gas_Rx" SG_ 856 Rr_Btn_Status_2nd 1;
BA_ "CrossOver_InfoCAN" SG_ 856 Rr_Btn_Status_1st 1;
BA_ "U_CD4_MY13_Diesel_Rx" SG_ 856 Rr_Btn_Status_1st 1;
BA_ "U_CD4_MY13_Gas_Rx" SG_ 856 Rr_Btn_Status_1st 1;
BA_ "U_CD4_MY13_Hev_Rx" SG_ 856 Rr_Btn_Status_1st 1;
BA_ "U_CD4_MY13_Phev_Rx" SG_ 856 Rr_Btn_Status_1st 1;
BA_ "U_CD42_MY14_Diesel_Rx" SG_ 856 Rr_Btn_Status_1st 1;
BA_ "U_CD42_MY14_Gas_Rx" SG_ 856 Rr_Btn_Status_1st 1;
BA_ "U_P552_MY15_Gas_Rx" SG_ 856 Rr_Btn_Status_1st 1;
BA_ "U_S550_MY15_Gas_Rx" SG_ 856 Rr_Btn_Status_1st 1;
BA_ "U_C489_MY14_Gas_Rx" SG_ 856 Rr_Btn_Status_1st 1;
BA_ "U_U502_MY15_Gas_Rx" SG_ 856 Rr_Btn_Status_1st 1;
BA_ "U_UP375_MY15_Gas_Rx" SG_ 856 Rr_Btn_Status_1st 1;
BA_ "U_UP375_MY15_Diesel_Rx" SG_ 856 Rr_Btn_Status_1st 1;
BA_ "U_CD43_MY16_Gas_Rx" SG_ 856 Rr_Btn_Status_1st 1;
BA_ "CrossOver_InfoCAN" SG_ 856 Frt_Btn_Status_2nd 1;
BA_ "U_CD4_MY13_Diesel_Rx" SG_ 856 Frt_Btn_Status_2nd 1;
BA_ "U_CD4_MY13_Gas_Rx" SG_ 856 Frt_Btn_Status_2nd 1;
BA_ "U_CD4_MY13_Hev_Rx" SG_ 856 Frt_Btn_Status_2nd 1;
BA_ "U_CD4_MY13_Phev_Rx" SG_ 856 Frt_Btn_Status_2nd 1;
BA_ "U_CD42_MY14_Diesel_Rx" SG_ 856 Frt_Btn_Status_2nd 1;
BA_ "U_CD42_MY14_Gas_Rx" SG_ 856 Frt_Btn_Status_2nd 1;
BA_ "U_P552_MY15_Gas_Rx" SG_ 856 Frt_Btn_Status_2nd 1;
BA_ "U_S550_MY15_Gas_Rx" SG_ 856 Frt_Btn_Status_2nd 1;
BA_ "U_C489_MY14_Gas_Rx" SG_ 856 Frt_Btn_Status_2nd 1;
BA_ "U_U502_MY15_Gas_Rx" SG_ 856 Frt_Btn_Status_2nd 1;
BA_ "U_UP375_MY15_Gas_Rx" SG_ 856 Frt_Btn_Status_2nd 1;
BA_ "U_UP375_MY15_Diesel_Rx" SG_ 856 Frt_Btn_Status_2nd 1;
BA_ "U_CD43_MY16_Gas_Rx" SG_ 856 Frt_Btn_Status_2nd 1;
BA_ "CrossOver_InfoCAN" SG_ 856 Frt_Btn_Status_1st 1;
BA_ "U_CD4_MY13_Diesel_Rx" SG_ 856 Frt_Btn_Status_1st 1;
BA_ "U_CD4_MY13_Gas_Rx" SG_ 856 Frt_Btn_Status_1st 1;
BA_ "U_CD4_MY13_Hev_Rx" SG_ 856 Frt_Btn_Status_1st 1;
BA_ "U_CD4_MY13_Phev_Rx" SG_ 856 Frt_Btn_Status_1st 1;
BA_ "U_CD42_MY14_Diesel_Rx" SG_ 856 Frt_Btn_Status_1st 1;
BA_ "U_CD42_MY14_Gas_Rx" SG_ 856 Frt_Btn_Status_1st 1;
BA_ "U_P552_MY15_Gas_Rx" SG_ 856 Frt_Btn_Status_1st 1;
BA_ "U_S550_MY15_Gas_Rx" SG_ 856 Frt_Btn_Status_1st 1;
BA_ "U_C489_MY14_Gas_Rx" SG_ 856 Frt_Btn_Status_1st 1;
BA_ "U_U502_MY15_Gas_Rx" SG_ 856 Frt_Btn_Status_1st 1;
BA_ "U_UP375_MY15_Gas_Rx" SG_ 856 Frt_Btn_Status_1st 1;
BA_ "U_UP375_MY15_Diesel_Rx" SG_ 856 Frt_Btn_Status_1st 1;
BA_ "U_CD43_MY16_Gas_Rx" SG_ 856 Frt_Btn_Status_1st 1;
BA_ "CrossOver_InfoCAN" SG_ 856 Frt_Blower_Speed 1;
BA_ "U_CD4_MY13_Diesel_Rx" SG_ 856 Frt_Blower_Speed 1;
BA_ "U_CD4_MY13_Gas_Rx" SG_ 856 Frt_Blower_Speed 1;
BA_ "U_CD4_MY13_Hev_Rx" SG_ 856 Frt_Blower_Speed 1;
BA_ "U_CD4_MY13_Phev_Rx" SG_ 856 Frt_Blower_Speed 1;
BA_ "U_CD42_MY14_Diesel_Rx" SG_ 856 Frt_Blower_Speed 1;
BA_ "U_CD42_MY14_Gas_Rx" SG_ 856 Frt_Blower_Speed 1;
BA_ "U_P552_MY15_Gas_Rx" SG_ 856 Frt_Blower_Speed 1;
BA_ "U_S550_MY15_Gas_Rx" SG_ 856 Frt_Blower_Speed 1;
BA_ "U_C489_MY14_Gas_Rx" SG_ 856 Frt_Blower_Speed 1;
BA_ "U_U502_MY15_Gas_Rx" SG_ 856 Frt_Blower_Speed 1;
BA_ "U_UP375_MY15_Gas_Rx" SG_ 856 Frt_Blower_Speed 1;
BA_ "U_UP375_MY15_Diesel_Rx" SG_ 856 Frt_Blower_Speed 1;
BA_ "U_CD43_MY16_Gas_Rx" SG_ 856 Frt_Blower_Speed 1;
BA_ "CrossOver_InfoCAN" SG_ 856 Drv_Set_Temp 1;
BA_ "U_CD4_MY13_Diesel_Rx" SG_ 856 Drv_Set_Temp 1;
BA_ "U_CD4_MY13_Gas_Rx" SG_ 856 Drv_Set_Temp 1;
BA_ "U_CD4_MY13_Hev_Rx" SG_ 856 Drv_Set_Temp 1;
BA_ "U_CD4_MY13_Phev_Rx" SG_ 856 Drv_Set_Temp 1;
BA_ "U_CD42_MY14_Diesel_Rx" SG_ 856 Drv_Set_Temp 1;
BA_ "U_CD42_MY14_Gas_Rx" SG_ 856 Drv_Set_Temp 1;
BA_ "U_P552_MY15_Gas_Rx" SG_ 856 Drv_Set_Temp 1;
BA_ "U_S550_MY15_Gas_Rx" SG_ 856 Drv_Set_Temp 1;
BA_ "U_C489_MY14_Gas_Rx" SG_ 856 Drv_Set_Temp 1;
BA_ "U_U502_MY15_Gas_Rx" SG_ 856 Drv_Set_Temp 1;
BA_ "U_UP375_MY15_Gas_Rx" SG_ 856 Drv_Set_Temp 1;
BA_ "U_UP375_MY15_Diesel_Rx" SG_ 856 Drv_Set_Temp 1;
BA_ "U_CD43_MY16_Gas_Rx" SG_ 856 Drv_Set_Temp 1;
BA_ "CrossOver_InfoCAN" SG_ 854 CC_Fr_Stat_User_Adj 1;
BA_ "GenSigSendType" SG_ 854 CC_Fr_Stat_User_Adj 3;
BA_ "U_CD4_MY13_Diesel_Tx" SG_ 854 CC_Fr_Stat_User_Adj 1;
BA_ "U_CD4_MY13_Gas_Tx" SG_ 854 CC_Fr_Stat_User_Adj 1;
BA_ "U_CD4_MY13_Hev_Tx" SG_ 854 CC_Fr_Stat_User_Adj 1;
BA_ "U_CD4_MY13_Phev_Tx" SG_ 854 CC_Fr_Stat_User_Adj 1;
BA_ "U_CD42_MY14_Diesel_Tx" SG_ 854 CC_Fr_Stat_User_Adj 1;
BA_ "U_CD42_MY14_Gas_Tx" SG_ 854 CC_Fr_Stat_User_Adj 1;
BA_ "U_P552_MY15_Gas_Tx" SG_ 854 CC_Fr_Stat_User_Adj 1;
BA_ "U_S550_MY15_Gas_Tx" SG_ 854 CC_Fr_Stat_User_Adj 1;
BA_ "U_C489_MY14_Gas_Tx" SG_ 854 CC_Fr_Stat_User_Adj 1;
BA_ "U_U502_MY15_Gas_Tx" SG_ 854 CC_Fr_Stat_User_Adj 1;
BA_ "U_UP375_MY15_Gas_Tx" SG_ 854 CC_Fr_Stat_User_Adj 1;
BA_ "U_UP375_MY15_Diesel_Tx" SG_ 854 CC_Fr_Stat_User_Adj 1;
BA_ "U_CD43_MY16_Gas_Tx" SG_ 854 CC_Fr_Stat_User_Adj 1;
BA_ "CrossOver_InfoCAN" SG_ 854 Front_Blower_Indicate 1;
BA_ "GenSigStartValue" SG_ 854 Front_Blower_Indicate 15;
BA_ "GenSigSendType" SG_ 854 Front_Blower_Indicate 3;
BA_ "U_CD4_MY13_Diesel_Tx" SG_ 854 Front_Blower_Indicate 1;
BA_ "U_CD4_MY13_Gas_Tx" SG_ 854 Front_Blower_Indicate 1;
BA_ "U_CD4_MY13_Hev_Tx" SG_ 854 Front_Blower_Indicate 1;
BA_ "U_CD4_MY13_Phev_Tx" SG_ 854 Front_Blower_Indicate 1;
BA_ "U_CD42_MY14_Diesel_Tx" SG_ 854 Front_Blower_Indicate 1;
BA_ "U_CD42_MY14_Gas_Tx" SG_ 854 Front_Blower_Indicate 1;
BA_ "U_P552_MY15_Gas_Tx" SG_ 854 Front_Blower_Indicate 1;
BA_ "U_S550_MY15_Gas_Tx" SG_ 854 Front_Blower_Indicate 1;
BA_ "U_C489_MY14_Gas_Tx" SG_ 854 Front_Blower_Indicate 1;
BA_ "U_U502_MY15_Gas_Tx" SG_ 854 Front_Blower_Indicate 1;
BA_ "U_UP375_MY15_Gas_Tx" SG_ 854 Front_Blower_Indicate 1;
BA_ "U_UP375_MY15_Diesel_Tx" SG_ 854 Front_Blower_Indicate 1;
BA_ "U_CD43_MY16_Gas_Tx" SG_ 854 Front_Blower_Indicate 1;
BA_ "CrossOver_InfoCAN" SG_ 854 CC_Diagnostics_Active 1;
BA_ "GenSigSendType" SG_ 854 CC_Diagnostics_Active 3;
BA_ "U_CD4_MY13_Diesel_Tx" SG_ 854 CC_Diagnostics_Active 1;
BA_ "U_CD4_MY13_Gas_Tx" SG_ 854 CC_Diagnostics_Active 1;
BA_ "U_CD4_MY13_Hev_Tx" SG_ 854 CC_Diagnostics_Active 1;
BA_ "U_CD4_MY13_Phev_Tx" SG_ 854 CC_Diagnostics_Active 1;
BA_ "U_CD42_MY14_Diesel_Tx" SG_ 854 CC_Diagnostics_Active 1;
BA_ "U_CD42_MY14_Gas_Tx" SG_ 854 CC_Diagnostics_Active 1;
BA_ "U_P552_MY15_Gas_Tx" SG_ 854 CC_Diagnostics_Active 1;
BA_ "U_S550_MY15_Gas_Tx" SG_ 854 CC_Diagnostics_Active 1;
BA_ "U_C489_MY14_Gas_Tx" SG_ 854 CC_Diagnostics_Active 1;
BA_ "U_U502_MY15_Gas_Tx" SG_ 854 CC_Diagnostics_Active 1;
BA_ "U_UP375_MY15_Gas_Tx" SG_ 854 CC_Diagnostics_Active 1;
BA_ "U_UP375_MY15_Diesel_Tx" SG_ 854 CC_Diagnostics_Active 1;
BA_ "U_CD43_MY16_Gas_Tx" SG_ 854 CC_Diagnostics_Active 1;
BA_ "CrossOver_InfoCAN" SG_ 854 RHS_Temp_Display_Digit3 1;
BA_ "GenSigSendType" SG_ 854 RHS_Temp_Display_Digit3 3;
BA_ "U_CD4_MY13_Diesel_Tx" SG_ 854 RHS_Temp_Display_Digit3 1;
BA_ "U_CD4_MY13_Gas_Tx" SG_ 854 RHS_Temp_Display_Digit3 1;
BA_ "U_CD4_MY13_Hev_Tx" SG_ 854 RHS_Temp_Display_Digit3 1;
BA_ "U_CD4_MY13_Phev_Tx" SG_ 854 RHS_Temp_Display_Digit3 1;
BA_ "U_CD42_MY14_Diesel_Tx" SG_ 854 RHS_Temp_Display_Digit3 1;
BA_ "U_CD42_MY14_Gas_Tx" SG_ 854 RHS_Temp_Display_Digit3 1;
BA_ "U_P552_MY15_Gas_Tx" SG_ 854 RHS_Temp_Display_Digit3 1;
BA_ "U_S550_MY15_Gas_Tx" SG_ 854 RHS_Temp_Display_Digit3 1;
BA_ "U_C489_MY14_Gas_Tx" SG_ 854 RHS_Temp_Display_Digit3 1;
BA_ "U_U502_MY15_Gas_Tx" SG_ 854 RHS_Temp_Display_Digit3 1;
BA_ "U_UP375_MY15_Gas_Tx" SG_ 854 RHS_Temp_Display_Digit3 1;
BA_ "U_UP375_MY15_Diesel_Tx" SG_ 854 RHS_Temp_Display_Digit3 1;
BA_ "U_CD43_MY16_Gas_Tx" SG_ 854 RHS_Temp_Display_Digit3 1;
BA_ "CrossOver_InfoCAN" SG_ 854 RHS_Temp_Display_Digit2 1;
BA_ "GenSigSendType" SG_ 854 RHS_Temp_Display_Digit2 3;
BA_ "U_CD4_MY13_Diesel_Tx" SG_ 854 RHS_Temp_Display_Digit2 1;
BA_ "U_CD4_MY13_Gas_Tx" SG_ 854 RHS_Temp_Display_Digit2 1;
BA_ "U_CD4_MY13_Hev_Tx" SG_ 854 RHS_Temp_Display_Digit2 1;
BA_ "U_CD4_MY13_Phev_Tx" SG_ 854 RHS_Temp_Display_Digit2 1;
BA_ "U_CD42_MY14_Diesel_Tx" SG_ 854 RHS_Temp_Display_Digit2 1;
BA_ "U_CD42_MY14_Gas_Tx" SG_ 854 RHS_Temp_Display_Digit2 1;
BA_ "U_P552_MY15_Gas_Tx" SG_ 854 RHS_Temp_Display_Digit2 1;
BA_ "U_S550_MY15_Gas_Tx" SG_ 854 RHS_Temp_Display_Digit2 1;
BA_ "U_C489_MY14_Gas_Tx" SG_ 854 RHS_Temp_Display_Digit2 1;
BA_ "U_U502_MY15_Gas_Tx" SG_ 854 RHS_Temp_Display_Digit2 1;
BA_ "U_UP375_MY15_Gas_Tx" SG_ 854 RHS_Temp_Display_Digit2 1;
BA_ "U_UP375_MY15_Diesel_Tx" SG_ 854 RHS_Temp_Display_Digit2 1;
BA_ "U_CD43_MY16_Gas_Tx" SG_ 854 RHS_Temp_Display_Digit2 1;
BA_ "CrossOver_InfoCAN" SG_ 854 RHS_Temp_Display_Digit1 1;
BA_ "GenSigSendType" SG_ 854 RHS_Temp_Display_Digit1 3;
BA_ "U_CD4_MY13_Diesel_Tx" SG_ 854 RHS_Temp_Display_Digit1 1;
BA_ "U_CD4_MY13_Gas_Tx" SG_ 854 RHS_Temp_Display_Digit1 1;
BA_ "U_CD4_MY13_Hev_Tx" SG_ 854 RHS_Temp_Display_Digit1 1;
BA_ "U_CD4_MY13_Phev_Tx" SG_ 854 RHS_Temp_Display_Digit1 1;
BA_ "U_CD42_MY14_Diesel_Tx" SG_ 854 RHS_Temp_Display_Digit1 1;
BA_ "U_CD42_MY14_Gas_Tx" SG_ 854 RHS_Temp_Display_Digit1 1;
BA_ "U_P552_MY15_Gas_Tx" SG_ 854 RHS_Temp_Display_Digit1 1;
BA_ "U_S550_MY15_Gas_Tx" SG_ 854 RHS_Temp_Display_Digit1 1;
BA_ "U_C489_MY14_Gas_Tx" SG_ 854 RHS_Temp_Display_Digit1 1;
BA_ "U_U502_MY15_Gas_Tx" SG_ 854 RHS_Temp_Display_Digit1 1;
BA_ "U_UP375_MY15_Gas_Tx" SG_ 854 RHS_Temp_Display_Digit1 1;
BA_ "U_UP375_MY15_Diesel_Tx" SG_ 854 RHS_Temp_Display_Digit1 1;
BA_ "U_CD43_MY16_Gas_Tx" SG_ 854 RHS_Temp_Display_Digit1 1;
BA_ "CrossOver_InfoCAN" SG_ 854 LHS_Temp_Display_Digit3 1;
BA_ "GenSigSendType" SG_ 854 LHS_Temp_Display_Digit3 3;
BA_ "U_CD4_MY13_Diesel_Tx" SG_ 854 LHS_Temp_Display_Digit3 1;
BA_ "U_CD4_MY13_Gas_Tx" SG_ 854 LHS_Temp_Display_Digit3 1;
BA_ "U_CD4_MY13_Hev_Tx" SG_ 854 LHS_Temp_Display_Digit3 1;
BA_ "U_CD4_MY13_Phev_Tx" SG_ 854 LHS_Temp_Display_Digit3 1;
BA_ "U_CD42_MY14_Diesel_Tx" SG_ 854 LHS_Temp_Display_Digit3 1;
BA_ "U_CD42_MY14_Gas_Tx" SG_ 854 LHS_Temp_Display_Digit3 1;
BA_ "U_P552_MY15_Gas_Tx" SG_ 854 LHS_Temp_Display_Digit3 1;
BA_ "U_S550_MY15_Gas_Tx" SG_ 854 LHS_Temp_Display_Digit3 1;
BA_ "U_C489_MY14_Gas_Tx" SG_ 854 LHS_Temp_Display_Digit3 1;
BA_ "U_U502_MY15_Gas_Tx" SG_ 854 LHS_Temp_Display_Digit3 1;
BA_ "U_UP375_MY15_Gas_Tx" SG_ 854 LHS_Temp_Display_Digit3 1;
BA_ "U_UP375_MY15_Diesel_Tx" SG_ 854 LHS_Temp_Display_Digit3 1;
BA_ "U_CD43_MY16_Gas_Tx" SG_ 854 LHS_Temp_Display_Digit3 1;
BA_ "CrossOver_InfoCAN" SG_ 854 LHS_Temp_Display_Digit2 1;
BA_ "GenSigSendType" SG_ 854 LHS_Temp_Display_Digit2 3;
BA_ "U_CD4_MY13_Diesel_Tx" SG_ 854 LHS_Temp_Display_Digit2 1;
BA_ "U_CD4_MY13_Gas_Tx" SG_ 854 LHS_Temp_Display_Digit2 1;
BA_ "U_CD4_MY13_Hev_Tx" SG_ 854 LHS_Temp_Display_Digit2 1;
BA_ "U_CD4_MY13_Phev_Tx" SG_ 854 LHS_Temp_Display_Digit2 1;
BA_ "U_CD42_MY14_Diesel_Tx" SG_ 854 LHS_Temp_Display_Digit2 1;
BA_ "U_CD42_MY14_Gas_Tx" SG_ 854 LHS_Temp_Display_Digit2 1;
BA_ "U_P552_MY15_Gas_Tx" SG_ 854 LHS_Temp_Display_Digit2 1;
BA_ "U_S550_MY15_Gas_Tx" SG_ 854 LHS_Temp_Display_Digit2 1;
BA_ "U_C489_MY14_Gas_Tx" SG_ 854 LHS_Temp_Display_Digit2 1;
BA_ "U_U502_MY15_Gas_Tx" SG_ 854 LHS_Temp_Display_Digit2 1;
BA_ "U_UP375_MY15_Gas_Tx" SG_ 854 LHS_Temp_Display_Digit2 1;
BA_ "U_UP375_MY15_Diesel_Tx" SG_ 854 LHS_Temp_Display_Digit2 1;
BA_ "U_CD43_MY16_Gas_Tx" SG_ 854 LHS_Temp_Display_Digit2 1;
BA_ "CrossOver_InfoCAN" SG_ 854 LHS_Temp_Display_Digit1 1;
BA_ "GenSigSendType" SG_ 854 LHS_Temp_Display_Digit1 3;
BA_ "U_CD4_MY13_Diesel_Tx" SG_ 854 LHS_Temp_Display_Digit1 1;
BA_ "U_CD4_MY13_Gas_Tx" SG_ 854 LHS_Temp_Display_Digit1 1;
BA_ "U_CD4_MY13_Hev_Tx" SG_ 854 LHS_Temp_Display_Digit1 1;
BA_ "U_CD4_MY13_Phev_Tx" SG_ 854 LHS_Temp_Display_Digit1 1;
BA_ "U_CD42_MY14_Diesel_Tx" SG_ 854 LHS_Temp_Display_Digit1 1;
BA_ "U_CD42_MY14_Gas_Tx" SG_ 854 LHS_Temp_Display_Digit1 1;
BA_ "U_P552_MY15_Gas_Tx" SG_ 854 LHS_Temp_Display_Digit1 1;
BA_ "U_S550_MY15_Gas_Tx" SG_ 854 LHS_Temp_Display_Digit1 1;
BA_ "U_C489_MY14_Gas_Tx" SG_ 854 LHS_Temp_Display_Digit1 1;
BA_ "U_U502_MY15_Gas_Tx" SG_ 854 LHS_Temp_Display_Digit1 1;
BA_ "U_UP375_MY15_Gas_Tx" SG_ 854 LHS_Temp_Display_Digit1 1;
BA_ "U_UP375_MY15_Diesel_Tx" SG_ 854 LHS_Temp_Display_Digit1 1;
BA_ "U_CD43_MY16_Gas_Tx" SG_ 854 LHS_Temp_Display_Digit1 1;
BA_ "CrossOver_InfoCAN" SG_ 854 EATC_RHS_Units 1;
BA_ "GenSigSendType" SG_ 854 EATC_RHS_Units 3;
BA_ "U_CD4_MY13_Diesel_Tx" SG_ 854 EATC_RHS_Units 1;
BA_ "U_CD4_MY13_Gas_Tx" SG_ 854 EATC_RHS_Units 1;
BA_ "U_CD4_MY13_Hev_Tx" SG_ 854 EATC_RHS_Units 1;
BA_ "U_CD4_MY13_Phev_Tx" SG_ 854 EATC_RHS_Units 1;
BA_ "U_CD42_MY14_Diesel_Tx" SG_ 854 EATC_RHS_Units 1;
BA_ "U_CD42_MY14_Gas_Tx" SG_ 854 EATC_RHS_Units 1;
BA_ "U_P552_MY15_Gas_Tx" SG_ 854 EATC_RHS_Units 1;
BA_ "U_S550_MY15_Gas_Tx" SG_ 854 EATC_RHS_Units 1;
BA_ "U_C489_MY14_Gas_Tx" SG_ 854 EATC_RHS_Units 1;
BA_ "U_U502_MY15_Gas_Tx" SG_ 854 EATC_RHS_Units 1;
BA_ "U_UP375_MY15_Gas_Tx" SG_ 854 EATC_RHS_Units 1;
BA_ "U_UP375_MY15_Diesel_Tx" SG_ 854 EATC_RHS_Units 1;
BA_ "U_CD43_MY16_Gas_Tx" SG_ 854 EATC_RHS_Units 1;
BA_ "CrossOver_InfoCAN" SG_ 854 EATC_LHS_Units 1;
BA_ "GenSigSendType" SG_ 854 EATC_LHS_Units 3;
BA_ "U_CD4_MY13_Diesel_Tx" SG_ 854 EATC_LHS_Units 1;
BA_ "U_CD4_MY13_Gas_Tx" SG_ 854 EATC_LHS_Units 1;
BA_ "U_CD4_MY13_Hev_Tx" SG_ 854 EATC_LHS_Units 1;
BA_ "U_CD4_MY13_Phev_Tx" SG_ 854 EATC_LHS_Units 1;
BA_ "U_CD42_MY14_Diesel_Tx" SG_ 854 EATC_LHS_Units 1;
BA_ "U_CD42_MY14_Gas_Tx" SG_ 854 EATC_LHS_Units 1;
BA_ "U_P552_MY15_Gas_Tx" SG_ 854 EATC_LHS_Units 1;
BA_ "U_S550_MY15_Gas_Tx" SG_ 854 EATC_LHS_Units 1;
BA_ "U_C489_MY14_Gas_Tx" SG_ 854 EATC_LHS_Units 1;
BA_ "U_U502_MY15_Gas_Tx" SG_ 854 EATC_LHS_Units 1;
BA_ "U_UP375_MY15_Gas_Tx" SG_ 854 EATC_LHS_Units 1;
BA_ "U_UP375_MY15_Diesel_Tx" SG_ 854 EATC_LHS_Units 1;
BA_ "U_CD43_MY16_Gas_Tx" SG_ 854 EATC_LHS_Units 1;
BA_ "GenSigSendType" SG_ 1959 TesterPhysicalReqFCIM 3;
BA_ "U_CD4_MY13_Diesel_Rx" SG_ 1959 TesterPhysicalReqFCIM 1;
BA_ "U_CD4_MY13_Gas_Rx" SG_ 1959 TesterPhysicalReqFCIM 1;
BA_ "U_CD4_MY13_Hev_Rx" SG_ 1959 TesterPhysicalReqFCIM 1;
BA_ "U_CD4_MY13_Phev_Rx" SG_ 1959 TesterPhysicalReqFCIM 1;
BA_ "U_CD42_MY14_Diesel_Rx" SG_ 1959 TesterPhysicalReqFCIM 1;
BA_ "U_CD42_MY14_Gas_Rx" SG_ 1959 TesterPhysicalReqFCIM 1;
BA_ "U_P552_MY15_Gas_Rx" SG_ 1959 TesterPhysicalReqFCIM 1;
BA_ "U_S550_MY15_Gas_Rx" SG_ 1959 TesterPhysicalReqFCIM 1;
BA_ "U_C489_MY14_Gas_Rx" SG_ 1959 TesterPhysicalReqFCIM 1;
BA_ "U_U502_MY15_Gas_Rx" SG_ 1959 TesterPhysicalReqFCIM 1;
BA_ "U_UP375_MY15_Gas_Rx" SG_ 1959 TesterPhysicalReqFCIM 1;
BA_ "U_UP375_MY15_Diesel_Rx" SG_ 1959 TesterPhysicalReqFCIM 1;
BA_ "U_CD43_MY16_Gas_Rx" SG_ 1959 TesterPhysicalReqFCIM 1;
BA_ "GenSigSendType" SG_ 1967 TesterPhysicalResFCIM 3;
BA_ "U_CD4_MY13_Diesel_Tx" SG_ 1967 TesterPhysicalResFCIM 1;
BA_ "U_CD4_MY13_Gas_Tx" SG_ 1967 TesterPhysicalResFCIM 1;
BA_ "U_CD4_MY13_Hev_Tx" SG_ 1967 TesterPhysicalResFCIM 1;
BA_ "U_CD4_MY13_Phev_Tx" SG_ 1967 TesterPhysicalResFCIM 1;
BA_ "U_CD42_MY14_Diesel_Tx" SG_ 1967 TesterPhysicalResFCIM 1;
BA_ "U_CD42_MY14_Gas_Tx" SG_ 1967 TesterPhysicalResFCIM 1;
BA_ "U_P552_MY15_Gas_Tx" SG_ 1967 TesterPhysicalResFCIM 1;
BA_ "U_S550_MY15_Gas_Tx" SG_ 1967 TesterPhysicalResFCIM 1;
BA_ "U_C489_MY14_Gas_Tx" SG_ 1967 TesterPhysicalResFCIM 1;
BA_ "U_U502_MY15_Gas_Tx" SG_ 1967 TesterPhysicalResFCIM 1;
BA_ "U_UP375_MY15_Gas_Tx" SG_ 1967 TesterPhysicalResFCIM 1;
BA_ "U_UP375_MY15_Diesel_Tx" SG_ 1967 TesterPhysicalResFCIM 1;
BA_ "U_CD43_MY16_Gas_Tx" SG_ 1967 TesterPhysicalResFCIM 1;
BA_ "CrossOver_InfoCAN" SG_ 534 WhlRotatRr_No_Cnt 1;
BA_ "U_CD4_MY13_Diesel_Rx" SG_ 534 WhlRotatRr_No_Cnt 1;
BA_ "U_CD4_MY13_Gas_Rx" SG_ 534 WhlRotatRr_No_Cnt 1;
BA_ "U_CD4_MY13_Hev_Rx" SG_ 534 WhlRotatRr_No_Cnt 1;
BA_ "U_CD4_MY13_Phev_Rx" SG_ 534 WhlRotatRr_No_Cnt 1;
BA_ "U_CD42_MY14_Diesel_Rx" SG_ 534 WhlRotatRr_No_Cnt 1;
BA_ "U_CD42_MY14_Gas_Rx" SG_ 534 WhlRotatRr_No_Cnt 1;
BA_ "U_P552_MY15_Gas_Rx" SG_ 534 WhlRotatRr_No_Cnt 1;
BA_ "U_S550_MY15_Gas_Rx" SG_ 534 WhlRotatRr_No_Cnt 1;
BA_ "U_C489_MY14_Gas_Rx" SG_ 534 WhlRotatRr_No_Cnt 1;
BA_ "U_U502_MY15_Gas_Rx" SG_ 534 WhlRotatRr_No_Cnt 1;
BA_ "U_UP375_MY15_Gas_Rx" SG_ 534 WhlRotatRr_No_Cnt 1;
BA_ "U_UP375_MY15_Diesel_Rx" SG_ 534 WhlRotatRr_No_Cnt 1;
BA_ "U_CD43_MY16_Gas_Rx" SG_ 534 WhlRotatRr_No_Cnt 1;
BA_ "CrossOver_InfoCAN" SG_ 534 WhlDirRr_D_Actl 1;
BA_ "U_CD4_MY13_Diesel_Rx" SG_ 534 WhlDirRr_D_Actl 1;
BA_ "U_CD4_MY13_Gas_Rx" SG_ 534 WhlDirRr_D_Actl 1;
BA_ "U_CD4_MY13_Hev_Rx" SG_ 534 WhlDirRr_D_Actl 1;
BA_ "U_CD4_MY13_Phev_Rx" SG_ 534 WhlDirRr_D_Actl 1;
BA_ "U_CD42_MY14_Diesel_Rx" SG_ 534 WhlDirRr_D_Actl 1;
BA_ "U_CD42_MY14_Gas_Rx" SG_ 534 WhlDirRr_D_Actl 1;
BA_ "U_P552_MY15_Gas_Rx" SG_ 534 WhlDirRr_D_Actl 1;
BA_ "U_S550_MY15_Gas_Rx" SG_ 534 WhlDirRr_D_Actl 1;
BA_ "U_C489_MY14_Gas_Rx" SG_ 534 WhlDirRr_D_Actl 1;
BA_ "U_U502_MY15_Gas_Rx" SG_ 534 WhlDirRr_D_Actl 1;
BA_ "U_UP375_MY15_Gas_Rx" SG_ 534 WhlDirRr_D_Actl 1;
BA_ "U_UP375_MY15_Diesel_Rx" SG_ 534 WhlDirRr_D_Actl 1;
BA_ "U_CD43_MY16_Gas_Rx" SG_ 534 WhlDirRr_D_Actl 1;
BA_ "CrossOver_InfoCAN" SG_ 534 WhlDirRl_D_Actl 1;
BA_ "U_CD4_MY13_Diesel_Rx" SG_ 534 WhlDirRl_D_Actl 1;
BA_ "U_CD4_MY13_Gas_Rx" SG_ 534 WhlDirRl_D_Actl 1;
BA_ "U_CD4_MY13_Hev_Rx" SG_ 534 WhlDirRl_D_Actl 1;
BA_ "U_CD4_MY13_Phev_Rx" SG_ 534 WhlDirRl_D_Actl 1;
BA_ "U_CD42_MY14_Diesel_Rx" SG_ 534 WhlDirRl_D_Actl 1;
BA_ "U_CD42_MY14_Gas_Rx" SG_ 534 WhlDirRl_D_Actl 1;
BA_ "U_P552_MY15_Gas_Rx" SG_ 534 WhlDirRl_D_Actl 1;
BA_ "U_S550_MY15_Gas_Rx" SG_ 534 WhlDirRl_D_Actl 1;
BA_ "U_C489_MY14_Gas_Rx" SG_ 534 WhlDirRl_D_Actl 1;
BA_ "U_U502_MY15_Gas_Rx" SG_ 534 WhlDirRl_D_Actl 1;
BA_ "U_UP375_MY15_Gas_Rx" SG_ 534 WhlDirRl_D_Actl 1;
BA_ "U_UP375_MY15_Diesel_Rx" SG_ 534 WhlDirRl_D_Actl 1;
BA_ "U_CD43_MY16_Gas_Rx" SG_ 534 WhlDirRl_D_Actl 1;
BA_ "CrossOver_InfoCAN" SG_ 534 WhlDirFr_D_Actl 1;
BA_ "U_CD4_MY13_Diesel_Rx" SG_ 534 WhlDirFr_D_Actl 1;
BA_ "U_CD4_MY13_Gas_Rx" SG_ 534 WhlDirFr_D_Actl 1;
BA_ "U_CD4_MY13_Hev_Rx" SG_ 534 WhlDirFr_D_Actl 1;
BA_ "U_CD4_MY13_Phev_Rx" SG_ 534 WhlDirFr_D_Actl 1;
BA_ "U_CD42_MY14_Diesel_Rx" SG_ 534 WhlDirFr_D_Actl 1;
BA_ "U_CD42_MY14_Gas_Rx" SG_ 534 WhlDirFr_D_Actl 1;
BA_ "U_P552_MY15_Gas_Rx" SG_ 534 WhlDirFr_D_Actl 1;
BA_ "U_S550_MY15_Gas_Rx" SG_ 534 WhlDirFr_D_Actl 1;
BA_ "U_C489_MY14_Gas_Rx" SG_ 534 WhlDirFr_D_Actl 1;
BA_ "U_U502_MY15_Gas_Rx" SG_ 534 WhlDirFr_D_Actl 1;
BA_ "U_UP375_MY15_Gas_Rx" SG_ 534 WhlDirFr_D_Actl 1;
BA_ "U_UP375_MY15_Diesel_Rx" SG_ 534 WhlDirFr_D_Actl 1;
BA_ "U_CD43_MY16_Gas_Rx" SG_ 534 WhlDirFr_D_Actl 1;
BA_ "CrossOver_InfoCAN" SG_ 534 WhlDirFl_D_Actl 1;
BA_ "U_CD4_MY13_Diesel_Rx" SG_ 534 WhlDirFl_D_Actl 1;
BA_ "U_CD4_MY13_Gas_Rx" SG_ 534 WhlDirFl_D_Actl 1;
BA_ "U_CD4_MY13_Hev_Rx" SG_ 534 WhlDirFl_D_Actl 1;
BA_ "U_CD4_MY13_Phev_Rx" SG_ 534 WhlDirFl_D_Actl 1;
BA_ "U_CD42_MY14_Diesel_Rx" SG_ 534 WhlDirFl_D_Actl 1;
BA_ "U_CD42_MY14_Gas_Rx" SG_ 534 WhlDirFl_D_Actl 1;
BA_ "U_P552_MY15_Gas_Rx" SG_ 534 WhlDirFl_D_Actl 1;
BA_ "U_S550_MY15_Gas_Rx" SG_ 534 WhlDirFl_D_Actl 1;
BA_ "U_C489_MY14_Gas_Rx" SG_ 534 WhlDirFl_D_Actl 1;
BA_ "U_U502_MY15_Gas_Rx" SG_ 534 WhlDirFl_D_Actl 1;
BA_ "U_UP375_MY15_Gas_Rx" SG_ 534 WhlDirFl_D_Actl 1;
BA_ "U_UP375_MY15_Diesel_Rx" SG_ 534 WhlDirFl_D_Actl 1;
BA_ "U_CD43_MY16_Gas_Rx" SG_ 534 WhlDirFl_D_Actl 1;
BA_ "CrossOver_InfoCAN" SG_ 534 WhlRotatRl_No_Cnt 1;
BA_ "U_CD4_MY13_Diesel_Rx" SG_ 534 WhlRotatRl_No_Cnt 1;
BA_ "U_CD4_MY13_Gas_Rx" SG_ 534 WhlRotatRl_No_Cnt 1;
BA_ "U_CD4_MY13_Hev_Rx" SG_ 534 WhlRotatRl_No_Cnt 1;
BA_ "U_CD4_MY13_Phev_Rx" SG_ 534 WhlRotatRl_No_Cnt 1;
BA_ "U_CD42_MY14_Diesel_Rx" SG_ 534 WhlRotatRl_No_Cnt 1;
BA_ "U_CD42_MY14_Gas_Rx" SG_ 534 WhlRotatRl_No_Cnt 1;
BA_ "U_P552_MY15_Gas_Rx" SG_ 534 WhlRotatRl_No_Cnt 1;
BA_ "U_S550_MY15_Gas_Rx" SG_ 534 WhlRotatRl_No_Cnt 1;
BA_ "U_C489_MY14_Gas_Rx" SG_ 534 WhlRotatRl_No_Cnt 1;
BA_ "U_U502_MY15_Gas_Rx" SG_ 534 WhlRotatRl_No_Cnt 1;
BA_ "U_UP375_MY15_Gas_Rx" SG_ 534 WhlRotatRl_No_Cnt 1;
BA_ "U_UP375_MY15_Diesel_Rx" SG_ 534 WhlRotatRl_No_Cnt 1;
BA_ "U_CD43_MY16_Gas_Rx" SG_ 534 WhlRotatRl_No_Cnt 1;
BA_ "CrossOver_InfoCAN" SG_ 534 WhlRotatFr_No_Cnt 1;
BA_ "U_CD4_MY13_Diesel_Rx" SG_ 534 WhlRotatFr_No_Cnt 1;
BA_ "U_CD4_MY13_Gas_Rx" SG_ 534 WhlRotatFr_No_Cnt 1;
BA_ "U_CD4_MY13_Hev_Rx" SG_ 534 WhlRotatFr_No_Cnt 1;
BA_ "U_CD4_MY13_Phev_Rx" SG_ 534 WhlRotatFr_No_Cnt 1;
BA_ "U_CD42_MY14_Diesel_Rx" SG_ 534 WhlRotatFr_No_Cnt 1;
BA_ "U_CD42_MY14_Gas_Rx" SG_ 534 WhlRotatFr_No_Cnt 1;
BA_ "U_P552_MY15_Gas_Rx" SG_ 534 WhlRotatFr_No_Cnt 1;
BA_ "U_S550_MY15_Gas_Rx" SG_ 534 WhlRotatFr_No_Cnt 1;
BA_ "U_C489_MY14_Gas_Rx" SG_ 534 WhlRotatFr_No_Cnt 1;
BA_ "U_U502_MY15_Gas_Rx" SG_ 534 WhlRotatFr_No_Cnt 1;
BA_ "U_UP375_MY15_Gas_Rx" SG_ 534 WhlRotatFr_No_Cnt 1;
BA_ "U_UP375_MY15_Diesel_Rx" SG_ 534 WhlRotatFr_No_Cnt 1;
BA_ "U_CD43_MY16_Gas_Rx" SG_ 534 WhlRotatFr_No_Cnt 1;
BA_ "CrossOver_InfoCAN" SG_ 534 WhlRotatFl_No_Cnt 1;
BA_ "U_CD4_MY13_Diesel_Rx" SG_ 534 WhlRotatFl_No_Cnt 1;
BA_ "U_CD4_MY13_Gas_Rx" SG_ 534 WhlRotatFl_No_Cnt 1;
BA_ "U_CD4_MY13_Hev_Rx" SG_ 534 WhlRotatFl_No_Cnt 1;
BA_ "U_CD4_MY13_Phev_Rx" SG_ 534 WhlRotatFl_No_Cnt 1;
BA_ "U_CD42_MY14_Diesel_Rx" SG_ 534 WhlRotatFl_No_Cnt 1;
BA_ "U_CD42_MY14_Gas_Rx" SG_ 534 WhlRotatFl_No_Cnt 1;
BA_ "U_P552_MY15_Gas_Rx" SG_ 534 WhlRotatFl_No_Cnt 1;
BA_ "U_S550_MY15_Gas_Rx" SG_ 534 WhlRotatFl_No_Cnt 1;
BA_ "U_C489_MY14_Gas_Rx" SG_ 534 WhlRotatFl_No_Cnt 1;
BA_ "U_U502_MY15_Gas_Rx" SG_ 534 WhlRotatFl_No_Cnt 1;
BA_ "U_UP375_MY15_Gas_Rx" SG_ 534 WhlRotatFl_No_Cnt 1;
BA_ "U_UP375_MY15_Diesel_Rx" SG_ 534 WhlRotatFl_No_Cnt 1;
BA_ "U_CD43_MY16_Gas_Rx" SG_ 534 WhlRotatFl_No_Cnt 1;
BA_ "GenSigSendType" SG_ 2008 TesterPhysicalResAPIM 3;
BA_ "U_CD4_MY13_Diesel_Tx" SG_ 2008 TesterPhysicalResAPIM 1;
BA_ "U_CD4_MY13_Gas_Tx" SG_ 2008 TesterPhysicalResAPIM 1;
BA_ "U_CD4_MY13_Hev_Tx" SG_ 2008 TesterPhysicalResAPIM 1;
BA_ "U_CD4_MY13_Phev_Tx" SG_ 2008 TesterPhysicalResAPIM 1;
BA_ "U_CD42_MY14_Diesel_Tx" SG_ 2008 TesterPhysicalResAPIM 1;
BA_ "U_CD42_MY14_Gas_Tx" SG_ 2008 TesterPhysicalResAPIM 1;
BA_ "U_P552_MY15_Gas_Tx" SG_ 2008 TesterPhysicalResAPIM 1;
BA_ "U_S550_MY15_Gas_Tx" SG_ 2008 TesterPhysicalResAPIM 1;
BA_ "U_C489_MY14_Gas_Tx" SG_ 2008 TesterPhysicalResAPIM 1;
BA_ "U_U502_MY15_Gas_Tx" SG_ 2008 TesterPhysicalResAPIM 1;
BA_ "U_UP375_MY15_Gas_Tx" SG_ 2008 TesterPhysicalResAPIM 1;
BA_ "U_UP375_MY15_Diesel_Tx" SG_ 2008 TesterPhysicalResAPIM 1;
BA_ "U_CD43_MY16_Gas_Tx" SG_ 2008 TesterPhysicalResAPIM 1;
BA_ "GenSigSendType" SG_ 772 MemDrvDeny_B_Stat 3;
BA_ "U_CD42_MY15_Diesel_Tx" SG_ 772 MemDrvDeny_B_Stat 1;
BA_ "U_CD42_MY15_Gas_Tx" SG_ 772 MemDrvDeny_B_Stat 1;
BA_ "U_C489_MY14_Gas_Tx" SG_ 772 MemDrvDeny_B_Stat 1;
BA_ "Gateway_ID" SG_ 772 MemDrvDeny_B_Stat 27532;
BA_ "WakeupSignal" SG_ 772 Memory_Feedback_Rqst 1;
BA_ "CrossOver_InfoCAN" SG_ 772 Memory_Feedback_Rqst 1;
BA_ "GenSigSendType" SG_ 772 Memory_Feedback_Rqst 3;
BA_ "U_CD4_MY13_Diesel_Rx" SG_ 772 Memory_Feedback_Rqst 1;
BA_ "U_CD4_MY13_Gas_Rx" SG_ 772 Memory_Feedback_Rqst 1;
BA_ "U_CD4_MY13_Hev_Rx" SG_ 772 Memory_Feedback_Rqst 1;
BA_ "U_CD4_MY13_Phev_Rx" SG_ 772 Memory_Feedback_Rqst 1;
BA_ "U_CD42_MY14_Diesel_Rx" SG_ 772 Memory_Feedback_Rqst 1;
BA_ "U_CD42_MY14_Gas_Rx" SG_ 772 Memory_Feedback_Rqst 1;
BA_ "U_P552_MY15_Gas_Rx" SG_ 772 Memory_Feedback_Rqst 1;
BA_ "U_S550_MY15_Gas_Rx" SG_ 772 Memory_Feedback_Rqst 1;
BA_ "U_C489_MY14_Gas_Rx" SG_ 772 Memory_Feedback_Rqst 1;
BA_ "U_U502_MY15_Gas_Rx" SG_ 772 Memory_Feedback_Rqst 1;
BA_ "U_B479_MY15_Gas_Rx" SG_ 772 Memory_Feedback_Rqst 1;
BA_ "U_UP375_MY15_Gas_Rx" SG_ 772 Memory_Feedback_Rqst 1;
BA_ "U_UP375_MY15_Diesel_Rx" SG_ 772 Memory_Feedback_Rqst 1;
BA_ "U_CD4_MY13_Diesel_Tx" SG_ 772 Memory_Feedback_Rqst 1;
BA_ "U_CD4_MY13_Gas_Tx" SG_ 772 Memory_Feedback_Rqst 1;
BA_ "U_CD4_MY13_Hev_Tx" SG_ 772 Memory_Feedback_Rqst 1;
BA_ "U_CD4_MY13_Phev_Tx" SG_ 772 Memory_Feedback_Rqst 1;
BA_ "U_CD42_MY14_Diesel_Tx" SG_ 772 Memory_Feedback_Rqst 1;
BA_ "U_CD42_MY14_Gas_Tx" SG_ 772 Memory_Feedback_Rqst 1;
BA_ "U_P552_MY15_Gas_Tx" SG_ 772 Memory_Feedback_Rqst 1;
BA_ "U_S550_MY15_Gas_Tx" SG_ 772 Memory_Feedback_Rqst 1;
BA_ "U_C489_MY14_Gas_Tx" SG_ 772 Memory_Feedback_Rqst 1;
BA_ "U_U502_MY15_Gas_Tx" SG_ 772 Memory_Feedback_Rqst 1;
BA_ "U_CD43_MY16_Gas_Tx" SG_ 772 Memory_Feedback_Rqst 1;
BA_ "WakeupSignal" SG_ 772 Easy_Entry_Rqst 1;
BA_ "GenSigSendType" SG_ 772 Easy_Entry_Rqst 3;
BA_ "U_CD4_MY13_Diesel_Rx" SG_ 772 Easy_Entry_Rqst 1;
BA_ "U_CD4_MY13_Gas_Rx" SG_ 772 Easy_Entry_Rqst 1;
BA_ "U_CD4_MY13_Hev_Rx" SG_ 772 Easy_Entry_Rqst 1;
BA_ "U_CD4_MY13_Phev_Rx" SG_ 772 Easy_Entry_Rqst 1;
BA_ "U_CD42_MY14_Diesel_Rx" SG_ 772 Easy_Entry_Rqst 1;
BA_ "U_CD42_MY14_Gas_Rx" SG_ 772 Easy_Entry_Rqst 1;
BA_ "U_P552_MY15_Gas_Rx" SG_ 772 Easy_Entry_Rqst 1;
BA_ "U_U502_MY15_Gas_Rx" SG_ 772 Easy_Entry_Rqst 1;
BA_ "U_CD43_MY16_Gas_Rx" SG_ 772 Easy_Entry_Rqst 1;
BA_ "U_CD4_MY13_Diesel_Tx" SG_ 772 Easy_Entry_Rqst 1;
BA_ "U_CD4_MY13_Gas_Tx" SG_ 772 Easy_Entry_Rqst 1;
BA_ "U_CD4_MY13_Hev_Tx" SG_ 772 Easy_Entry_Rqst 1;
BA_ "U_CD4_MY13_Phev_Tx" SG_ 772 Easy_Entry_Rqst 1;
BA_ "U_CD42_MY14_Diesel_Tx" SG_ 772 Easy_Entry_Rqst 1;
BA_ "U_CD42_MY14_Gas_Tx" SG_ 772 Easy_Entry_Rqst 1;
BA_ "U_P552_MY15_Gas_Tx" SG_ 772 Easy_Entry_Rqst 1;
BA_ "U_S550_MY15_Gas_Tx" SG_ 772 Easy_Entry_Rqst 1;
BA_ "U_C489_MY14_Gas_Tx" SG_ 772 Easy_Entry_Rqst 1;
BA_ "U_U502_MY15_Gas_Tx" SG_ 772 Easy_Entry_Rqst 1;
BA_ "U_CD43_MY16_Gas_Tx" SG_ 772 Easy_Entry_Rqst 1;
BA_ "WakeupSignal" SG_ 772 Memory_Cmd 1;
BA_ "GenSigSendType" SG_ 772 Memory_Cmd 3;
BA_ "U_CD4_MY13_Diesel_Rx" SG_ 772 Memory_Cmd 1;
BA_ "U_CD4_MY13_Gas_Rx" SG_ 772 Memory_Cmd 1;
BA_ "U_CD4_MY13_Hev_Rx" SG_ 772 Memory_Cmd 1;
BA_ "U_CD4_MY13_Phev_Rx" SG_ 772 Memory_Cmd 1;
BA_ "U_CD42_MY14_Diesel_Rx" SG_ 772 Memory_Cmd 1;
BA_ "U_CD42_MY14_Gas_Rx" SG_ 772 Memory_Cmd 1;
BA_ "U_P552_MY15_Gas_Rx" SG_ 772 Memory_Cmd 1;
BA_ "U_U502_MY15_Gas_Rx" SG_ 772 Memory_Cmd 1;
BA_ "U_CD43_MY16_Gas_Rx" SG_ 772 Memory_Cmd 1;
BA_ "U_S550_MY15_Gas_Rx" SG_ 772 Memory_Cmd 1;
BA_ "U_UP375_MY15_Gas_Rx" SG_ 772 Memory_Cmd 1;
BA_ "U_UP375_MY15_Diesel_Rx" SG_ 772 Memory_Cmd 1;
BA_ "U_CD4_MY14_Diesel_Rx" SG_ 772 Memory_Cmd 1;
BA_ "U_CD4_MY14_Gas_Rx" SG_ 772 Memory_Cmd 1;
BA_ "U_CD4_MY14_Hev_Rx" SG_ 772 Memory_Cmd 1;
BA_ "U_CD4_MY14_Phev_Rx" SG_ 772 Memory_Cmd 1;
BA_ "U_CD4_MY13_Diesel_Tx" SG_ 772 Memory_Cmd 1;
BA_ "U_CD4_MY13_Gas_Tx" SG_ 772 Memory_Cmd 1;
BA_ "U_CD4_MY13_Hev_Tx" SG_ 772 Memory_Cmd 1;
BA_ "U_CD4_MY13_Phev_Tx" SG_ 772 Memory_Cmd 1;
BA_ "U_CD42_MY14_Diesel_Tx" SG_ 772 Memory_Cmd 1;
BA_ "U_CD42_MY14_Gas_Tx" SG_ 772 Memory_Cmd 1;
BA_ "U_P552_MY15_Gas_Tx" SG_ 772 Memory_Cmd 1;
BA_ "U_S550_MY15_Gas_Tx" SG_ 772 Memory_Cmd 1;
BA_ "U_C489_MY14_Gas_Tx" SG_ 772 Memory_Cmd 1;
BA_ "U_U502_MY15_Gas_Tx" SG_ 772 Memory_Cmd 1;
BA_ "U_CD43_MY16_Gas_Tx" SG_ 772 Memory_Cmd 1;
BA_ "WakeupSignal" SG_ 772 Cancel_Auto_Movement 1;
BA_ "GenSigSendType" SG_ 772 Cancel_Auto_Movement 3;
BA_ "U_CD4_MY13_Diesel_Rx" SG_ 772 Cancel_Auto_Movement 1;
BA_ "U_CD4_MY13_Gas_Rx" SG_ 772 Cancel_Auto_Movement 1;
BA_ "U_CD4_MY13_Hev_Rx" SG_ 772 Cancel_Auto_Movement 1;
BA_ "U_CD4_MY13_Phev_Rx" SG_ 772 Cancel_Auto_Movement 1;
BA_ "U_CD42_MY14_Diesel_Rx" SG_ 772 Cancel_Auto_Movement 1;
BA_ "U_CD42_MY14_Gas_Rx" SG_ 772 Cancel_Auto_Movement 1;
BA_ "U_P552_MY15_Gas_Rx" SG_ 772 Cancel_Auto_Movement 1;
BA_ "U_C489_MY14_Gas_Rx" SG_ 772 Cancel_Auto_Movement 1;
BA_ "U_U502_MY15_Gas_Rx" SG_ 772 Cancel_Auto_Movement 1;
BA_ "U_CD43_MY16_Gas_Rx" SG_ 772 Cancel_Auto_Movement 1;
BA_ "U_S550_MY15_Gas_Rx" SG_ 772 Cancel_Auto_Movement 1;
BA_ "U_UP375_MY15_Gas_Rx" SG_ 772 Cancel_Auto_Movement 1;
BA_ "U_UP375_MY15_Diesel_Rx" SG_ 772 Cancel_Auto_Movement 1;
BA_ "U_CD4_MY14_Diesel_Rx" SG_ 772 Cancel_Auto_Movement 1;
BA_ "U_CD4_MY14_Gas_Rx" SG_ 772 Cancel_Auto_Movement 1;
BA_ "U_CD4_MY14_Hev_Rx" SG_ 772 Cancel_Auto_Movement 1;
BA_ "U_CD4_MY14_Phev_Rx" SG_ 772 Cancel_Auto_Movement 1;
BA_ "U_CD4_MY13_Diesel_Tx" SG_ 772 Cancel_Auto_Movement 1;
BA_ "U_CD4_MY13_Gas_Tx" SG_ 772 Cancel_Auto_Movement 1;
BA_ "U_CD4_MY13_Hev_Tx" SG_ 772 Cancel_Auto_Movement 1;
BA_ "U_CD4_MY13_Phev_Tx" SG_ 772 Cancel_Auto_Movement 1;
BA_ "U_CD42_MY14_Diesel_Tx" SG_ 772 Cancel_Auto_Movement 1;
BA_ "U_CD42_MY14_Gas_Tx" SG_ 772 Cancel_Auto_Movement 1;
BA_ "U_P552_MY15_Gas_Tx" SG_ 772 Cancel_Auto_Movement 1;
BA_ "U_S550_MY15_Gas_Tx" SG_ 772 Cancel_Auto_Movement 1;
BA_ "U_C489_MY14_Gas_Tx" SG_ 772 Cancel_Auto_Movement 1;
BA_ "U_U502_MY15_Gas_Tx" SG_ 772 Cancel_Auto_Movement 1;
BA_ "U_CD43_MY16_Gas_Tx" SG_ 772 Cancel_Auto_Movement 1;
BA_ "GenSigSendType" SG_ 935 CtaAlrtRight2_D_Stat 3;
BA_ "U_P558_MY17_Diesel_Tx" SG_ 935 CtaAlrtRight2_D_Stat 1;
BA_ "U_P558_MY17_Gas_Tx" SG_ 935 CtaAlrtRight2_D_Stat 1;
BA_ "GenSigSendType" SG_ 935 BttRight_D_Stat 3;
BA_ "U_P558_MY17_Diesel_Tx" SG_ 935 BttRight_D_Stat 1;
BA_ "U_P558_MY17_Gas_Tx" SG_ 935 BttRight_D_Stat 1;
BA_ "U_P558_MY17_Diesel_Rx" SG_ 935 BttRight_D_Stat 1;
BA_ "U_P558_MY17_Gas_Rx" SG_ 935 BttRight_D_Stat 1;
BA_ "GenSigSendType" SG_ 935 BttRight_D_RqDrv 3;
BA_ "U_P558_MY17_Diesel_Tx" SG_ 935 BttRight_D_RqDrv 1;
BA_ "U_P558_MY17_Gas_Tx" SG_ 935 BttRight_D_RqDrv 1;
BA_ "U_P558_MY17_Diesel_Rx" SG_ 935 BttRight_D_RqDrv 1;
BA_ "U_P558_MY17_Gas_Rx" SG_ 935 BttRight_D_RqDrv 1;
BA_ "CrossOver_InfoCAN" SG_ 935 Side_Detect_R_Illum 1;
BA_ "GenSigStartValue" SG_ 935 Side_Detect_R_Illum 100;
BA_ "GenSigSendType" SG_ 935 Side_Detect_R_Illum 3;
BA_ "U_CD4_MY13_Diesel_Rx" SG_ 935 Side_Detect_R_Illum 1;
BA_ "U_CD4_MY13_Gas_Rx" SG_ 935 Side_Detect_R_Illum 1;
BA_ "U_CD4_MY13_Hev_Rx" SG_ 935 Side_Detect_R_Illum 1;
BA_ "U_CD4_MY13_Phev_Rx" SG_ 935 Side_Detect_R_Illum 1;
BA_ "U_CD42_MY14_Diesel_Rx" SG_ 935 Side_Detect_R_Illum 1;
BA_ "U_CD42_MY14_Gas_Rx" SG_ 935 Side_Detect_R_Illum 1;
BA_ "U_P552_MY15_Gas_Rx" SG_ 935 Side_Detect_R_Illum 1;
BA_ "U_S550_MY15_Gas_Rx" SG_ 935 Side_Detect_R_Illum 1;
BA_ "U_C489_MY14_Gas_Rx" SG_ 935 Side_Detect_R_Illum 1;
BA_ "U_U502_MY15_Gas_Rx" SG_ 935 Side_Detect_R_Illum 1;
BA_ "U_UP375_MY15_Gas_Rx" SG_ 935 Side_Detect_R_Illum 1;
BA_ "U_UP375_MY15_Diesel_Rx" SG_ 935 Side_Detect_R_Illum 1;
BA_ "U_CD43_MY16_Gas_Rx" SG_ 935 Side_Detect_R_Illum 1;
BA_ "U_CD4_MY14_Diesel_Rx" SG_ 935 Side_Detect_R_Illum 1;
BA_ "U_CD4_MY14_Gas_Rx" SG_ 935 Side_Detect_R_Illum 1;
BA_ "U_CD4_MY14_Hev_Rx" SG_ 935 Side_Detect_R_Illum 1;
BA_ "U_CD4_MY14_Phev_Rx" SG_ 935 Side_Detect_R_Illum 1;
BA_ "U_CD4_MY13_Diesel_Tx" SG_ 935 Side_Detect_R_Illum 1;
BA_ "U_CD4_MY13_Gas_Tx" SG_ 935 Side_Detect_R_Illum 1;
BA_ "U_CD4_MY13_Hev_Tx" SG_ 935 Side_Detect_R_Illum 1;
BA_ "U_CD4_MY13_Phev_Tx" SG_ 935 Side_Detect_R_Illum 1;
BA_ "U_CD42_MY14_Diesel_Tx" SG_ 935 Side_Detect_R_Illum 1;
BA_ "U_CD42_MY14_Gas_Tx" SG_ 935 Side_Detect_R_Illum 1;
BA_ "U_P552_MY15_Gas_Tx" SG_ 935 Side_Detect_R_Illum 1;
BA_ "U_S550_MY15_Gas_Tx" SG_ 935 Side_Detect_R_Illum 1;
BA_ "U_C489_MY14_Gas_Tx" SG_ 935 Side_Detect_R_Illum 1;
BA_ "U_U502_MY15_Gas_Tx" SG_ 935 Side_Detect_R_Illum 1;
BA_ "U_UP375_MY15_Gas_Tx" SG_ 935 Side_Detect_R_Illum 1;
BA_ "U_UP375_MY15_Diesel_Tx" SG_ 935 Side_Detect_R_Illum 1;
BA_ "U_CD43_MY16_Gas_Tx" SG_ 935 Side_Detect_R_Illum 1;
BA_ "CrossOver_InfoCAN" SG_ 935 CtaSnsRight_D_Stat 1;
BA_ "GenSigSendType" SG_ 935 CtaSnsRight_D_Stat 3;
BA_ "U_CD4_MY13_Diesel_Rx" SG_ 935 CtaSnsRight_D_Stat 1;
BA_ "U_CD4_MY13_Gas_Rx" SG_ 935 CtaSnsRight_D_Stat 1;
BA_ "U_CD4_MY13_Hev_Rx" SG_ 935 CtaSnsRight_D_Stat 1;
BA_ "U_CD4_MY13_Phev_Rx" SG_ 935 CtaSnsRight_D_Stat 1;
BA_ "U_CD42_MY14_Diesel_Rx" SG_ 935 CtaSnsRight_D_Stat 1;
BA_ "U_CD42_MY14_Gas_Rx" SG_ 935 CtaSnsRight_D_Stat 1;
BA_ "U_P552_MY15_Gas_Rx" SG_ 935 CtaSnsRight_D_Stat 1;
BA_ "U_S550_MY15_Gas_Rx" SG_ 935 CtaSnsRight_D_Stat 1;
BA_ "U_C489_MY14_Gas_Rx" SG_ 935 CtaSnsRight_D_Stat 1;
BA_ "U_U502_MY15_Gas_Rx" SG_ 935 CtaSnsRight_D_Stat 1;
BA_ "U_UP375_MY15_Gas_Rx" SG_ 935 CtaSnsRight_D_Stat 1;
BA_ "U_UP375_MY15_Diesel_Rx" SG_ 935 CtaSnsRight_D_Stat 1;
BA_ "U_CD43_MY16_Gas_Rx" SG_ 935 CtaSnsRight_D_Stat 1;
BA_ "U_CD4_MY13_Diesel_Tx" SG_ 935 CtaSnsRight_D_Stat 1;
BA_ "U_CD4_MY13_Gas_Tx" SG_ 935 CtaSnsRight_D_Stat 1;
BA_ "U_CD4_MY13_Hev_Tx" SG_ 935 CtaSnsRight_D_Stat 1;
BA_ "U_CD4_MY13_Phev_Tx" SG_ 935 CtaSnsRight_D_Stat 1;
BA_ "U_CD42_MY14_Diesel_Tx" SG_ 935 CtaSnsRight_D_Stat 1;
BA_ "U_CD42_MY14_Gas_Tx" SG_ 935 CtaSnsRight_D_Stat 1;
BA_ "U_P552_MY15_Gas_Tx" SG_ 935 CtaSnsRight_D_Stat 1;
BA_ "U_S550_MY15_Gas_Tx" SG_ 935 CtaSnsRight_D_Stat 1;
BA_ "U_C489_MY14_Gas_Tx" SG_ 935 CtaSnsRight_D_Stat 1;
BA_ "U_U502_MY15_Gas_Tx" SG_ 935 CtaSnsRight_D_Stat 1;
BA_ "U_UP375_MY15_Gas_Tx" SG_ 935 CtaSnsRight_D_Stat 1;
BA_ "U_UP375_MY15_Diesel_Tx" SG_ 935 CtaSnsRight_D_Stat 1;
BA_ "U_CD43_MY16_Gas_Tx" SG_ 935 CtaSnsRight_D_Stat 1;
BA_ "CrossOver_InfoCAN" SG_ 935 CtaAlrtRight_D_Stat 1;
BA_ "GenSigSendType" SG_ 935 CtaAlrtRight_D_Stat 3;
BA_ "U_CD4_MY13_Diesel_Rx" SG_ 935 CtaAlrtRight_D_Stat 1;
BA_ "U_CD4_MY13_Gas_Rx" SG_ 935 CtaAlrtRight_D_Stat 1;
BA_ "U_CD4_MY13_Hev_Rx" SG_ 935 CtaAlrtRight_D_Stat 1;
BA_ "U_CD4_MY13_Phev_Rx" SG_ 935 CtaAlrtRight_D_Stat 1;
BA_ "U_CD42_MY14_Diesel_Rx" SG_ 935 CtaAlrtRight_D_Stat 1;
BA_ "U_CD42_MY14_Gas_Rx" SG_ 935 CtaAlrtRight_D_Stat 1;
BA_ "U_P552_MY15_Gas_Rx" SG_ 935 CtaAlrtRight_D_Stat 1;
BA_ "U_S550_MY15_Gas_Rx" SG_ 935 CtaAlrtRight_D_Stat 1;
BA_ "U_C489_MY14_Gas_Rx" SG_ 935 CtaAlrtRight_D_Stat 1;
BA_ "U_U502_MY15_Gas_Rx" SG_ 935 CtaAlrtRight_D_Stat 1;
BA_ "U_UP375_MY15_Gas_Rx" SG_ 935 CtaAlrtRight_D_Stat 1;
BA_ "U_UP375_MY15_Diesel_Rx" SG_ 935 CtaAlrtRight_D_Stat 1;
BA_ "U_CD43_MY16_Gas_Rx" SG_ 935 CtaAlrtRight_D_Stat 1;
BA_ "U_CD4_MY14_Diesel_Rx" SG_ 935 CtaAlrtRight_D_Stat 1;
BA_ "U_CD4_MY14_Gas_Rx" SG_ 935 CtaAlrtRight_D_Stat 1;
BA_ "U_CD4_MY14_Hev_Rx" SG_ 935 CtaAlrtRight_D_Stat 1;
BA_ "U_CD4_MY14_Phev_Rx" SG_ 935 CtaAlrtRight_D_Stat 1;
BA_ "U_CD4_MY13_Diesel_Tx" SG_ 935 CtaAlrtRight_D_Stat 1;
BA_ "U_CD4_MY13_Gas_Tx" SG_ 935 CtaAlrtRight_D_Stat 1;
BA_ "U_CD4_MY13_Hev_Tx" SG_ 935 CtaAlrtRight_D_Stat 1;
BA_ "U_CD4_MY13_Phev_Tx" SG_ 935 CtaAlrtRight_D_Stat 1;
BA_ "U_CD42_MY14_Diesel_Tx" SG_ 935 CtaAlrtRight_D_Stat 1;
BA_ "U_CD42_MY14_Gas_Tx" SG_ 935 CtaAlrtRight_D_Stat 1;
BA_ "U_P552_MY15_Gas_Tx" SG_ 935 CtaAlrtRight_D_Stat 1;
BA_ "U_S550_MY15_Gas_Tx" SG_ 935 CtaAlrtRight_D_Stat 1;
BA_ "U_C489_MY14_Gas_Tx" SG_ 935 CtaAlrtRight_D_Stat 1;
BA_ "U_U502_MY15_Gas_Tx" SG_ 935 CtaAlrtRight_D_Stat 1;
BA_ "U_UP375_MY15_Gas_Tx" SG_ 935 CtaAlrtRight_D_Stat 1;
BA_ "U_UP375_MY15_Diesel_Tx" SG_ 935 CtaAlrtRight_D_Stat 1;
BA_ "U_CD43_MY16_Gas_Tx" SG_ 935 CtaAlrtRight_D_Stat 1;
BA_ "CrossOver_InfoCAN" SG_ 935 CtaRight_D_Stat 1;
BA_ "GenSigSendType" SG_ 935 CtaRight_D_Stat 3;
BA_ "U_CD4_MY13_Diesel_Tx" SG_ 935 CtaRight_D_Stat 1;
BA_ "U_CD4_MY13_Gas_Tx" SG_ 935 CtaRight_D_Stat 1;
BA_ "U_CD4_MY13_Hev_Tx" SG_ 935 CtaRight_D_Stat 1;
BA_ "U_CD4_MY13_Phev_Tx" SG_ 935 CtaRight_D_Stat 1;
BA_ "U_CD42_MY14_Diesel_Tx" SG_ 935 CtaRight_D_Stat 1;
BA_ "U_CD42_MY14_Gas_Tx" SG_ 935 CtaRight_D_Stat 1;
BA_ "U_P552_MY15_Gas_Tx" SG_ 935 CtaRight_D_Stat 1;
BA_ "U_S550_MY15_Gas_Tx" SG_ 935 CtaRight_D_Stat 1;
BA_ "U_C489_MY14_Gas_Tx" SG_ 935 CtaRight_D_Stat 1;
BA_ "U_U502_MY15_Gas_Tx" SG_ 935 CtaRight_D_Stat 1;
BA_ "U_UP375_MY15_Gas_Tx" SG_ 935 CtaRight_D_Stat 1;
BA_ "U_UP375_MY15_Diesel_Tx" SG_ 935 CtaRight_D_Stat 1;
BA_ "U_CD43_MY16_Gas_Tx" SG_ 935 CtaRight_D_Stat 1;
BA_ "CrossOver_InfoCAN" SG_ 935 SodRight_D_Stat 1;
BA_ "GenSigStartValue" SG_ 935 SodRight_D_Stat 2;
BA_ "GenSigSendType" SG_ 935 SodRight_D_Stat 3;
BA_ "U_CD4_MY13_Diesel_Tx" SG_ 935 SodRight_D_Stat 1;
BA_ "U_CD4_MY13_Gas_Tx" SG_ 935 SodRight_D_Stat 1;
BA_ "U_CD4_MY13_Hev_Tx" SG_ 935 SodRight_D_Stat 1;
BA_ "U_CD4_MY13_Phev_Tx" SG_ 935 SodRight_D_Stat 1;
BA_ "U_CD42_MY14_Diesel_Tx" SG_ 935 SodRight_D_Stat 1;
BA_ "U_CD42_MY14_Gas_Tx" SG_ 935 SodRight_D_Stat 1;
BA_ "U_P552_MY15_Gas_Tx" SG_ 935 SodRight_D_Stat 1;
BA_ "U_S550_MY15_Gas_Tx" SG_ 935 SodRight_D_Stat 1;
BA_ "U_C489_MY14_Gas_Tx" SG_ 935 SodRight_D_Stat 1;
BA_ "U_U502_MY15_Gas_Tx" SG_ 935 SodRight_D_Stat 1;
BA_ "U_UP375_MY15_Gas_Tx" SG_ 935 SodRight_D_Stat 1;
BA_ "U_UP375_MY15_Diesel_Tx" SG_ 935 SodRight_D_Stat 1;
BA_ "U_CD43_MY16_Gas_Tx" SG_ 935 SodRight_D_Stat 1;
BA_ "CrossOver_InfoCAN" SG_ 935 SodSnsRight_D_Stat 1;
BA_ "GenSigSendType" SG_ 935 SodSnsRight_D_Stat 3;
BA_ "U_CD4_MY13_Diesel_Rx" SG_ 935 SodSnsRight_D_Stat 1;
BA_ "U_CD4_MY13_Gas_Rx" SG_ 935 SodSnsRight_D_Stat 1;
BA_ "U_CD4_MY13_Hev_Rx" SG_ 935 SodSnsRight_D_Stat 1;
BA_ "U_CD4_MY13_Phev_Rx" SG_ 935 SodSnsRight_D_Stat 1;
BA_ "U_CD42_MY14_Diesel_Rx" SG_ 935 SodSnsRight_D_Stat 1;
BA_ "U_CD42_MY14_Gas_Rx" SG_ 935 SodSnsRight_D_Stat 1;
BA_ "U_P552_MY15_Gas_Rx" SG_ 935 SodSnsRight_D_Stat 1;
BA_ "U_S550_MY15_Gas_Rx" SG_ 935 SodSnsRight_D_Stat 1;
BA_ "U_C489_MY14_Gas_Rx" SG_ 935 SodSnsRight_D_Stat 1;
BA_ "U_U502_MY15_Gas_Rx" SG_ 935 SodSnsRight_D_Stat 1;
BA_ "U_UP375_MY15_Gas_Rx" SG_ 935 SodSnsRight_D_Stat 1;
BA_ "U_UP375_MY15_Diesel_Rx" SG_ 935 SodSnsRight_D_Stat 1;
BA_ "U_CD43_MY16_Gas_Rx" SG_ 935 SodSnsRight_D_Stat 1;
BA_ "U_CD4_MY14_Diesel_Rx" SG_ 935 SodSnsRight_D_Stat 1;
BA_ "U_CD4_MY14_Gas_Rx" SG_ 935 SodSnsRight_D_Stat 1;
BA_ "U_CD4_MY14_Hev_Rx" SG_ 935 SodSnsRight_D_Stat 1;
BA_ "U_CD4_MY14_Phev_Rx" SG_ 935 SodSnsRight_D_Stat 1;
BA_ "U_CD4_MY13_Diesel_Tx" SG_ 935 SodSnsRight_D_Stat 1;
BA_ "U_CD4_MY13_Gas_Tx" SG_ 935 SodSnsRight_D_Stat 1;
BA_ "U_CD4_MY13_Hev_Tx" SG_ 935 SodSnsRight_D_Stat 1;
BA_ "U_CD4_MY13_Phev_Tx" SG_ 935 SodSnsRight_D_Stat 1;
BA_ "U_CD42_MY14_Diesel_Tx" SG_ 935 SodSnsRight_D_Stat 1;
BA_ "U_CD42_MY14_Gas_Tx" SG_ 935 SodSnsRight_D_Stat 1;
BA_ "U_P552_MY15_Gas_Tx" SG_ 935 SodSnsRight_D_Stat 1;
BA_ "U_S550_MY15_Gas_Tx" SG_ 935 SodSnsRight_D_Stat 1;
BA_ "U_C489_MY14_Gas_Tx" SG_ 935 SodSnsRight_D_Stat 1;
BA_ "U_U502_MY15_Gas_Tx" SG_ 935 SodSnsRight_D_Stat 1;
BA_ "U_UP375_MY15_Gas_Tx" SG_ 935 SodSnsRight_D_Stat 1;
BA_ "U_UP375_MY15_Diesel_Tx" SG_ 935 SodSnsRight_D_Stat 1;
BA_ "U_CD43_MY16_Gas_Tx" SG_ 935 SodSnsRight_D_Stat 1;
BA_ "CrossOver_InfoCAN" SG_ 935 SodAlrtRight_D_Stat 1;
BA_ "GenSigSendType" SG_ 935 SodAlrtRight_D_Stat 3;
BA_ "U_CD4_MY13_Diesel_Rx" SG_ 935 SodAlrtRight_D_Stat 1;
BA_ "U_CD4_MY13_Gas_Rx" SG_ 935 SodAlrtRight_D_Stat 1;
BA_ "U_CD4_MY13_Hev_Rx" SG_ 935 SodAlrtRight_D_Stat 1;
BA_ "U_CD4_MY13_Phev_Rx" SG_ 935 SodAlrtRight_D_Stat 1;
BA_ "U_CD42_MY14_Diesel_Rx" SG_ 935 SodAlrtRight_D_Stat 1;
BA_ "U_CD42_MY14_Gas_Rx" SG_ 935 SodAlrtRight_D_Stat 1;
BA_ "U_P552_MY15_Gas_Rx" SG_ 935 SodAlrtRight_D_Stat 1;
BA_ "U_S550_MY15_Gas_Rx" SG_ 935 SodAlrtRight_D_Stat 1;
BA_ "U_C489_MY14_Gas_Rx" SG_ 935 SodAlrtRight_D_Stat 1;
BA_ "U_U502_MY15_Gas_Rx" SG_ 935 SodAlrtRight_D_Stat 1;
BA_ "U_UP375_MY15_Gas_Rx" SG_ 935 SodAlrtRight_D_Stat 1;
BA_ "U_UP375_MY15_Diesel_Rx" SG_ 935 SodAlrtRight_D_Stat 1;
BA_ "U_CD43_MY16_Gas_Rx" SG_ 935 SodAlrtRight_D_Stat 1;
BA_ "U_CD4_MY14_Diesel_Rx" SG_ 935 SodAlrtRight_D_Stat 1;
BA_ "U_CD4_MY14_Gas_Rx" SG_ 935 SodAlrtRight_D_Stat 1;
BA_ "U_CD4_MY14_Hev_Rx" SG_ 935 SodAlrtRight_D_Stat 1;
BA_ "U_CD4_MY14_Phev_Rx" SG_ 935 SodAlrtRight_D_Stat 1;
BA_ "U_CD4_MY13_Diesel_Tx" SG_ 935 SodAlrtRight_D_Stat 1;
BA_ "U_CD4_MY13_Gas_Tx" SG_ 935 SodAlrtRight_D_Stat 1;
BA_ "U_CD4_MY13_Hev_Tx" SG_ 935 SodAlrtRight_D_Stat 1;
BA_ "U_CD4_MY13_Phev_Tx" SG_ 935 SodAlrtRight_D_Stat 1;
BA_ "U_CD42_MY14_Diesel_Tx" SG_ 935 SodAlrtRight_D_Stat 1;
BA_ "U_CD42_MY14_Gas_Tx" SG_ 935 SodAlrtRight_D_Stat 1;
BA_ "U_P552_MY15_Gas_Tx" SG_ 935 SodAlrtRight_D_Stat 1;
BA_ "U_S550_MY15_Gas_Tx" SG_ 935 SodAlrtRight_D_Stat 1;
BA_ "U_C489_MY14_Gas_Tx" SG_ 935 SodAlrtRight_D_Stat 1;
BA_ "U_U502_MY15_Gas_Tx" SG_ 935 SodAlrtRight_D_Stat 1;
BA_ "U_UP375_MY15_Gas_Tx" SG_ 935 SodAlrtRight_D_Stat 1;
BA_ "U_UP375_MY15_Diesel_Tx" SG_ 935 SodAlrtRight_D_Stat 1;
BA_ "U_CD43_MY16_Gas_Tx" SG_ 935 SodAlrtRight_D_Stat 1;
BA_ "CrossOver_InfoCAN" SG_ 935 SodDetctRight_D_Stat 1;
BA_ "GenSigSendType" SG_ 935 SodDetctRight_D_Stat 3;
BA_ "U_CD4_MY13_Diesel_Tx" SG_ 935 SodDetctRight_D_Stat 1;
BA_ "U_CD4_MY13_Gas_Tx" SG_ 935 SodDetctRight_D_Stat 1;
BA_ "U_CD4_MY13_Hev_Tx" SG_ 935 SodDetctRight_D_Stat 1;
BA_ "U_CD4_MY13_Phev_Tx" SG_ 935 SodDetctRight_D_Stat 1;
BA_ "U_CD42_MY14_Diesel_Tx" SG_ 935 SodDetctRight_D_Stat 1;
BA_ "U_CD42_MY14_Gas_Tx" SG_ 935 SodDetctRight_D_Stat 1;
BA_ "U_P552_MY15_Gas_Tx" SG_ 935 SodDetctRight_D_Stat 1;
BA_ "U_S550_MY15_Gas_Tx" SG_ 935 SodDetctRight_D_Stat 1;
BA_ "U_C489_MY14_Gas_Tx" SG_ 935 SodDetctRight_D_Stat 1;
BA_ "U_U502_MY15_Gas_Tx" SG_ 935 SodDetctRight_D_Stat 1;
BA_ "U_UP375_MY15_Gas_Tx" SG_ 935 SodDetctRight_D_Stat 1;
BA_ "U_UP375_MY15_Diesel_Tx" SG_ 935 SodDetctRight_D_Stat 1;
BA_ "U_CD43_MY16_Gas_Tx" SG_ 935 SodDetctRight_D_Stat 1;
BA_ "CrossOver_InfoCAN" SG_ 935 SodWarnRight_Prd_Rq 1;
BA_ "GenSigStartValue" SG_ 935 SodWarnRight_Prd_Rq 14;
BA_ "GenSigSendType" SG_ 935 SodWarnRight_Prd_Rq 3;
BA_ "U_CD4_MY13_Diesel_Rx" SG_ 935 SodWarnRight_Prd_Rq 1;
BA_ "U_CD4_MY13_Gas_Rx" SG_ 935 SodWarnRight_Prd_Rq 1;
BA_ "U_CD4_MY13_Hev_Rx" SG_ 935 SodWarnRight_Prd_Rq 1;
BA_ "U_CD4_MY13_Phev_Rx" SG_ 935 SodWarnRight_Prd_Rq 1;
BA_ "U_CD42_MY14_Diesel_Rx" SG_ 935 SodWarnRight_Prd_Rq 1;
BA_ "U_CD42_MY14_Gas_Rx" SG_ 935 SodWarnRight_Prd_Rq 1;
BA_ "U_P552_MY15_Gas_Rx" SG_ 935 SodWarnRight_Prd_Rq 1;
BA_ "U_S550_MY15_Gas_Rx" SG_ 935 SodWarnRight_Prd_Rq 1;
BA_ "U_C489_MY14_Gas_Rx" SG_ 935 SodWarnRight_Prd_Rq 1;
BA_ "U_U502_MY15_Gas_Rx" SG_ 935 SodWarnRight_Prd_Rq 1;
BA_ "U_UP375_MY15_Gas_Rx" SG_ 935 SodWarnRight_Prd_Rq 1;
BA_ "U_UP375_MY15_Diesel_Rx" SG_ 935 SodWarnRight_Prd_Rq 1;
BA_ "U_CD43_MY16_Gas_Rx" SG_ 935 SodWarnRight_Prd_Rq 1;
BA_ "U_CD4_MY14_Diesel_Rx" SG_ 935 SodWarnRight_Prd_Rq 1;
BA_ "U_CD4_MY14_Gas_Rx" SG_ 935 SodWarnRight_Prd_Rq 1;
BA_ "U_CD4_MY14_Hev_Rx" SG_ 935 SodWarnRight_Prd_Rq 1;
BA_ "U_CD4_MY14_Phev_Rx" SG_ 935 SodWarnRight_Prd_Rq 1;
BA_ "U_CD4_MY13_Diesel_Tx" SG_ 935 SodWarnRight_Prd_Rq 1;
BA_ "U_CD4_MY13_Gas_Tx" SG_ 935 SodWarnRight_Prd_Rq 1;
BA_ "U_CD4_MY13_Hev_Tx" SG_ 935 SodWarnRight_Prd_Rq 1;
BA_ "U_CD4_MY13_Phev_Tx" SG_ 935 SodWarnRight_Prd_Rq 1;
BA_ "U_CD42_MY14_Diesel_Tx" SG_ 935 SodWarnRight_Prd_Rq 1;
BA_ "U_CD42_MY14_Gas_Tx" SG_ 935 SodWarnRight_Prd_Rq 1;
BA_ "U_P552_MY15_Gas_Tx" SG_ 935 SodWarnRight_Prd_Rq 1;
BA_ "U_S550_MY15_Gas_Tx" SG_ 935 SodWarnRight_Prd_Rq 1;
BA_ "U_C489_MY14_Gas_Tx" SG_ 935 SodWarnRight_Prd_Rq 1;
BA_ "U_U502_MY15_Gas_Tx" SG_ 935 SodWarnRight_Prd_Rq 1;
BA_ "U_UP375_MY15_Gas_Tx" SG_ 935 SodWarnRight_Prd_Rq 1;
BA_ "U_UP375_MY15_Diesel_Tx" SG_ 935 SodWarnRight_Prd_Rq 1;
BA_ "U_CD43_MY16_Gas_Tx" SG_ 935 SodWarnRight_Prd_Rq 1;
BA_ "CrossOver_InfoCAN" SG_ 935 SodInnrRight_D_Stat 1;
BA_ "GenSigSendType" SG_ 935 SodInnrRight_D_Stat 3;
BA_ "U_CD4_MY13_Diesel_Rx" SG_ 935 SodInnrRight_D_Stat 1;
BA_ "U_CD4_MY13_Gas_Rx" SG_ 935 SodInnrRight_D_Stat 1;
BA_ "U_CD4_MY13_Hev_Rx" SG_ 935 SodInnrRight_D_Stat 1;
BA_ "U_CD4_MY13_Phev_Rx" SG_ 935 SodInnrRight_D_Stat 1;
BA_ "U_CD42_MY14_Diesel_Rx" SG_ 935 SodInnrRight_D_Stat 1;
BA_ "U_CD42_MY14_Gas_Rx" SG_ 935 SodInnrRight_D_Stat 1;
BA_ "U_P552_MY15_Gas_Rx" SG_ 935 SodInnrRight_D_Stat 1;
BA_ "U_S550_MY15_Gas_Rx" SG_ 935 SodInnrRight_D_Stat 1;
BA_ "U_C489_MY14_Gas_Rx" SG_ 935 SodInnrRight_D_Stat 1;
BA_ "U_U502_MY15_Gas_Rx" SG_ 935 SodInnrRight_D_Stat 1;
BA_ "U_UP375_MY15_Gas_Rx" SG_ 935 SodInnrRight_D_Stat 1;
BA_ "U_UP375_MY15_Diesel_Rx" SG_ 935 SodInnrRight_D_Stat 1;
BA_ "U_CD43_MY16_Gas_Rx" SG_ 935 SodInnrRight_D_Stat 1;
BA_ "U_CD4_MY13_Diesel_Tx" SG_ 935 SodInnrRight_D_Stat 1;
BA_ "U_CD4_MY13_Gas_Tx" SG_ 935 SodInnrRight_D_Stat 1;
BA_ "U_CD4_MY13_Hev_Tx" SG_ 935 SodInnrRight_D_Stat 1;
BA_ "U_CD4_MY13_Phev_Tx" SG_ 935 SodInnrRight_D_Stat 1;
BA_ "U_CD42_MY14_Diesel_Tx" SG_ 935 SodInnrRight_D_Stat 1;
BA_ "U_CD42_MY14_Gas_Tx" SG_ 935 SodInnrRight_D_Stat 1;
BA_ "U_P552_MY15_Gas_Tx" SG_ 935 SodInnrRight_D_Stat 1;
BA_ "U_S550_MY15_Gas_Tx" SG_ 935 SodInnrRight_D_Stat 1;
BA_ "U_C489_MY14_Gas_Tx" SG_ 935 SodInnrRight_D_Stat 1;
BA_ "U_U502_MY15_Gas_Tx" SG_ 935 SodInnrRight_D_Stat 1;
BA_ "U_UP375_MY15_Gas_Tx" SG_ 935 SodInnrRight_D_Stat 1;
BA_ "U_UP375_MY15_Diesel_Tx" SG_ 935 SodInnrRight_D_Stat 1;
BA_ "U_CD43_MY16_Gas_Tx" SG_ 935 SodInnrRight_D_Stat 1;
BA_ "CrossOver_InfoCAN" SG_ 935 CtaInnrRight_D_Stat 1;
BA_ "GenSigSendType" SG_ 935 CtaInnrRight_D_Stat 3;
BA_ "U_CD4_MY13_Diesel_Rx" SG_ 935 CtaInnrRight_D_Stat 1;
BA_ "U_CD4_MY13_Gas_Rx" SG_ 935 CtaInnrRight_D_Stat 1;
BA_ "U_CD4_MY13_Hev_Rx" SG_ 935 CtaInnrRight_D_Stat 1;
BA_ "U_CD4_MY13_Phev_Rx" SG_ 935 CtaInnrRight_D_Stat 1;
BA_ "U_CD42_MY14_Diesel_Rx" SG_ 935 CtaInnrRight_D_Stat 1;
BA_ "U_CD42_MY14_Gas_Rx" SG_ 935 CtaInnrRight_D_Stat 1;
BA_ "U_P552_MY15_Gas_Rx" SG_ 935 CtaInnrRight_D_Stat 1;
BA_ "U_S550_MY15_Gas_Rx" SG_ 935 CtaInnrRight_D_Stat 1;
BA_ "U_C489_MY14_Gas_Rx" SG_ 935 CtaInnrRight_D_Stat 1;
BA_ "U_U502_MY15_Gas_Rx" SG_ 935 CtaInnrRight_D_Stat 1;
BA_ "U_UP375_MY15_Gas_Rx" SG_ 935 CtaInnrRight_D_Stat 1;
BA_ "U_UP375_MY15_Diesel_Rx" SG_ 935 CtaInnrRight_D_Stat 1;
BA_ "U_CD43_MY16_Gas_Rx" SG_ 935 CtaInnrRight_D_Stat 1;
BA_ "U_CD4_MY13_Diesel_Tx" SG_ 935 CtaInnrRight_D_Stat 1;
BA_ "U_CD4_MY13_Gas_Tx" SG_ 935 CtaInnrRight_D_Stat 1;
BA_ "U_CD4_MY13_Hev_Tx" SG_ 935 CtaInnrRight_D_Stat 1;
BA_ "U_CD4_MY13_Phev_Tx" SG_ 935 CtaInnrRight_D_Stat 1;
BA_ "U_CD42_MY14_Diesel_Tx" SG_ 935 CtaInnrRight_D_Stat 1;
BA_ "U_CD42_MY14_Gas_Tx" SG_ 935 CtaInnrRight_D_Stat 1;
BA_ "U_P552_MY15_Gas_Tx" SG_ 935 CtaInnrRight_D_Stat 1;
BA_ "U_S550_MY15_Gas_Tx" SG_ 935 CtaInnrRight_D_Stat 1;
BA_ "U_C489_MY14_Gas_Tx" SG_ 935 CtaInnrRight_D_Stat 1;
BA_ "U_U502_MY15_Gas_Tx" SG_ 935 CtaInnrRight_D_Stat 1;
BA_ "U_UP375_MY15_Gas_Tx" SG_ 935 CtaInnrRight_D_Stat 1;
BA_ "U_UP375_MY15_Diesel_Tx" SG_ 935 CtaInnrRight_D_Stat 1;
BA_ "U_CD43_MY16_Gas_Tx" SG_ 935 CtaInnrRight_D_Stat 1;
BA_ "CrossOver_InfoCAN" SG_ 934 CtaInnrLeft_D_Stat 1;
BA_ "GenSigSendType" SG_ 934 CtaInnrLeft_D_Stat 3;
BA_ "U_CD4_MY13_Diesel_Rx" SG_ 934 CtaInnrLeft_D_Stat 1;
BA_ "U_CD4_MY13_Gas_Rx" SG_ 934 CtaInnrLeft_D_Stat 1;
BA_ "U_CD4_MY13_Hev_Rx" SG_ 934 CtaInnrLeft_D_Stat 1;
BA_ "U_CD4_MY13_Phev_Rx" SG_ 934 CtaInnrLeft_D_Stat 1;
BA_ "U_CD42_MY14_Diesel_Rx" SG_ 934 CtaInnrLeft_D_Stat 1;
BA_ "U_CD42_MY14_Gas_Rx" SG_ 934 CtaInnrLeft_D_Stat 1;
BA_ "U_P552_MY15_Gas_Rx" SG_ 934 CtaInnrLeft_D_Stat 1;
BA_ "U_S550_MY15_Gas_Rx" SG_ 934 CtaInnrLeft_D_Stat 1;
BA_ "U_C489_MY14_Gas_Rx" SG_ 934 CtaInnrLeft_D_Stat 1;
BA_ "U_B562LC_MY14_Gas_Rx" SG_ 934 CtaInnrLeft_D_Stat 1;
BA_ "U_U502_MY15_Gas_Rx" SG_ 934 CtaInnrLeft_D_Stat 1;
BA_ "U_UP375_MY15_Gas_Rx" SG_ 934 CtaInnrLeft_D_Stat 1;
BA_ "U_UP375_MY15_Diesel_Rx" SG_ 934 CtaInnrLeft_D_Stat 1;
BA_ "U_CD43_MY16_Gas_Rx" SG_ 934 CtaInnrLeft_D_Stat 1;
BA_ "U_CD4_MY13_Diesel_Tx" SG_ 934 CtaInnrLeft_D_Stat 1;
BA_ "U_CD4_MY13_Gas_Tx" SG_ 934 CtaInnrLeft_D_Stat 1;
BA_ "U_CD4_MY13_Hev_Tx" SG_ 934 CtaInnrLeft_D_Stat 1;
BA_ "U_CD4_MY13_Phev_Tx" SG_ 934 CtaInnrLeft_D_Stat 1;
BA_ "U_CD42_MY14_Diesel_Tx" SG_ 934 CtaInnrLeft_D_Stat 1;
BA_ "U_CD42_MY14_Gas_Tx" SG_ 934 CtaInnrLeft_D_Stat 1;
BA_ "U_P552_MY15_Gas_Tx" SG_ 934 CtaInnrLeft_D_Stat 1;
BA_ "U_S550_MY15_Gas_Tx" SG_ 934 CtaInnrLeft_D_Stat 1;
BA_ "U_C489_MY14_Gas_Tx" SG_ 934 CtaInnrLeft_D_Stat 1;
BA_ "U_U502_MY15_Gas_Tx" SG_ 934 CtaInnrLeft_D_Stat 1;
BA_ "U_UP375_MY15_Gas_Tx" SG_ 934 CtaInnrLeft_D_Stat 1;
BA_ "U_UP375_MY15_Diesel_Tx" SG_ 934 CtaInnrLeft_D_Stat 1;
BA_ "U_CD43_MY16_Gas_Tx" SG_ 934 CtaInnrLeft_D_Stat 1;
BA_ "GenSigSendType" SG_ 934 CtaAlrtLeft2_D_Stat 3;
BA_ "U_P558_MY17_Diesel_Tx" SG_ 934 CtaAlrtLeft2_D_Stat 1;
BA_ "U_P558_MY17_Gas_Tx" SG_ 934 CtaAlrtLeft2_D_Stat 1;
BA_ "GenSigSendType" SG_ 934 BttLeft_D_Stat 3;
BA_ "U_P558_MY17_Diesel_Tx" SG_ 934 BttLeft_D_Stat 1;
BA_ "U_P558_MY17_Gas_Tx" SG_ 934 BttLeft_D_Stat 1;
BA_ "GenSigSendType" SG_ 934 BttLeft_D_RqDrv 3;
BA_ "U_P558_MY17_Diesel_Tx" SG_ 934 BttLeft_D_RqDrv 1;
BA_ "U_P558_MY17_Gas_Tx" SG_ 934 BttLeft_D_RqDrv 1;
BA_ "CrossOver_InfoCAN" SG_ 934 Side_Detect_L_Illum 1;
BA_ "GenSigStartValue" SG_ 934 Side_Detect_L_Illum 100;
BA_ "GenSigSendType" SG_ 934 Side_Detect_L_Illum 3;
BA_ "U_CD4_MY13_Diesel_Rx" SG_ 934 Side_Detect_L_Illum 1;
BA_ "U_CD4_MY13_Gas_Rx" SG_ 934 Side_Detect_L_Illum 1;
BA_ "U_CD4_MY13_Hev_Rx" SG_ 934 Side_Detect_L_Illum 1;
BA_ "U_CD4_MY13_Phev_Rx" SG_ 934 Side_Detect_L_Illum 1;
BA_ "U_CD42_MY14_Diesel_Rx" SG_ 934 Side_Detect_L_Illum 1;
BA_ "U_CD42_MY14_Gas_Rx" SG_ 934 Side_Detect_L_Illum 1;
BA_ "U_P552_MY15_Gas_Rx" SG_ 934 Side_Detect_L_Illum 1;
BA_ "U_S550_MY15_Gas_Rx" SG_ 934 Side_Detect_L_Illum 1;
BA_ "U_C489_MY14_Gas_Rx" SG_ 934 Side_Detect_L_Illum 1;
BA_ "U_U502_MY15_Gas_Rx" SG_ 934 Side_Detect_L_Illum 1;
BA_ "U_UP375_MY15_Gas_Rx" SG_ 934 Side_Detect_L_Illum 1;
BA_ "U_UP375_MY15_Diesel_Rx" SG_ 934 Side_Detect_L_Illum 1;
BA_ "U_CD43_MY16_Gas_Rx" SG_ 934 Side_Detect_L_Illum 1;
BA_ "U_CD4_MY14_Diesel_Rx" SG_ 934 Side_Detect_L_Illum 1;
BA_ "U_CD4_MY14_Gas_Rx" SG_ 934 Side_Detect_L_Illum 1;
BA_ "U_CD4_MY14_Hev_Rx" SG_ 934 Side_Detect_L_Illum 1;
BA_ "U_CD4_MY14_Phev_Rx" SG_ 934 Side_Detect_L_Illum 1;
BA_ "U_CD4_MY13_Diesel_Tx" SG_ 934 Side_Detect_L_Illum 1;
BA_ "U_CD4_MY13_Gas_Tx" SG_ 934 Side_Detect_L_Illum 1;
BA_ "U_CD4_MY13_Hev_Tx" SG_ 934 Side_Detect_L_Illum 1;
BA_ "U_CD4_MY13_Phev_Tx" SG_ 934 Side_Detect_L_Illum 1;
BA_ "U_CD42_MY14_Diesel_Tx" SG_ 934 Side_Detect_L_Illum 1;
BA_ "U_CD42_MY14_Gas_Tx" SG_ 934 Side_Detect_L_Illum 1;
BA_ "U_P552_MY15_Gas_Tx" SG_ 934 Side_Detect_L_Illum 1;
BA_ "U_S550_MY15_Gas_Tx" SG_ 934 Side_Detect_L_Illum 1;
BA_ "U_C489_MY14_Gas_Tx" SG_ 934 Side_Detect_L_Illum 1;
BA_ "U_U502_MY15_Gas_Tx" SG_ 934 Side_Detect_L_Illum 1;
BA_ "U_UP375_MY15_Gas_Tx" SG_ 934 Side_Detect_L_Illum 1;
BA_ "U_UP375_MY15_Diesel_Tx" SG_ 934 Side_Detect_L_Illum 1;
BA_ "U_CD43_MY16_Gas_Tx" SG_ 934 Side_Detect_L_Illum 1;
BA_ "CrossOver_InfoCAN" SG_ 934 CtaSnsLeft_D_Stat 1;
BA_ "GenSigSendType" SG_ 934 CtaSnsLeft_D_Stat 3;
BA_ "U_CD4_MY13_Diesel_Rx" SG_ 934 CtaSnsLeft_D_Stat 1;
BA_ "U_CD4_MY13_Gas_Rx" SG_ 934 CtaSnsLeft_D_Stat 1;
BA_ "U_CD4_MY13_Hev_Rx" SG_ 934 CtaSnsLeft_D_Stat 1;
BA_ "U_CD4_MY13_Phev_Rx" SG_ 934 CtaSnsLeft_D_Stat 1;
BA_ "U_CD42_MY14_Diesel_Rx" SG_ 934 CtaSnsLeft_D_Stat 1;
BA_ "U_CD42_MY14_Gas_Rx" SG_ 934 CtaSnsLeft_D_Stat 1;
BA_ "U_P552_MY15_Gas_Rx" SG_ 934 CtaSnsLeft_D_Stat 1;
BA_ "U_S550_MY15_Gas_Rx" SG_ 934 CtaSnsLeft_D_Stat 1;
BA_ "U_C489_MY14_Gas_Rx" SG_ 934 CtaSnsLeft_D_Stat 1;
BA_ "U_B562LC_MY14_Gas_Rx" SG_ 934 CtaSnsLeft_D_Stat 1;
BA_ "U_U502_MY15_Gas_Rx" SG_ 934 CtaSnsLeft_D_Stat 1;
BA_ "U_UP375_MY15_Gas_Rx" SG_ 934 CtaSnsLeft_D_Stat 1;
BA_ "U_UP375_MY15_Diesel_Rx" SG_ 934 CtaSnsLeft_D_Stat 1;
BA_ "U_CD43_MY16_Gas_Rx" SG_ 934 CtaSnsLeft_D_Stat 1;
BA_ "U_CD4_MY13_Diesel_Tx" SG_ 934 CtaSnsLeft_D_Stat 1;
BA_ "U_CD4_MY13_Gas_Tx" SG_ 934 CtaSnsLeft_D_Stat 1;
BA_ "U_CD4_MY13_Hev_Tx" SG_ 934 CtaSnsLeft_D_Stat 1;
BA_ "U_CD4_MY13_Phev_Tx" SG_ 934 CtaSnsLeft_D_Stat 1;
BA_ "U_CD42_MY14_Diesel_Tx" SG_ 934 CtaSnsLeft_D_Stat 1;
BA_ "U_CD42_MY14_Gas_Tx" SG_ 934 CtaSnsLeft_D_Stat 1;
BA_ "U_P552_MY15_Gas_Tx" SG_ 934 CtaSnsLeft_D_Stat 1;
BA_ "U_S550_MY15_Gas_Tx" SG_ 934 CtaSnsLeft_D_Stat 1;
BA_ "U_C489_MY14_Gas_Tx" SG_ 934 CtaSnsLeft_D_Stat 1;
BA_ "U_U502_MY15_Gas_Tx" SG_ 934 CtaSnsLeft_D_Stat 1;
BA_ "U_UP375_MY15_Gas_Tx" SG_ 934 CtaSnsLeft_D_Stat 1;
BA_ "U_UP375_MY15_Diesel_Tx" SG_ 934 CtaSnsLeft_D_Stat 1;
BA_ "U_CD43_MY16_Gas_Tx" SG_ 934 CtaSnsLeft_D_Stat 1;
BA_ "CrossOver_InfoCAN" SG_ 934 SodDetctLeft_D_Stat 1;
BA_ "GenSigSendType" SG_ 934 SodDetctLeft_D_Stat 3;
BA_ "U_CD4_MY13_Diesel_Tx" SG_ 934 SodDetctLeft_D_Stat 1;
BA_ "U_CD4_MY13_Gas_Tx" SG_ 934 SodDetctLeft_D_Stat 1;
BA_ "U_CD4_MY13_Hev_Tx" SG_ 934 SodDetctLeft_D_Stat 1;
BA_ "U_CD4_MY13_Phev_Tx" SG_ 934 SodDetctLeft_D_Stat 1;
BA_ "U_CD42_MY14_Diesel_Tx" SG_ 934 SodDetctLeft_D_Stat 1;
BA_ "U_CD42_MY14_Gas_Tx" SG_ 934 SodDetctLeft_D_Stat 1;
BA_ "U_P552_MY15_Gas_Tx" SG_ 934 SodDetctLeft_D_Stat 1;
BA_ "U_S550_MY15_Gas_Tx" SG_ 934 SodDetctLeft_D_Stat 1;
BA_ "U_C489_MY14_Gas_Tx" SG_ 934 SodDetctLeft_D_Stat 1;
BA_ "U_U502_MY15_Gas_Tx" SG_ 934 SodDetctLeft_D_Stat 1;
BA_ "U_UP375_MY15_Gas_Tx" SG_ 934 SodDetctLeft_D_Stat 1;
BA_ "U_UP375_MY15_Diesel_Tx" SG_ 934 SodDetctLeft_D_Stat 1;
BA_ "U_CD43_MY16_Gas_Tx" SG_ 934 SodDetctLeft_D_Stat 1;
BA_ "CrossOver_InfoCAN" SG_ 934 CtaLeft_D_Stat 1;
BA_ "GenSigSendType" SG_ 934 CtaLeft_D_Stat 3;
BA_ "U_CD4_MY13_Diesel_Tx" SG_ 934 CtaLeft_D_Stat 1;
BA_ "U_CD4_MY13_Gas_Tx" SG_ 934 CtaLeft_D_Stat 1;
BA_ "U_CD4_MY13_Hev_Tx" SG_ 934 CtaLeft_D_Stat 1;
BA_ "U_CD4_MY13_Phev_Tx" SG_ 934 CtaLeft_D_Stat 1;
BA_ "U_CD42_MY14_Diesel_Tx" SG_ 934 CtaLeft_D_Stat 1;
BA_ "U_CD42_MY14_Gas_Tx" SG_ 934 CtaLeft_D_Stat 1;
BA_ "U_P552_MY15_Gas_Tx" SG_ 934 CtaLeft_D_Stat 1;
BA_ "U_S550_MY15_Gas_Tx" SG_ 934 CtaLeft_D_Stat 1;
BA_ "U_C489_MY14_Gas_Tx" SG_ 934 CtaLeft_D_Stat 1;
BA_ "U_U502_MY15_Gas_Tx" SG_ 934 CtaLeft_D_Stat 1;
BA_ "U_UP375_MY15_Gas_Tx" SG_ 934 CtaLeft_D_Stat 1;
BA_ "U_UP375_MY15_Diesel_Tx" SG_ 934 CtaLeft_D_Stat 1;
BA_ "U_CD43_MY16_Gas_Tx" SG_ 934 CtaLeft_D_Stat 1;
BA_ "CrossOver_InfoCAN" SG_ 934 CtaAlrtLeft_D_Stat 1;
BA_ "GenSigSendType" SG_ 934 CtaAlrtLeft_D_Stat 3;
BA_ "U_CD4_MY13_Diesel_Rx" SG_ 934 CtaAlrtLeft_D_Stat 1;
BA_ "U_CD4_MY13_Gas_Rx" SG_ 934 CtaAlrtLeft_D_Stat 1;
BA_ "U_CD4_MY13_Hev_Rx" SG_ 934 CtaAlrtLeft_D_Stat 1;
BA_ "U_CD4_MY13_Phev_Rx" SG_ 934 CtaAlrtLeft_D_Stat 1;
BA_ "U_CD42_MY14_Diesel_Rx" SG_ 934 CtaAlrtLeft_D_Stat 1;
BA_ "U_CD42_MY14_Gas_Rx" SG_ 934 CtaAlrtLeft_D_Stat 1;
BA_ "U_P552_MY15_Gas_Rx" SG_ 934 CtaAlrtLeft_D_Stat 1;
BA_ "U_S550_MY15_Gas_Rx" SG_ 934 CtaAlrtLeft_D_Stat 1;
BA_ "U_C489_MY14_Gas_Rx" SG_ 934 CtaAlrtLeft_D_Stat 1;
BA_ "U_U502_MY15_Gas_Rx" SG_ 934 CtaAlrtLeft_D_Stat 1;
BA_ "U_UP375_MY15_Gas_Rx" SG_ 934 CtaAlrtLeft_D_Stat 1;
BA_ "U_UP375_MY15_Diesel_Rx" SG_ 934 CtaAlrtLeft_D_Stat 1;
BA_ "U_CD43_MY16_Gas_Rx" SG_ 934 CtaAlrtLeft_D_Stat 1;
BA_ "U_CD4_MY14_Diesel_Rx" SG_ 934 CtaAlrtLeft_D_Stat 1;
BA_ "U_CD4_MY14_Gas_Rx" SG_ 934 CtaAlrtLeft_D_Stat 1;
BA_ "U_CD4_MY14_Hev_Rx" SG_ 934 CtaAlrtLeft_D_Stat 1;
BA_ "U_CD4_MY14_Phev_Rx" SG_ 934 CtaAlrtLeft_D_Stat 1;
BA_ "U_CD4_MY13_Diesel_Tx" SG_ 934 CtaAlrtLeft_D_Stat 1;
BA_ "U_CD4_MY13_Gas_Tx" SG_ 934 CtaAlrtLeft_D_Stat 1;
BA_ "U_CD4_MY13_Hev_Tx" SG_ 934 CtaAlrtLeft_D_Stat 1;
BA_ "U_CD4_MY13_Phev_Tx" SG_ 934 CtaAlrtLeft_D_Stat 1;
BA_ "U_CD42_MY14_Diesel_Tx" SG_ 934 CtaAlrtLeft_D_Stat 1;
BA_ "U_CD42_MY14_Gas_Tx" SG_ 934 CtaAlrtLeft_D_Stat 1;
BA_ "U_P552_MY15_Gas_Tx" SG_ 934 CtaAlrtLeft_D_Stat 1;
BA_ "U_S550_MY15_Gas_Tx" SG_ 934 CtaAlrtLeft_D_Stat 1;
BA_ "U_C489_MY14_Gas_Tx" SG_ 934 CtaAlrtLeft_D_Stat 1;
BA_ "U_U502_MY15_Gas_Tx" SG_ 934 CtaAlrtLeft_D_Stat 1;
BA_ "U_UP375_MY15_Gas_Tx" SG_ 934 CtaAlrtLeft_D_Stat 1;
BA_ "U_UP375_MY15_Diesel_Tx" SG_ 934 CtaAlrtLeft_D_Stat 1;
BA_ "U_CD43_MY16_Gas_Tx" SG_ 934 CtaAlrtLeft_D_Stat 1;
BA_ "CrossOver_InfoCAN" SG_ 934 SodLeft_D_Stat 1;
BA_ "GenSigStartValue" SG_ 934 SodLeft_D_Stat 2;
BA_ "GenSigSendType" SG_ 934 SodLeft_D_Stat 3;
BA_ "U_CD4_MY13_Diesel_Tx" SG_ 934 SodLeft_D_Stat 1;
BA_ "U_CD4_MY13_Gas_Tx" SG_ 934 SodLeft_D_Stat 1;
BA_ "U_CD4_MY13_Hev_Tx" SG_ 934 SodLeft_D_Stat 1;
BA_ "U_CD4_MY13_Phev_Tx" SG_ 934 SodLeft_D_Stat 1;
BA_ "U_CD42_MY14_Diesel_Tx" SG_ 934 SodLeft_D_Stat 1;
BA_ "U_CD42_MY14_Gas_Tx" SG_ 934 SodLeft_D_Stat 1;
BA_ "U_P552_MY15_Gas_Tx" SG_ 934 SodLeft_D_Stat 1;
BA_ "U_S550_MY15_Gas_Tx" SG_ 934 SodLeft_D_Stat 1;
BA_ "U_C489_MY14_Gas_Tx" SG_ 934 SodLeft_D_Stat 1;
BA_ "U_U502_MY15_Gas_Tx" SG_ 934 SodLeft_D_Stat 1;
BA_ "U_UP375_MY15_Gas_Tx" SG_ 934 SodLeft_D_Stat 1;
BA_ "U_UP375_MY15_Diesel_Tx" SG_ 934 SodLeft_D_Stat 1;
BA_ "U_CD43_MY16_Gas_Tx" SG_ 934 SodLeft_D_Stat 1;
BA_ "CrossOver_InfoCAN" SG_ 934 SodSnsLeft_D_Stat 1;
BA_ "GenSigSendType" SG_ 934 SodSnsLeft_D_Stat 3;
BA_ "U_CD4_MY13_Diesel_Rx" SG_ 934 SodSnsLeft_D_Stat 1;
BA_ "U_CD4_MY13_Gas_Rx" SG_ 934 SodSnsLeft_D_Stat 1;
BA_ "U_CD4_MY13_Hev_Rx" SG_ 934 SodSnsLeft_D_Stat 1;
BA_ "U_CD4_MY13_Phev_Rx" SG_ 934 SodSnsLeft_D_Stat 1;
BA_ "U_CD42_MY14_Diesel_Rx" SG_ 934 SodSnsLeft_D_Stat 1;
BA_ "U_CD42_MY14_Gas_Rx" SG_ 934 SodSnsLeft_D_Stat 1;
BA_ "U_P552_MY15_Gas_Rx" SG_ 934 SodSnsLeft_D_Stat 1;
BA_ "U_S550_MY15_Gas_Rx" SG_ 934 SodSnsLeft_D_Stat 1;
BA_ "U_C489_MY14_Gas_Rx" SG_ 934 SodSnsLeft_D_Stat 1;
BA_ "U_B562LC_MY14_Gas_Rx" SG_ 934 SodSnsLeft_D_Stat 1;
BA_ "U_U502_MY15_Gas_Rx" SG_ 934 SodSnsLeft_D_Stat 1;
BA_ "U_UP375_MY15_Gas_Rx" SG_ 934 SodSnsLeft_D_Stat 1;
BA_ "U_UP375_MY15_Diesel_Rx" SG_ 934 SodSnsLeft_D_Stat 1;
BA_ "U_CD43_MY16_Gas_Rx" SG_ 934 SodSnsLeft_D_Stat 1;
BA_ "U_CD4_MY14_Diesel_Rx" SG_ 934 SodSnsLeft_D_Stat 1;
BA_ "U_CD4_MY14_Gas_Rx" SG_ 934 SodSnsLeft_D_Stat 1;
BA_ "U_CD4_MY14_Hev_Rx" SG_ 934 SodSnsLeft_D_Stat 1;
BA_ "U_CD4_MY14_Phev_Rx" SG_ 934 SodSnsLeft_D_Stat 1;
BA_ "U_CD4_MY13_Diesel_Tx" SG_ 934 SodSnsLeft_D_Stat 1;
BA_ "U_CD4_MY13_Gas_Tx" SG_ 934 SodSnsLeft_D_Stat 1;
BA_ "U_CD4_MY13_Hev_Tx" SG_ 934 SodSnsLeft_D_Stat 1;
BA_ "U_CD4_MY13_Phev_Tx" SG_ 934 SodSnsLeft_D_Stat 1;
BA_ "U_CD42_MY14_Diesel_Tx" SG_ 934 SodSnsLeft_D_Stat 1;
BA_ "U_CD42_MY14_Gas_Tx" SG_ 934 SodSnsLeft_D_Stat 1;
BA_ "U_P552_MY15_Gas_Tx" SG_ 934 SodSnsLeft_D_Stat 1;
BA_ "U_S550_MY15_Gas_Tx" SG_ 934 SodSnsLeft_D_Stat 1;
BA_ "U_C489_MY14_Gas_Tx" SG_ 934 SodSnsLeft_D_Stat 1;
BA_ "U_U502_MY15_Gas_Tx" SG_ 934 SodSnsLeft_D_Stat 1;
BA_ "U_UP375_MY15_Gas_Tx" SG_ 934 SodSnsLeft_D_Stat 1;
BA_ "U_UP375_MY15_Diesel_Tx" SG_ 934 SodSnsLeft_D_Stat 1;
BA_ "U_CD43_MY16_Gas_Tx" SG_ 934 SodSnsLeft_D_Stat 1;
BA_ "CrossOver_InfoCAN" SG_ 934 SodAlrtLeft_D_Stat 1;
BA_ "GenSigSendType" SG_ 934 SodAlrtLeft_D_Stat 3;
BA_ "U_CD4_MY13_Diesel_Rx" SG_ 934 SodAlrtLeft_D_Stat 1;
BA_ "U_CD4_MY13_Gas_Rx" SG_ 934 SodAlrtLeft_D_Stat 1;
BA_ "U_CD4_MY13_Hev_Rx" SG_ 934 SodAlrtLeft_D_Stat 1;
BA_ "U_CD4_MY13_Phev_Rx" SG_ 934 SodAlrtLeft_D_Stat 1;
BA_ "U_CD42_MY14_Diesel_Rx" SG_ 934 SodAlrtLeft_D_Stat 1;
BA_ "U_CD42_MY14_Gas_Rx" SG_ 934 SodAlrtLeft_D_Stat 1;
BA_ "U_P552_MY15_Gas_Rx" SG_ 934 SodAlrtLeft_D_Stat 1;
BA_ "U_S550_MY15_Gas_Rx" SG_ 934 SodAlrtLeft_D_Stat 1;
BA_ "U_C489_MY14_Gas_Rx" SG_ 934 SodAlrtLeft_D_Stat 1;
BA_ "U_U502_MY15_Gas_Rx" SG_ 934 SodAlrtLeft_D_Stat 1;
BA_ "U_UP375_MY15_Gas_Rx" SG_ 934 SodAlrtLeft_D_Stat 1;
BA_ "U_UP375_MY15_Diesel_Rx" SG_ 934 SodAlrtLeft_D_Stat 1;
BA_ "U_CD43_MY16_Gas_Rx" SG_ 934 SodAlrtLeft_D_Stat 1;
BA_ "U_CD4_MY14_Diesel_Rx" SG_ 934 SodAlrtLeft_D_Stat 1;
BA_ "U_CD4_MY14_Gas_Rx" SG_ 934 SodAlrtLeft_D_Stat 1;
BA_ "U_CD4_MY14_Hev_Rx" SG_ 934 SodAlrtLeft_D_Stat 1;
BA_ "U_CD4_MY14_Phev_Rx" SG_ 934 SodAlrtLeft_D_Stat 1;
BA_ "U_CD4_MY13_Diesel_Tx" SG_ 934 SodAlrtLeft_D_Stat 1;
BA_ "U_CD4_MY13_Gas_Tx" SG_ 934 SodAlrtLeft_D_Stat 1;
BA_ "U_CD4_MY13_Hev_Tx" SG_ 934 SodAlrtLeft_D_Stat 1;
BA_ "U_CD4_MY13_Phev_Tx" SG_ 934 SodAlrtLeft_D_Stat 1;
BA_ "U_CD42_MY14_Diesel_Tx" SG_ 934 SodAlrtLeft_D_Stat 1;
BA_ "U_CD42_MY14_Gas_Tx" SG_ 934 SodAlrtLeft_D_Stat 1;
BA_ "U_P552_MY15_Gas_Tx" SG_ 934 SodAlrtLeft_D_Stat 1;
BA_ "U_S550_MY15_Gas_Tx" SG_ 934 SodAlrtLeft_D_Stat 1;
BA_ "U_C489_MY14_Gas_Tx" SG_ 934 SodAlrtLeft_D_Stat 1;
BA_ "U_U502_MY15_Gas_Tx" SG_ 934 SodAlrtLeft_D_Stat 1;
BA_ "U_UP375_MY15_Gas_Tx" SG_ 934 SodAlrtLeft_D_Stat 1;
BA_ "U_UP375_MY15_Diesel_Tx" SG_ 934 SodAlrtLeft_D_Stat 1;
BA_ "U_CD43_MY16_Gas_Tx" SG_ 934 SodAlrtLeft_D_Stat 1;
BA_ "CrossOver_InfoCAN" SG_ 934 SodWarnLeft_Prd_Rq 1;
BA_ "GenSigStartValue" SG_ 934 SodWarnLeft_Prd_Rq 14;
BA_ "GenSigSendType" SG_ 934 SodWarnLeft_Prd_Rq 3;
BA_ "U_CD4_MY13_Diesel_Rx" SG_ 934 SodWarnLeft_Prd_Rq 1;
BA_ "U_CD4_MY13_Gas_Rx" SG_ 934 SodWarnLeft_Prd_Rq 1;
BA_ "U_CD4_MY13_Hev_Rx" SG_ 934 SodWarnLeft_Prd_Rq 1;
BA_ "U_CD4_MY13_Phev_Rx" SG_ 934 SodWarnLeft_Prd_Rq 1;
BA_ "U_CD42_MY14_Diesel_Rx" SG_ 934 SodWarnLeft_Prd_Rq 1;
BA_ "U_CD42_MY14_Gas_Rx" SG_ 934 SodWarnLeft_Prd_Rq 1;
BA_ "U_P552_MY15_Gas_Rx" SG_ 934 SodWarnLeft_Prd_Rq 1;
BA_ "U_S550_MY15_Gas_Rx" SG_ 934 SodWarnLeft_Prd_Rq 1;
BA_ "U_C489_MY14_Gas_Rx" SG_ 934 SodWarnLeft_Prd_Rq 1;
BA_ "U_U502_MY15_Gas_Rx" SG_ 934 SodWarnLeft_Prd_Rq 1;
BA_ "U_UP375_MY15_Gas_Rx" SG_ 934 SodWarnLeft_Prd_Rq 1;
BA_ "U_UP375_MY15_Diesel_Rx" SG_ 934 SodWarnLeft_Prd_Rq 1;
BA_ "U_CD43_MY16_Gas_Rx" SG_ 934 SodWarnLeft_Prd_Rq 1;
BA_ "U_CD4_MY14_Diesel_Rx" SG_ 934 SodWarnLeft_Prd_Rq 1;
BA_ "U_CD4_MY14_Gas_Rx" SG_ 934 SodWarnLeft_Prd_Rq 1;
BA_ "U_CD4_MY14_Hev_Rx" SG_ 934 SodWarnLeft_Prd_Rq 1;
BA_ "U_CD4_MY14_Phev_Rx" SG_ 934 SodWarnLeft_Prd_Rq 1;
BA_ "U_CD4_MY13_Diesel_Tx" SG_ 934 SodWarnLeft_Prd_Rq 1;
BA_ "U_CD4_MY13_Gas_Tx" SG_ 934 SodWarnLeft_Prd_Rq 1;
BA_ "U_CD4_MY13_Hev_Tx" SG_ 934 SodWarnLeft_Prd_Rq 1;
BA_ "U_CD4_MY13_Phev_Tx" SG_ 934 SodWarnLeft_Prd_Rq 1;
BA_ "U_CD42_MY14_Diesel_Tx" SG_ 934 SodWarnLeft_Prd_Rq 1;
BA_ "U_CD42_MY14_Gas_Tx" SG_ 934 SodWarnLeft_Prd_Rq 1;
BA_ "U_P552_MY15_Gas_Tx" SG_ 934 SodWarnLeft_Prd_Rq 1;
BA_ "U_S550_MY15_Gas_Tx" SG_ 934 SodWarnLeft_Prd_Rq 1;
BA_ "U_C489_MY14_Gas_Tx" SG_ 934 SodWarnLeft_Prd_Rq 1;
BA_ "U_U502_MY15_Gas_Tx" SG_ 934 SodWarnLeft_Prd_Rq 1;
BA_ "U_UP375_MY15_Gas_Tx" SG_ 934 SodWarnLeft_Prd_Rq 1;
BA_ "U_UP375_MY15_Diesel_Tx" SG_ 934 SodWarnLeft_Prd_Rq 1;
BA_ "U_CD43_MY16_Gas_Tx" SG_ 934 SodWarnLeft_Prd_Rq 1;
BA_ "CrossOver_InfoCAN" SG_ 934 SodInnrLeft_D_Stat 1;
BA_ "GenSigSendType" SG_ 934 SodInnrLeft_D_Stat 3;
BA_ "U_CD4_MY13_Diesel_Rx" SG_ 934 SodInnrLeft_D_Stat 1;
BA_ "U_CD4_MY13_Gas_Rx" SG_ 934 SodInnrLeft_D_Stat 1;
BA_ "U_CD4_MY13_Hev_Rx" SG_ 934 SodInnrLeft_D_Stat 1;
BA_ "U_CD4_MY13_Phev_Rx" SG_ 934 SodInnrLeft_D_Stat 1;
BA_ "U_CD42_MY14_Diesel_Rx" SG_ 934 SodInnrLeft_D_Stat 1;
BA_ "U_CD42_MY14_Gas_Rx" SG_ 934 SodInnrLeft_D_Stat 1;
BA_ "U_P552_MY15_Gas_Rx" SG_ 934 SodInnrLeft_D_Stat 1;
BA_ "U_S550_MY15_Gas_Rx" SG_ 934 SodInnrLeft_D_Stat 1;
BA_ "U_C489_MY14_Gas_Rx" SG_ 934 SodInnrLeft_D_Stat 1;
BA_ "U_B562LC_MY14_Gas_Rx" SG_ 934 SodInnrLeft_D_Stat 1;
BA_ "U_U502_MY15_Gas_Rx" SG_ 934 SodInnrLeft_D_Stat 1;
BA_ "U_UP375_MY15_Gas_Rx" SG_ 934 SodInnrLeft_D_Stat 1;
BA_ "U_UP375_MY15_Diesel_Rx" SG_ 934 SodInnrLeft_D_Stat 1;
BA_ "U_CD43_MY16_Gas_Rx" SG_ 934 SodInnrLeft_D_Stat 1;
BA_ "U_CD4_MY13_Diesel_Tx" SG_ 934 SodInnrLeft_D_Stat 1;
BA_ "U_CD4_MY13_Gas_Tx" SG_ 934 SodInnrLeft_D_Stat 1;
BA_ "U_CD4_MY13_Hev_Tx" SG_ 934 SodInnrLeft_D_Stat 1;
BA_ "U_CD4_MY13_Phev_Tx" SG_ 934 SodInnrLeft_D_Stat 1;
BA_ "U_CD42_MY14_Diesel_Tx" SG_ 934 SodInnrLeft_D_Stat 1;
BA_ "U_CD42_MY14_Gas_Tx" SG_ 934 SodInnrLeft_D_Stat 1;
BA_ "U_P552_MY15_Gas_Tx" SG_ 934 SodInnrLeft_D_Stat 1;
BA_ "U_S550_MY15_Gas_Tx" SG_ 934 SodInnrLeft_D_Stat 1;
BA_ "U_C489_MY14_Gas_Tx" SG_ 934 SodInnrLeft_D_Stat 1;
BA_ "U_U502_MY15_Gas_Tx" SG_ 934 SodInnrLeft_D_Stat 1;
BA_ "U_UP375_MY15_Gas_Tx" SG_ 934 SodInnrLeft_D_Stat 1;
BA_ "U_UP375_MY15_Diesel_Tx" SG_ 934 SodInnrLeft_D_Stat 1;
BA_ "U_CD43_MY16_Gas_Tx" SG_ 934 SodInnrLeft_D_Stat 1;
BA_ "GenSigSendType" SG_ 969 Dimming_Level_Stat 3;
BA_ "GenSigStartValue" SG_ 969 Current_Color_Stat 8;
BA_ "GenSigSendType" SG_ 969 Current_Color_Stat 3;
BA_ "GenSigSendType" SG_ 969 BlendedColorRed_Stat 3;
BA_ "GenSigSendType" SG_ 969 BlendedColorGreen_Stat 3;
BA_ "GenSigSendType" SG_ 969 BlendedColorBlue_Stat 3;
BA_ "GenSigStartValue" SG_ 969 BlendedColor_Stat 2;
BA_ "GenSigSendType" SG_ 969 BlendedColor_Stat 3;
BA_ "WakeupSignal" SG_ 969 TurnLampRrOut_B_Stat 1;
BA_ "ContentDependant" SG_ 969 TurnLampRrOut_B_Stat 1;
BA_ "GenSigSendType" SG_ 969 TurnLampRrOut_B_Stat 3;
BA_ "U_CD4_MY13_Diesel_Rx" SG_ 969 TurnLampRrOut_B_Stat 1;
BA_ "U_CD4_MY13_Gas_Rx" SG_ 969 TurnLampRrOut_B_Stat 1;
BA_ "U_CD4_MY13_Hev_Rx" SG_ 969 TurnLampRrOut_B_Stat 1;
BA_ "U_CD4_MY13_Phev_Rx" SG_ 969 TurnLampRrOut_B_Stat 1;
BA_ "U_CD42_MY14_Diesel_Rx" SG_ 969 TurnLampRrOut_B_Stat 1;
BA_ "U_CD42_MY14_Gas_Rx" SG_ 969 TurnLampRrOut_B_Stat 1;
BA_ "U_P552_MY15_Gas_Rx" SG_ 969 TurnLampRrOut_B_Stat 1;
BA_ "U_S550_MY15_Gas_Rx" SG_ 969 TurnLampRrOut_B_Stat 1;
BA_ "U_C489_MY14_Gas_Rx" SG_ 969 TurnLampRrOut_B_Stat 1;
BA_ "U_U502_MY15_Gas_Rx" SG_ 969 TurnLampRrOut_B_Stat 1;
BA_ "U_B479_MY15_Gas_Rx" SG_ 969 TurnLampRrOut_B_Stat 1;
BA_ "U_UP375_MY15_Gas_Rx" SG_ 969 TurnLampRrOut_B_Stat 1;
BA_ "U_UP375_MY15_Diesel_Rx" SG_ 969 TurnLampRrOut_B_Stat 1;
BA_ "WakeupSignal" SG_ 969 TurnLampRlOut_B_Stat 1;
BA_ "ContentDependant" SG_ 969 TurnLampRlOut_B_Stat 1;
BA_ "GenSigSendType" SG_ 969 TurnLampRlOut_B_Stat 3;
BA_ "U_CD4_MY13_Diesel_Rx" SG_ 969 TurnLampRlOut_B_Stat 1;
BA_ "U_CD4_MY13_Gas_Rx" SG_ 969 TurnLampRlOut_B_Stat 1;
BA_ "U_CD4_MY13_Hev_Rx" SG_ 969 TurnLampRlOut_B_Stat 1;
BA_ "U_CD4_MY13_Phev_Rx" SG_ 969 TurnLampRlOut_B_Stat 1;
BA_ "U_CD42_MY14_Diesel_Rx" SG_ 969 TurnLampRlOut_B_Stat 1;
BA_ "U_CD42_MY14_Gas_Rx" SG_ 969 TurnLampRlOut_B_Stat 1;
BA_ "U_P552_MY15_Gas_Rx" SG_ 969 TurnLampRlOut_B_Stat 1;
BA_ "U_S550_MY15_Gas_Rx" SG_ 969 TurnLampRlOut_B_Stat 1;
BA_ "U_C489_MY14_Gas_Rx" SG_ 969 TurnLampRlOut_B_Stat 1;
BA_ "U_U502_MY15_Gas_Rx" SG_ 969 TurnLampRlOut_B_Stat 1;
BA_ "U_B479_MY15_Gas_Rx" SG_ 969 TurnLampRlOut_B_Stat 1;
BA_ "U_UP375_MY15_Gas_Rx" SG_ 969 TurnLampRlOut_B_Stat 1;
BA_ "U_UP375_MY15_Diesel_Rx" SG_ 969 TurnLampRlOut_B_Stat 1;
BA_ "U_CD4_MY13_Diesel_Rx" SG_ 1070 StopStrtStdby_D_Indic_UB 1;
BA_ "U_CD4_MY13_Gas_Rx" SG_ 1070 StopStrtStdby_D_Indic_UB 1;
BA_ "U_CD4_MY13_Hev_Rx" SG_ 1070 StopStrtStdby_D_Indic_UB 1;
BA_ "U_CD4_MY13_Phev_Rx" SG_ 1070 StopStrtStdby_D_Indic_UB 1;
BA_ "U_CD42_MY14_Diesel_Rx" SG_ 1070 StopStrtStdby_D_Indic_UB 1;
BA_ "U_CD42_MY14_Gas_Rx" SG_ 1070 StopStrtStdby_D_Indic_UB 1;
BA_ "U_P552_MY15_Gas_Rx" SG_ 1070 StopStrtStdby_D_Indic_UB 1;
BA_ "U_U502_MY15_Gas_Rx" SG_ 1070 StopStrtStdby_D_Indic_UB 1;
BA_ "U_UP375_MY15_Gas_Rx" SG_ 1070 StopStrtStdby_D_Indic_UB 1;
BA_ "U_UP375_MY15_Diesel_Rx" SG_ 1070 StopStrtStdby_D_Indic_UB 1;
BA_ "U_CD43_MY16_Gas_Rx" SG_ 1070 StopStrtStdby_D_Indic_UB 1;
BA_ "U_CD4_MY13_Diesel_Rx" SG_ 1070 PassRstrnInd_Req_UB 1;
BA_ "U_CD4_MY13_Gas_Rx" SG_ 1070 PassRstrnInd_Req_UB 1;
BA_ "U_CD4_MY13_Hev_Rx" SG_ 1070 PassRstrnInd_Req_UB 1;
BA_ "U_CD4_MY13_Phev_Rx" SG_ 1070 PassRstrnInd_Req_UB 1;
BA_ "U_CD42_MY14_Diesel_Rx" SG_ 1070 PassRstrnInd_Req_UB 1;
BA_ "U_CD42_MY14_Gas_Rx" SG_ 1070 PassRstrnInd_Req_UB 1;
BA_ "U_P552_MY15_Gas_Rx" SG_ 1070 PassRstrnInd_Req_UB 1;
BA_ "U_S550_MY15_Gas_Rx" SG_ 1070 PassRstrnInd_Req_UB 1;
BA_ "U_C489_MY14_Gas_Rx" SG_ 1070 PassRstrnInd_Req_UB 1;
BA_ "U_U502_MY15_Gas_Rx" SG_ 1070 PassRstrnInd_Req_UB 1;
BA_ "U_UP375_MY15_Gas_Rx" SG_ 1070 PassRstrnInd_Req_UB 1;
BA_ "U_UP375_MY15_Diesel_Rx" SG_ 1070 PassRstrnInd_Req_UB 1;
BA_ "U_CD43_MY16_Gas_Rx" SG_ 1070 PassRstrnInd_Req_UB 1;
BA_ "U_CD4_MY13_Diesel_Rx" SG_ 1070 HiElPwInhbt_B_Stat_UB 1;
BA_ "U_CD4_MY13_Gas_Rx" SG_ 1070 HiElPwInhbt_B_Stat_UB 1;
BA_ "U_CD4_MY13_Hev_Rx" SG_ 1070 HiElPwInhbt_B_Stat_UB 1;
BA_ "U_CD4_MY13_Phev_Rx" SG_ 1070 HiElPwInhbt_B_Stat_UB 1;
BA_ "U_CD42_MY14_Diesel_Rx" SG_ 1070 HiElPwInhbt_B_Stat_UB 1;
BA_ "U_CD42_MY14_Gas_Rx" SG_ 1070 HiElPwInhbt_B_Stat_UB 1;
BA_ "U_P552_MY15_Gas_Rx" SG_ 1070 HiElPwInhbt_B_Stat_UB 1;
BA_ "U_U502_MY15_Gas_Rx" SG_ 1070 HiElPwInhbt_B_Stat_UB 1;
BA_ "U_UP375_MY15_Gas_Rx" SG_ 1070 HiElPwInhbt_B_Stat_UB 1;
BA_ "U_UP375_MY15_Diesel_Rx" SG_ 1070 HiElPwInhbt_B_Stat_UB 1;
BA_ "U_CD43_MY16_Gas_Rx" SG_ 1070 HiElPwInhbt_B_Stat_UB 1;
BA_ "U_CD4_MY14_Diesel_Rx" SG_ 1070 HiElPwInhbt_B_Stat_UB 1;
BA_ "U_CD4_MY14_Gas_Rx" SG_ 1070 HiElPwInhbt_B_Stat_UB 1;
BA_ "U_CD4_MY14_Hev_Rx" SG_ 1070 HiElPwInhbt_B_Stat_UB 1;
BA_ "U_CD4_MY14_Phev_Rx" SG_ 1070 HiElPwInhbt_B_Stat_UB 1;
BA_ "CrossOver_InfoCAN" SG_ 1070 HiElPwInhbt_B_Stat 1;
BA_ "ContentDependant" SG_ 1070 HiElPwInhbt_B_Stat 1;
BA_ "U_CD4_MY13_Diesel_Rx" SG_ 1070 HiElPwInhbt_B_Stat 1;
BA_ "U_CD4_MY13_Gas_Rx" SG_ 1070 HiElPwInhbt_B_Stat 1;
BA_ "U_CD4_MY13_Hev_Rx" SG_ 1070 HiElPwInhbt_B_Stat 1;
BA_ "U_CD4_MY13_Phev_Rx" SG_ 1070 HiElPwInhbt_B_Stat 1;
BA_ "U_CD42_MY14_Diesel_Rx" SG_ 1070 HiElPwInhbt_B_Stat 1;
BA_ "U_CD42_MY14_Gas_Rx" SG_ 1070 HiElPwInhbt_B_Stat 1;
BA_ "U_P552_MY15_Gas_Rx" SG_ 1070 HiElPwInhbt_B_Stat 1;
BA_ "U_U502_MY15_Gas_Rx" SG_ 1070 HiElPwInhbt_B_Stat 1;
BA_ "U_UP375_MY15_Gas_Rx" SG_ 1070 HiElPwInhbt_B_Stat 1;
BA_ "U_UP375_MY15_Diesel_Rx" SG_ 1070 HiElPwInhbt_B_Stat 1;
BA_ "U_CD43_MY16_Gas_Rx" SG_ 1070 HiElPwInhbt_B_Stat 1;
BA_ "U_CD4_MY14_Diesel_Rx" SG_ 1070 HiElPwInhbt_B_Stat 1;
BA_ "U_CD4_MY14_Gas_Rx" SG_ 1070 HiElPwInhbt_B_Stat 1;
BA_ "U_CD4_MY14_Hev_Rx" SG_ 1070 HiElPwInhbt_B_Stat 1;
BA_ "U_CD4_MY14_Phev_Rx" SG_ 1070 HiElPwInhbt_B_Stat 1;
BA_ "CrossOver_InfoCAN" SG_ 1070 StopStrtStdby_D_Indic 1;
BA_ "GenSigStartValue" SG_ 1070 StopStrtStdby_D_Indic 5;
BA_ "U_CD4_MY13_Diesel_Rx" SG_ 1070 StopStrtStdby_D_Indic 1;
BA_ "U_CD4_MY13_Gas_Rx" SG_ 1070 StopStrtStdby_D_Indic 1;
BA_ "U_CD4_MY13_Hev_Rx" SG_ 1070 StopStrtStdby_D_Indic 1;
BA_ "U_CD4_MY13_Phev_Rx" SG_ 1070 StopStrtStdby_D_Indic 1;
BA_ "U_CD42_MY14_Diesel_Rx" SG_ 1070 StopStrtStdby_D_Indic 1;
BA_ "U_CD42_MY14_Gas_Rx" SG_ 1070 StopStrtStdby_D_Indic 1;
BA_ "U_P552_MY15_Gas_Rx" SG_ 1070 StopStrtStdby_D_Indic 1;
BA_ "U_U502_MY15_Gas_Rx" SG_ 1070 StopStrtStdby_D_Indic 1;
BA_ "U_UP375_MY15_Gas_Rx" SG_ 1070 StopStrtStdby_D_Indic 1;
BA_ "U_UP375_MY15_Diesel_Rx" SG_ 1070 StopStrtStdby_D_Indic 1;
BA_ "U_CD43_MY16_Gas_Rx" SG_ 1070 StopStrtStdby_D_Indic 1;
BA_ "U_CD4_MY13_Diesel_Rx" SG_ 1070 CoolantFanStepAct_UB 1;
BA_ "U_CD4_MY13_Gas_Rx" SG_ 1070 CoolantFanStepAct_UB 1;
BA_ "U_CD4_MY13_Hev_Rx" SG_ 1070 CoolantFanStepAct_UB 1;
BA_ "U_CD4_MY13_Phev_Rx" SG_ 1070 CoolantFanStepAct_UB 1;
BA_ "U_CD42_MY14_Diesel_Rx" SG_ 1070 CoolantFanStepAct_UB 1;
BA_ "U_CD42_MY14_Gas_Rx" SG_ 1070 CoolantFanStepAct_UB 1;
BA_ "U_P552_MY15_Gas_Rx" SG_ 1070 CoolantFanStepAct_UB 1;
BA_ "U_S550_MY15_Gas_Rx" SG_ 1070 CoolantFanStepAct_UB 1;
BA_ "U_C489_MY14_Gas_Rx" SG_ 1070 CoolantFanStepAct_UB 1;
BA_ "U_U502_MY15_Gas_Rx" SG_ 1070 CoolantFanStepAct_UB 1;
BA_ "U_UP375_MY15_Gas_Rx" SG_ 1070 CoolantFanStepAct_UB 1;
BA_ "U_UP375_MY15_Diesel_Rx" SG_ 1070 CoolantFanStepAct_UB 1;
BA_ "U_CD43_MY16_Gas_Rx" SG_ 1070 CoolantFanStepAct_UB 1;
BA_ "CrossOver_InfoCAN" SG_ 1070 CoolantFanStepAct 1;
BA_ "U_CD4_MY13_Diesel_Rx" SG_ 1070 CoolantFanStepAct 1;
BA_ "U_CD4_MY13_Gas_Rx" SG_ 1070 CoolantFanStepAct 1;
BA_ "U_CD4_MY13_Hev_Rx" SG_ 1070 CoolantFanStepAct 1;
BA_ "U_CD4_MY13_Phev_Rx" SG_ 1070 CoolantFanStepAct 1;
BA_ "U_CD42_MY14_Diesel_Rx" SG_ 1070 CoolantFanStepAct 1;
BA_ "U_CD42_MY14_Gas_Rx" SG_ 1070 CoolantFanStepAct 1;
BA_ "U_P552_MY15_Gas_Rx" SG_ 1070 CoolantFanStepAct 1;
BA_ "U_S550_MY15_Gas_Rx" SG_ 1070 CoolantFanStepAct 1;
BA_ "U_C489_MY14_Gas_Rx" SG_ 1070 CoolantFanStepAct 1;
BA_ "U_U502_MY15_Gas_Rx" SG_ 1070 CoolantFanStepAct 1;
BA_ "U_UP375_MY15_Gas_Rx" SG_ 1070 CoolantFanStepAct 1;
BA_ "U_UP375_MY15_Diesel_Rx" SG_ 1070 CoolantFanStepAct 1;
BA_ "U_CD43_MY16_Gas_Rx" SG_ 1070 CoolantFanStepAct 1;
BA_ "GenSigStartValue" SG_ 1070 VehVActlEng_D_Qf_UB 1;
BA_ "U_P552_MY15_Gas_Rx" SG_ 1070 VehVActlEng_D_Qf_UB 1;
BA_ "U_S550_MY15_Gas_Rx" SG_ 1070 VehVActlEng_D_Qf_UB 1;
BA_ "U_C489_MY14_Gas_Rx" SG_ 1070 VehVActlEng_D_Qf_UB 1;
BA_ "U_CD43_MY16_Gas_Rx" SG_ 1070 VehVActlEng_D_Qf_UB 1;
BA_ "U_CD4_MY13_Diesel_Rx" SG_ 1070 RstrnImpactEvntStatus_UB 1;
BA_ "U_CD4_MY13_Gas_Rx" SG_ 1070 RstrnImpactEvntStatus_UB 1;
BA_ "U_CD4_MY13_Hev_Rx" SG_ 1070 RstrnImpactEvntStatus_UB 1;
BA_ "U_CD4_MY13_Phev_Rx" SG_ 1070 RstrnImpactEvntStatus_UB 1;
BA_ "U_CD42_MY14_Diesel_Rx" SG_ 1070 RstrnImpactEvntStatus_UB 1;
BA_ "U_CD42_MY14_Gas_Rx" SG_ 1070 RstrnImpactEvntStatus_UB 1;
BA_ "U_P552_MY15_Gas_Rx" SG_ 1070 RstrnImpactEvntStatus_UB 1;
BA_ "U_S550_MY15_Gas_Rx" SG_ 1070 RstrnImpactEvntStatus_UB 1;
BA_ "U_C489_MY14_Gas_Rx" SG_ 1070 RstrnImpactEvntStatus_UB 1;
BA_ "U_U502_MY15_Gas_Rx" SG_ 1070 RstrnImpactEvntStatus_UB 1;
BA_ "U_UP375_MY15_Gas_Rx" SG_ 1070 RstrnImpactEvntStatus_UB 1;
BA_ "U_UP375_MY15_Diesel_Rx" SG_ 1070 RstrnImpactEvntStatus_UB 1;
BA_ "U_CD43_MY16_Gas_Rx" SG_ 1070 RstrnImpactEvntStatus_UB 1;
BA_ "U_CD4_MY13_Diesel_Rx" SG_ 1070 EngAirIn_Te_Actl_UB 1;
BA_ "U_CD4_MY13_Gas_Rx" SG_ 1070 EngAirIn_Te_Actl_UB 1;
BA_ "U_CD4_MY13_Hev_Rx" SG_ 1070 EngAirIn_Te_Actl_UB 1;
BA_ "U_CD4_MY13_Phev_Rx" SG_ 1070 EngAirIn_Te_Actl_UB 1;
BA_ "U_CD42_MY14_Diesel_Rx" SG_ 1070 EngAirIn_Te_Actl_UB 1;
BA_ "U_CD42_MY14_Gas_Rx" SG_ 1070 EngAirIn_Te_Actl_UB 1;
BA_ "U_P552_MY15_Gas_Rx" SG_ 1070 EngAirIn_Te_Actl_UB 1;
BA_ "U_S550_MY15_Gas_Rx" SG_ 1070 EngAirIn_Te_Actl_UB 1;
BA_ "U_C489_MY14_Gas_Rx" SG_ 1070 EngAirIn_Te_Actl_UB 1;
BA_ "U_U502_MY15_Gas_Rx" SG_ 1070 EngAirIn_Te_Actl_UB 1;
BA_ "U_UP375_MY15_Gas_Rx" SG_ 1070 EngAirIn_Te_Actl_UB 1;
BA_ "U_UP375_MY15_Diesel_Rx" SG_ 1070 EngAirIn_Te_Actl_UB 1;
BA_ "U_CD43_MY16_Gas_Rx" SG_ 1070 EngAirIn_Te_Actl_UB 1;
BA_ "WakeupSignal" SG_ 1070 RstrnImpactEvntStatus 1;
BA_ "CrossOver_InfoCAN" SG_ 1070 RstrnImpactEvntStatus 1;
BA_ "U_CD4_MY13_Diesel_Rx" SG_ 1070 RstrnImpactEvntStatus 1;
BA_ "U_CD4_MY13_Gas_Rx" SG_ 1070 RstrnImpactEvntStatus 1;
BA_ "U_CD4_MY13_Hev_Rx" SG_ 1070 RstrnImpactEvntStatus 1;
BA_ "U_CD4_MY13_Phev_Rx" SG_ 1070 RstrnImpactEvntStatus 1;
BA_ "U_CD42_MY14_Diesel_Rx" SG_ 1070 RstrnImpactEvntStatus 1;
BA_ "U_CD42_MY14_Gas_Rx" SG_ 1070 RstrnImpactEvntStatus 1;
BA_ "U_P552_MY15_Gas_Rx" SG_ 1070 RstrnImpactEvntStatus 1;
BA_ "U_S550_MY15_Gas_Rx" SG_ 1070 RstrnImpactEvntStatus 1;
BA_ "U_C489_MY14_Gas_Rx" SG_ 1070 RstrnImpactEvntStatus 1;
BA_ "U_U502_MY15_Gas_Rx" SG_ 1070 RstrnImpactEvntStatus 1;
BA_ "U_UP375_MY15_Gas_Rx" SG_ 1070 RstrnImpactEvntStatus 1;
BA_ "U_UP375_MY15_Diesel_Rx" SG_ 1070 RstrnImpactEvntStatus 1;
BA_ "U_CD43_MY16_Gas_Rx" SG_ 1070 RstrnImpactEvntStatus 1;
BA_ "CrossOver_InfoCAN" SG_ 1070 EngAirIn_Te_Actl 1;
BA_ "U_CD4_MY13_Diesel_Rx" SG_ 1070 EngAirIn_Te_Actl 1;
BA_ "U_CD4_MY13_Gas_Rx" SG_ 1070 EngAirIn_Te_Actl 1;
BA_ "U_CD4_MY13_Hev_Rx" SG_ 1070 EngAirIn_Te_Actl 1;
BA_ "U_CD4_MY13_Phev_Rx" SG_ 1070 EngAirIn_Te_Actl 1;
BA_ "U_CD42_MY14_Diesel_Rx" SG_ 1070 EngAirIn_Te_Actl 1;
BA_ "U_CD42_MY14_Gas_Rx" SG_ 1070 EngAirIn_Te_Actl 1;
BA_ "U_P552_MY15_Gas_Rx" SG_ 1070 EngAirIn_Te_Actl 1;
BA_ "U_S550_MY15_Gas_Rx" SG_ 1070 EngAirIn_Te_Actl 1;
BA_ "U_C489_MY14_Gas_Rx" SG_ 1070 EngAirIn_Te_Actl 1;
BA_ "U_U502_MY15_Gas_Rx" SG_ 1070 EngAirIn_Te_Actl 1;
BA_ "U_UP375_MY15_Gas_Rx" SG_ 1070 EngAirIn_Te_Actl 1;
BA_ "U_UP375_MY15_Diesel_Rx" SG_ 1070 EngAirIn_Te_Actl 1;
BA_ "U_CD43_MY16_Gas_Rx" SG_ 1070 EngAirIn_Te_Actl 1;
BA_ "U_CD4_MY13_Diesel_Rx" SG_ 1070 EngAout_N_Actl_UB 1;
BA_ "U_CD4_MY13_Gas_Rx" SG_ 1070 EngAout_N_Actl_UB 1;
BA_ "U_CD4_MY13_Hev_Rx" SG_ 1070 EngAout_N_Actl_UB 1;
BA_ "U_CD4_MY13_Phev_Rx" SG_ 1070 EngAout_N_Actl_UB 1;
BA_ "U_CD42_MY14_Diesel_Rx" SG_ 1070 EngAout_N_Actl_UB 1;
BA_ "U_CD42_MY14_Gas_Rx" SG_ 1070 EngAout_N_Actl_UB 1;
BA_ "U_P552_MY15_Gas_Rx" SG_ 1070 EngAout_N_Actl_UB 1;
BA_ "U_S550_MY15_Gas_Rx" SG_ 1070 EngAout_N_Actl_UB 1;
BA_ "U_C489_MY14_Gas_Rx" SG_ 1070 EngAout_N_Actl_UB 1;
BA_ "U_U502_MY15_Gas_Rx" SG_ 1070 EngAout_N_Actl_UB 1;
BA_ "U_UP375_MY15_Gas_Rx" SG_ 1070 EngAout_N_Actl_UB 1;
BA_ "U_UP375_MY15_Diesel_Rx" SG_ 1070 EngAout_N_Actl_UB 1;
BA_ "U_CD43_MY16_Gas_Rx" SG_ 1070 EngAout_N_Actl_UB 1;
BA_ "CrossOver_InfoCAN" SG_ 1070 EngAout_N_Actl 1;
BA_ "U_CD4_MY13_Diesel_Rx" SG_ 1070 EngAout_N_Actl 1;
BA_ "U_CD4_MY13_Gas_Rx" SG_ 1070 EngAout_N_Actl 1;
BA_ "U_CD4_MY13_Hev_Rx" SG_ 1070 EngAout_N_Actl 1;
BA_ "U_CD4_MY13_Phev_Rx" SG_ 1070 EngAout_N_Actl 1;
BA_ "U_CD42_MY14_Diesel_Rx" SG_ 1070 EngAout_N_Actl 1;
BA_ "U_CD42_MY14_Gas_Rx" SG_ 1070 EngAout_N_Actl 1;
BA_ "U_P552_MY15_Gas_Rx" SG_ 1070 EngAout_N_Actl 1;
BA_ "U_S550_MY15_Gas_Rx" SG_ 1070 EngAout_N_Actl 1;
BA_ "U_C489_MY14_Gas_Rx" SG_ 1070 EngAout_N_Actl 1;
BA_ "U_U502_MY15_Gas_Rx" SG_ 1070 EngAout_N_Actl 1;
BA_ "U_UP375_MY15_Gas_Rx" SG_ 1070 EngAout_N_Actl 1;
BA_ "U_UP375_MY15_Diesel_Rx" SG_ 1070 EngAout_N_Actl 1;
BA_ "U_CD43_MY16_Gas_Rx" SG_ 1070 EngAout_N_Actl 1;
BA_ "CrossOver_InfoCAN" SG_ 1070 VehVActlEng_D_Qf 1;
BA_ "U_CD4_MY13_Diesel_Rx" SG_ 1070 VehVActlEng_D_Qf 1;
BA_ "U_CD4_MY13_Gas_Rx" SG_ 1070 VehVActlEng_D_Qf 1;
BA_ "U_CD4_MY13_Hev_Rx" SG_ 1070 VehVActlEng_D_Qf 1;
BA_ "U_CD4_MY13_Phev_Rx" SG_ 1070 VehVActlEng_D_Qf 1;
BA_ "U_CD42_MY14_Diesel_Rx" SG_ 1070 VehVActlEng_D_Qf 1;
BA_ "U_CD42_MY14_Gas_Rx" SG_ 1070 VehVActlEng_D_Qf 1;
BA_ "U_P552_MY15_Gas_Rx" SG_ 1070 VehVActlEng_D_Qf 1;
BA_ "U_S550_MY15_Gas_Rx" SG_ 1070 VehVActlEng_D_Qf 1;
BA_ "U_C489_MY14_Gas_Rx" SG_ 1070 VehVActlEng_D_Qf 1;
BA_ "U_U502_MY15_Gas_Rx" SG_ 1070 VehVActlEng_D_Qf 1;
BA_ "U_UP375_MY15_Gas_Rx" SG_ 1070 VehVActlEng_D_Qf 1;
BA_ "U_UP375_MY15_Diesel_Rx" SG_ 1070 VehVActlEng_D_Qf 1;
BA_ "U_CD43_MY16_Gas_Rx" SG_ 1070 VehVActlEng_D_Qf 1;
BA_ "U_B562LC_MY14_Gas_Rx" SG_ 1070 VehVActlEng_D_Qf 1;
BA_ "U_CD4_MY14_Diesel_Rx" SG_ 1070 VehVActlEng_D_Qf 1;
BA_ "U_CD4_MY14_Gas_Rx" SG_ 1070 VehVActlEng_D_Qf 1;
BA_ "U_CD4_MY14_Hev_Rx" SG_ 1070 VehVActlEng_D_Qf 1;
BA_ "U_CD4_MY14_Phev_Rx" SG_ 1070 VehVActlEng_D_Qf 1;
BA_ "U_CD4_MY13_Diesel_Rx" SG_ 1070 Veh_V_ActlEng_UB 1;
BA_ "U_CD4_MY13_Gas_Rx" SG_ 1070 Veh_V_ActlEng_UB 1;
BA_ "U_CD4_MY13_Hev_Rx" SG_ 1070 Veh_V_ActlEng_UB 1;
BA_ "U_CD4_MY13_Phev_Rx" SG_ 1070 Veh_V_ActlEng_UB 1;
BA_ "U_CD42_MY14_Diesel_Rx" SG_ 1070 Veh_V_ActlEng_UB 1;
BA_ "U_CD42_MY14_Gas_Rx" SG_ 1070 Veh_V_ActlEng_UB 1;
BA_ "U_P552_MY15_Gas_Rx" SG_ 1070 Veh_V_ActlEng_UB 1;
BA_ "U_S550_MY15_Gas_Rx" SG_ 1070 Veh_V_ActlEng_UB 1;
BA_ "U_C489_MY14_Gas_Rx" SG_ 1070 Veh_V_ActlEng_UB 1;
BA_ "U_B562LC_MY14_Gas_Rx" SG_ 1070 Veh_V_ActlEng_UB 1;
BA_ "U_U502_MY15_Gas_Rx" SG_ 1070 Veh_V_ActlEng_UB 1;
BA_ "U_UP375_MY15_Gas_Rx" SG_ 1070 Veh_V_ActlEng_UB 1;
BA_ "U_UP375_MY15_Diesel_Rx" SG_ 1070 Veh_V_ActlEng_UB 1;
BA_ "U_CD43_MY16_Gas_Rx" SG_ 1070 Veh_V_ActlEng_UB 1;
BA_ "U_CD4_MY14_Diesel_Rx" SG_ 1070 Veh_V_ActlEng_UB 1;
BA_ "U_CD4_MY14_Gas_Rx" SG_ 1070 Veh_V_ActlEng_UB 1;
BA_ "U_CD4_MY14_Hev_Rx" SG_ 1070 Veh_V_ActlEng_UB 1;
BA_ "U_CD4_MY14_Phev_Rx" SG_ 1070 Veh_V_ActlEng_UB 1;
BA_ "CrossOver_InfoCAN" SG_ 1070 Veh_V_ActlEng 1;
BA_ "CrossOver_LIN" SG_ 1070 Veh_V_ActlEng 1;
BA_ "U_CD4_MY13_Diesel_Rx" SG_ 1070 Veh_V_ActlEng 1;
BA_ "U_CD4_MY13_Gas_Rx" SG_ 1070 Veh_V_ActlEng 1;
BA_ "U_CD4_MY13_Hev_Rx" SG_ 1070 Veh_V_ActlEng 1;
BA_ "U_CD4_MY13_Phev_Rx" SG_ 1070 Veh_V_ActlEng 1;
BA_ "U_CD42_MY14_Diesel_Rx" SG_ 1070 Veh_V_ActlEng 1;
BA_ "U_CD42_MY14_Gas_Rx" SG_ 1070 Veh_V_ActlEng 1;
BA_ "U_P552_MY15_Gas_Rx" SG_ 1070 Veh_V_ActlEng 1;
BA_ "U_S550_MY15_Gas_Rx" SG_ 1070 Veh_V_ActlEng 1;
BA_ "U_C489_MY14_Gas_Rx" SG_ 1070 Veh_V_ActlEng 1;
BA_ "U_B562LC_MY14_Gas_Rx" SG_ 1070 Veh_V_ActlEng 1;
BA_ "U_U502_MY15_Gas_Rx" SG_ 1070 Veh_V_ActlEng 1;
BA_ "U_UP375_MY15_Gas_Rx" SG_ 1070 Veh_V_ActlEng 1;
BA_ "U_UP375_MY15_Diesel_Rx" SG_ 1070 Veh_V_ActlEng 1;
BA_ "U_CD43_MY16_Gas_Rx" SG_ 1070 Veh_V_ActlEng 1;
BA_ "U_CD4_MY14_Diesel_Rx" SG_ 1070 Veh_V_ActlEng 1;
BA_ "U_CD4_MY14_Gas_Rx" SG_ 1070 Veh_V_ActlEng 1;
BA_ "U_CD4_MY14_Hev_Rx" SG_ 1070 Veh_V_ActlEng 1;
BA_ "U_CD4_MY14_Phev_Rx" SG_ 1070 Veh_V_ActlEng 1;
BA_ "GenSigTimeoutTime_SODR" SG_ 1070 Veh_V_ActlEng 800;
BA_ "GenSigTimeoutTime_SODL" SG_ 1070 Veh_V_ActlEng 800;
BA_ "CrossOver_InfoCAN" SG_ 1070 PassRstrnInd_Req 1;
BA_ "GenSigStartValue" SG_ 1070 PassRstrnInd_Req 3;
BA_ "U_CD4_MY13_Diesel_Rx" SG_ 1070 PassRstrnInd_Req 1;
BA_ "U_CD4_MY13_Gas_Rx" SG_ 1070 PassRstrnInd_Req 1;
BA_ "U_CD4_MY13_Hev_Rx" SG_ 1070 PassRstrnInd_Req 1;
BA_ "U_CD4_MY13_Phev_Rx" SG_ 1070 PassRstrnInd_Req 1;
BA_ "U_CD42_MY14_Diesel_Rx" SG_ 1070 PassRstrnInd_Req 1;
BA_ "U_CD42_MY14_Gas_Rx" SG_ 1070 PassRstrnInd_Req 1;
BA_ "U_P552_MY15_Gas_Rx" SG_ 1070 PassRstrnInd_Req 1;
BA_ "U_S550_MY15_Gas_Rx" SG_ 1070 PassRstrnInd_Req 1;
BA_ "U_C489_MY14_Gas_Rx" SG_ 1070 PassRstrnInd_Req 1;
BA_ "U_U502_MY15_Gas_Rx" SG_ 1070 PassRstrnInd_Req 1;
BA_ "U_UP375_MY15_Gas_Rx" SG_ 1070 PassRstrnInd_Req 1;
BA_ "U_UP375_MY15_Diesel_Rx" SG_ 1070 PassRstrnInd_Req 1;
BA_ "U_CD43_MY16_Gas_Rx" SG_ 1070 PassRstrnInd_Req 1;
BA_ "GenSigSendType" SG_ 1050 SteWhlHeat_D_Rq 3;
BA_ "U_CD4_MY13_Diesel_Rx" SG_ 1050 SteWhlHeat_D_Rq 1;
BA_ "U_CD4_MY13_Gas_Rx" SG_ 1050 SteWhlHeat_D_Rq 1;
BA_ "U_CD4_MY13_Hev_Rx" SG_ 1050 SteWhlHeat_D_Rq 1;
BA_ "U_CD4_MY13_Phev_Rx" SG_ 1050 SteWhlHeat_D_Rq 1;
BA_ "U_CD42_MY14_Diesel_Rx" SG_ 1050 SteWhlHeat_D_Rq 1;
BA_ "U_CD42_MY14_Gas_Rx" SG_ 1050 SteWhlHeat_D_Rq 1;
BA_ "U_P552_MY15_Gas_Rx" SG_ 1050 SteWhlHeat_D_Rq 1;
BA_ "U_C489_MY14_Gas_Rx" SG_ 1050 SteWhlHeat_D_Rq 1;
BA_ "U_U502_MY15_Gas_Rx" SG_ 1050 SteWhlHeat_D_Rq 1;
BA_ "U_CD43_MY16_Gas_Rx" SG_ 1050 SteWhlHeat_D_Rq 1;
BA_ "U_CD4_MY13_Diesel_Tx" SG_ 1050 SteWhlHeat_D_Rq 1;
BA_ "U_CD4_MY13_Gas_Tx" SG_ 1050 SteWhlHeat_D_Rq 1;
BA_ "U_CD4_MY13_Hev_Tx" SG_ 1050 SteWhlHeat_D_Rq 1;
BA_ "U_CD4_MY13_Phev_Tx" SG_ 1050 SteWhlHeat_D_Rq 1;
BA_ "U_CD42_MY14_Diesel_Tx" SG_ 1050 SteWhlHeat_D_Rq 1;
BA_ "U_CD42_MY14_Gas_Tx" SG_ 1050 SteWhlHeat_D_Rq 1;
BA_ "U_P552_MY15_Gas_Tx" SG_ 1050 SteWhlHeat_D_Rq 1;
BA_ "U_C489_MY14_Gas_Tx" SG_ 1050 SteWhlHeat_D_Rq 1;
BA_ "U_U502_MY15_Gas_Tx" SG_ 1050 SteWhlHeat_D_Rq 1;
BA_ "U_UP375_MY15_Gas_Tx" SG_ 1050 SteWhlHeat_D_Rq 1;
BA_ "U_UP375_MY15_Diesel_Tx" SG_ 1050 SteWhlHeat_D_Rq 1;
BA_ "U_CD43_MY16_Gas_Tx" SG_ 1050 SteWhlHeat_D_Rq 1;
BA_ "GenSigSendType" SG_ 1050 MirrorHeatOn_B_Rq 3;
BA_ "U_CD4_MY13_Diesel_Rx" SG_ 1050 MirrorHeatOn_B_Rq 1;
BA_ "U_CD4_MY13_Gas_Rx" SG_ 1050 MirrorHeatOn_B_Rq 1;
BA_ "U_CD4_MY13_Hev_Rx" SG_ 1050 MirrorHeatOn_B_Rq 1;
BA_ "U_CD4_MY13_Phev_Rx" SG_ 1050 MirrorHeatOn_B_Rq 1;
BA_ "U_CD42_MY14_Diesel_Rx" SG_ 1050 MirrorHeatOn_B_Rq 1;
BA_ "U_CD42_MY14_Gas_Rx" SG_ 1050 MirrorHeatOn_B_Rq 1;
BA_ "U_P552_MY15_Gas_Rx" SG_ 1050 MirrorHeatOn_B_Rq 1;
BA_ "U_S550_MY15_Gas_Rx" SG_ 1050 MirrorHeatOn_B_Rq 1;
BA_ "U_C489_MY14_Gas_Rx" SG_ 1050 MirrorHeatOn_B_Rq 1;
BA_ "U_U502_MY15_Gas_Rx" SG_ 1050 MirrorHeatOn_B_Rq 1;
BA_ "U_UP375_MY15_Gas_Rx" SG_ 1050 MirrorHeatOn_B_Rq 1;
BA_ "U_UP375_MY15_Diesel_Rx" SG_ 1050 MirrorHeatOn_B_Rq 1;
BA_ "U_CD43_MY16_Gas_Rx" SG_ 1050 MirrorHeatOn_B_Rq 1;
BA_ "U_CD4_MY14_Diesel_Rx" SG_ 1050 MirrorHeatOn_B_Rq 1;
BA_ "U_CD4_MY14_Gas_Rx" SG_ 1050 MirrorHeatOn_B_Rq 1;
BA_ "U_CD4_MY14_Hev_Rx" SG_ 1050 MirrorHeatOn_B_Rq 1;
BA_ "U_CD4_MY14_Phev_Rx" SG_ 1050 MirrorHeatOn_B_Rq 1;
BA_ "U_CD4_MY13_Diesel_Tx" SG_ 1050 MirrorHeatOn_B_Rq 1;
BA_ "U_CD4_MY13_Gas_Tx" SG_ 1050 MirrorHeatOn_B_Rq 1;
BA_ "U_CD4_MY13_Hev_Tx" SG_ 1050 MirrorHeatOn_B_Rq 1;
BA_ "U_CD4_MY13_Phev_Tx" SG_ 1050 MirrorHeatOn_B_Rq 1;
BA_ "U_CD42_MY14_Diesel_Tx" SG_ 1050 MirrorHeatOn_B_Rq 1;
BA_ "U_CD42_MY14_Gas_Tx" SG_ 1050 MirrorHeatOn_B_Rq 1;
BA_ "U_P552_MY15_Gas_Tx" SG_ 1050 MirrorHeatOn_B_Rq 1;
BA_ "U_S550_MY15_Gas_Tx" SG_ 1050 MirrorHeatOn_B_Rq 1;
BA_ "U_C489_MY14_Gas_Tx" SG_ 1050 MirrorHeatOn_B_Rq 1;
BA_ "U_U502_MY15_Gas_Tx" SG_ 1050 MirrorHeatOn_B_Rq 1;
BA_ "U_UP375_MY15_Gas_Tx" SG_ 1050 MirrorHeatOn_B_Rq 1;
BA_ "U_UP375_MY15_Diesel_Tx" SG_ 1050 MirrorHeatOn_B_Rq 1;
BA_ "U_CD43_MY16_Gas_Tx" SG_ 1050 MirrorHeatOn_B_Rq 1;
BA_ "GenSigSendType" SG_ 1050 Remote_Start_QuietMode 3;
BA_ "U_CD4_MY13_Diesel_Tx" SG_ 1050 Remote_Start_QuietMode 1;
BA_ "U_CD4_MY13_Gas_Tx" SG_ 1050 Remote_Start_QuietMode 1;
BA_ "U_CD4_MY13_Hev_Tx" SG_ 1050 Remote_Start_QuietMode 1;
BA_ "U_CD4_MY13_Phev_Tx" SG_ 1050 Remote_Start_QuietMode 1;
BA_ "U_CD42_MY14_Diesel_Tx" SG_ 1050 Remote_Start_QuietMode 1;
BA_ "U_CD42_MY14_Gas_Tx" SG_ 1050 Remote_Start_QuietMode 1;
BA_ "U_P552_MY15_Gas_Tx" SG_ 1050 Remote_Start_QuietMode 1;
BA_ "U_S550_MY15_Gas_Tx" SG_ 1050 Remote_Start_QuietMode 1;
BA_ "U_C489_MY14_Gas_Tx" SG_ 1050 Remote_Start_QuietMode 1;
BA_ "U_U502_MY15_Gas_Tx" SG_ 1050 Remote_Start_QuietMode 1;
BA_ "U_UP375_MY15_Gas_Tx" SG_ 1050 Remote_Start_QuietMode 1;
BA_ "U_UP375_MY15_Diesel_Tx" SG_ 1050 Remote_Start_QuietMode 1;
BA_ "U_CD43_MY16_Gas_Tx" SG_ 1050 Remote_Start_QuietMode 1;
BA_ "CrossOver_InfoCAN" SG_ 1050 Outside_Air_Temp_Stat 1;
BA_ "GenSigStartValue" SG_ 1050 Outside_Air_Temp_Stat 255;
BA_ "GenSigSendType" SG_ 1050 Outside_Air_Temp_Stat 3;
BA_ "U_CD4_MY13_Diesel_Rx" SG_ 1050 Outside_Air_Temp_Stat 1;
BA_ "U_CD4_MY13_Gas_Rx" SG_ 1050 Outside_Air_Temp_Stat 1;
BA_ "U_CD4_MY13_Hev_Rx" SG_ 1050 Outside_Air_Temp_Stat 1;
BA_ "U_CD4_MY13_Phev_Rx" SG_ 1050 Outside_Air_Temp_Stat 1;
BA_ "U_CD42_MY14_Diesel_Rx" SG_ 1050 Outside_Air_Temp_Stat 1;
BA_ "U_CD42_MY14_Gas_Rx" SG_ 1050 Outside_Air_Temp_Stat 1;
BA_ "U_P552_MY15_Gas_Rx" SG_ 1050 Outside_Air_Temp_Stat 1;
BA_ "U_S550_MY15_Gas_Rx" SG_ 1050 Outside_Air_Temp_Stat 1;
BA_ "U_C489_MY14_Gas_Rx" SG_ 1050 Outside_Air_Temp_Stat 1;
BA_ "U_U502_MY15_Gas_Rx" SG_ 1050 Outside_Air_Temp_Stat 1;
BA_ "U_UP375_MY15_Gas_Rx" SG_ 1050 Outside_Air_Temp_Stat 1;
BA_ "U_UP375_MY15_Diesel_Rx" SG_ 1050 Outside_Air_Temp_Stat 1;
BA_ "U_CD43_MY16_Gas_Rx" SG_ 1050 Outside_Air_Temp_Stat 1;
BA_ "U_CD4_MY14_Diesel_Rx" SG_ 1050 Outside_Air_Temp_Stat 1;
BA_ "U_CD4_MY14_Gas_Rx" SG_ 1050 Outside_Air_Temp_Stat 1;
BA_ "U_CD4_MY14_Hev_Rx" SG_ 1050 Outside_Air_Temp_Stat 1;
BA_ "U_CD4_MY14_Phev_Rx" SG_ 1050 Outside_Air_Temp_Stat 1;
BA_ "U_CD4_MY13_Diesel_Tx" SG_ 1050 Outside_Air_Temp_Stat 1;
BA_ "U_CD4_MY13_Gas_Tx" SG_ 1050 Outside_Air_Temp_Stat 1;
BA_ "U_CD4_MY13_Hev_Tx" SG_ 1050 Outside_Air_Temp_Stat 1;
BA_ "U_CD4_MY13_Phev_Tx" SG_ 1050 Outside_Air_Temp_Stat 1;
BA_ "U_CD42_MY14_Diesel_Tx" SG_ 1050 Outside_Air_Temp_Stat 1;
BA_ "U_CD42_MY14_Gas_Tx" SG_ 1050 Outside_Air_Temp_Stat 1;
BA_ "U_P552_MY15_Gas_Tx" SG_ 1050 Outside_Air_Temp_Stat 1;
BA_ "U_S550_MY15_Gas_Tx" SG_ 1050 Outside_Air_Temp_Stat 1;
BA_ "U_C489_MY14_Gas_Tx" SG_ 1050 Outside_Air_Temp_Stat 1;
BA_ "U_U502_MY15_Gas_Tx" SG_ 1050 Outside_Air_Temp_Stat 1;
BA_ "U_UP375_MY15_Gas_Tx" SG_ 1050 Outside_Air_Temp_Stat 1;
BA_ "U_UP375_MY15_Diesel_Tx" SG_ 1050 Outside_Air_Temp_Stat 1;
BA_ "U_CD43_MY16_Gas_Tx" SG_ 1050 Outside_Air_Temp_Stat 1;
BA_ "GenSigSendType" SG_ 1856 TesterPhysicalReqDDM 3;
BA_ "U_CD4_MY13_Diesel_Rx" SG_ 1856 TesterPhysicalReqDDM 1;
BA_ "U_CD4_MY13_Gas_Rx" SG_ 1856 TesterPhysicalReqDDM 1;
BA_ "U_CD4_MY13_Hev_Rx" SG_ 1856 TesterPhysicalReqDDM 1;
BA_ "U_CD4_MY13_Phev_Rx" SG_ 1856 TesterPhysicalReqDDM 1;
BA_ "U_CD42_MY14_Diesel_Rx" SG_ 1856 TesterPhysicalReqDDM 1;
BA_ "U_CD42_MY14_Gas_Rx" SG_ 1856 TesterPhysicalReqDDM 1;
BA_ "U_P552_MY15_Gas_Rx" SG_ 1856 TesterPhysicalReqDDM 1;
BA_ "U_S550_MY15_Gas_Rx" SG_ 1856 TesterPhysicalReqDDM 1;
BA_ "U_C489_MY14_Gas_Rx" SG_ 1856 TesterPhysicalReqDDM 1;
BA_ "U_U502_MY15_Gas_Rx" SG_ 1856 TesterPhysicalReqDDM 1;
BA_ "U_UP375_MY15_Gas_Rx" SG_ 1856 TesterPhysicalReqDDM 1;
BA_ "U_UP375_MY15_Diesel_Rx" SG_ 1856 TesterPhysicalReqDDM 1;
BA_ "U_CD43_MY16_Gas_Rx" SG_ 1856 TesterPhysicalReqDDM 1;
BA_ "U_CD4_MY14_Diesel_Rx" SG_ 1856 TesterPhysicalReqDDM 1;
BA_ "U_CD4_MY14_Gas_Rx" SG_ 1856 TesterPhysicalReqDDM 1;
BA_ "U_CD4_MY14_Hev_Rx" SG_ 1856 TesterPhysicalReqDDM 1;
BA_ "U_CD4_MY14_Phev_Rx" SG_ 1856 TesterPhysicalReqDDM 1;
BA_ "GenSigSendType" SG_ 1864 TesterPhysicalResDDM 3;
BA_ "U_CD4_MY13_Diesel_Tx" SG_ 1864 TesterPhysicalResDDM 1;
BA_ "U_CD4_MY13_Gas_Tx" SG_ 1864 TesterPhysicalResDDM 1;
BA_ "U_CD4_MY13_Hev_Tx" SG_ 1864 TesterPhysicalResDDM 1;
BA_ "U_CD4_MY13_Phev_Tx" SG_ 1864 TesterPhysicalResDDM 1;
BA_ "U_CD42_MY14_Diesel_Tx" SG_ 1864 TesterPhysicalResDDM 1;
BA_ "U_CD42_MY14_Gas_Tx" SG_ 1864 TesterPhysicalResDDM 1;
BA_ "U_P552_MY15_Gas_Tx" SG_ 1864 TesterPhysicalResDDM 1;
BA_ "U_S550_MY15_Gas_Tx" SG_ 1864 TesterPhysicalResDDM 1;
BA_ "U_C489_MY14_Gas_Tx" SG_ 1864 TesterPhysicalResDDM 1;
BA_ "U_U502_MY15_Gas_Tx" SG_ 1864 TesterPhysicalResDDM 1;
BA_ "U_UP375_MY15_Gas_Tx" SG_ 1864 TesterPhysicalResDDM 1;
BA_ "U_UP375_MY15_Diesel_Tx" SG_ 1864 TesterPhysicalResDDM 1;
BA_ "U_CD43_MY16_Gas_Tx" SG_ 1864 TesterPhysicalResDDM 1;
BA_ "U_CD4_MY14_Diesel_Tx" SG_ 1864 TesterPhysicalResDDM 1;
BA_ "U_CD4_MY14_Gas_Tx" SG_ 1864 TesterPhysicalResDDM 1;
BA_ "U_CD4_MY14_Hev_Tx" SG_ 1864 TesterPhysicalResDDM 1;
BA_ "U_CD4_MY14_Phev_Tx" SG_ 1864 TesterPhysicalResDDM 1;
BA_ "GenSigSendType" SG_ 1937 TesterPhysicalReqTRM 3;
BA_ "U_CD4_MY13_Diesel_Rx" SG_ 1937 TesterPhysicalReqTRM 1;
BA_ "U_CD4_MY13_Gas_Rx" SG_ 1937 TesterPhysicalReqTRM 1;
BA_ "U_CD4_MY13_Hev_Rx" SG_ 1937 TesterPhysicalReqTRM 1;
BA_ "U_CD4_MY13_Phev_Rx" SG_ 1937 TesterPhysicalReqTRM 1;
BA_ "U_CD42_MY14_Diesel_Rx" SG_ 1937 TesterPhysicalReqTRM 1;
BA_ "U_CD42_MY14_Gas_Rx" SG_ 1937 TesterPhysicalReqTRM 1;
BA_ "U_P552_MY15_Gas_Rx" SG_ 1937 TesterPhysicalReqTRM 1;
BA_ "U_C489_MY14_Gas_Rx" SG_ 1937 TesterPhysicalReqTRM 1;
BA_ "U_UP375_MY15_Gas_Rx" SG_ 1937 TesterPhysicalReqTRM 1;
BA_ "U_UP375_MY15_Diesel_Rx" SG_ 1937 TesterPhysicalReqTRM 1;
BA_ "GenSigSendType" SG_ 1364 TRM_Network_Mgmt 3;
BA_ "U_CD4_MY13_Diesel_Rx" SG_ 1364 TRM_Network_Mgmt 1;
BA_ "U_CD4_MY13_Gas_Rx" SG_ 1364 TRM_Network_Mgmt 1;
BA_ "U_CD4_MY13_Hev_Rx" SG_ 1364 TRM_Network_Mgmt 1;
BA_ "U_CD4_MY13_Phev_Rx" SG_ 1364 TRM_Network_Mgmt 1;
BA_ "U_CD42_MY14_Diesel_Rx" SG_ 1364 TRM_Network_Mgmt 1;
BA_ "U_CD42_MY14_Gas_Rx" SG_ 1364 TRM_Network_Mgmt 1;
BA_ "U_P552_MY15_Gas_Rx" SG_ 1364 TRM_Network_Mgmt 1;
BA_ "U_S550_MY15_Gas_Rx" SG_ 1364 TRM_Network_Mgmt 1;
BA_ "U_C489_MY14_Gas_Rx" SG_ 1364 TRM_Network_Mgmt 1;
BA_ "U_U502_MY15_Gas_Rx" SG_ 1364 TRM_Network_Mgmt 1;
BA_ "U_CD43_MY16_Gas_Rx" SG_ 1364 TRM_Network_Mgmt 1;
BA_ "U_CD4_MY14_Diesel_Rx" SG_ 1364 TRM_Network_Mgmt 1;
BA_ "U_CD4_MY14_Gas_Rx" SG_ 1364 TRM_Network_Mgmt 1;
BA_ "U_CD4_MY14_Hev_Rx" SG_ 1364 TRM_Network_Mgmt 1;
BA_ "U_CD4_MY14_Phev_Rx" SG_ 1364 TRM_Network_Mgmt 1;
BA_ "U_UP375_MY15_Gas_Rx" SG_ 1364 TRM_Network_Mgmt 1;
BA_ "U_UP375_MY15_Diesel_Rx" SG_ 1364 TRM_Network_Mgmt 1;
BA_ "U_CD4_MY13_Diesel_Tx" SG_ 1364 TRM_Network_Mgmt 1;
BA_ "U_CD4_MY13_Gas_Tx" SG_ 1364 TRM_Network_Mgmt 1;
BA_ "U_CD4_MY13_Hev_Tx" SG_ 1364 TRM_Network_Mgmt 1;
BA_ "U_CD4_MY13_Phev_Tx" SG_ 1364 TRM_Network_Mgmt 1;
BA_ "U_CD42_MY14_Diesel_Tx" SG_ 1364 TRM_Network_Mgmt 1;
BA_ "U_CD42_MY14_Gas_Tx" SG_ 1364 TRM_Network_Mgmt 1;
BA_ "U_P552_MY15_Gas_Tx" SG_ 1364 TRM_Network_Mgmt 1;
BA_ "U_C489_MY14_Gas_Tx" SG_ 1364 TRM_Network_Mgmt 1;
BA_ "U_UP375_MY15_Gas_Tx" SG_ 1364 TRM_Network_Mgmt 1;
BA_ "U_UP375_MY15_Diesel_Tx" SG_ 1364 TRM_Network_Mgmt 1;
BA_ "WakeupSignal" SG_ 947 DimmingLvlEvnt_No_Actl 1;
BA_ "CrossOver_InfoCAN" SG_ 947 TurnLghtRightOn_B_Stat 1;
BA_ "CrossOver_LIN" SG_ 947 TurnLghtRightOn_B_Stat 1;
BA_ "CrossOver_InfoCAN" SG_ 947 TurnLghtLeftOn_B_Stat 1;
BA_ "CrossOver_LIN" SG_ 947 TurnLghtLeftOn_B_Stat 1;
BA_ "WakeupSignal" SG_ 947 Backlit_LED_Status 1;
BA_ "CrossOver_InfoCAN" SG_ 947 Backlit_LED_Status 1;
BA_ "U_CD4_MY13_Diesel_Rx" SG_ 947 Backlit_LED_Status 1;
BA_ "U_CD4_MY13_Gas_Rx" SG_ 947 Backlit_LED_Status 1;
BA_ "U_CD4_MY13_Hev_Rx" SG_ 947 Backlit_LED_Status 1;
BA_ "U_CD4_MY13_Phev_Rx" SG_ 947 Backlit_LED_Status 1;
BA_ "U_CD42_MY14_Diesel_Rx" SG_ 947 Backlit_LED_Status 1;
BA_ "U_CD42_MY14_Gas_Rx" SG_ 947 Backlit_LED_Status 1;
BA_ "U_P552_MY15_Gas_Rx" SG_ 947 Backlit_LED_Status 1;
BA_ "U_S550_MY15_Gas_Rx" SG_ 947 Backlit_LED_Status 1;
BA_ "U_C489_MY14_Gas_Rx" SG_ 947 Backlit_LED_Status 1;
BA_ "U_U502_MY15_Gas_Rx" SG_ 947 Backlit_LED_Status 1;
BA_ "U_UP375_MY15_Gas_Rx" SG_ 947 Backlit_LED_Status 1;
BA_ "U_UP375_MY15_Diesel_Rx" SG_ 947 Backlit_LED_Status 1;
BA_ "U_CD43_MY16_Gas_Rx" SG_ 947 Backlit_LED_Status 1;
BA_ "U_CD4_MY14_Diesel_Rx" SG_ 947 Backlit_LED_Status 1;
BA_ "U_CD4_MY14_Gas_Rx" SG_ 947 Backlit_LED_Status 1;
BA_ "U_CD4_MY14_Hev_Rx" SG_ 947 Backlit_LED_Status 1;
BA_ "U_CD4_MY14_Phev_Rx" SG_ 947 Backlit_LED_Status 1;
BA_ "CrossOver_InfoCAN" SG_ 947 FogLghtRearOn_B_Stat 1;
BA_ "U_CD4_MY13_Diesel_Rx" SG_ 947 FogLghtRearOn_B_Stat 1;
BA_ "U_CD4_MY13_Gas_Rx" SG_ 947 FogLghtRearOn_B_Stat 1;
BA_ "U_CD4_MY13_Hev_Rx" SG_ 947 FogLghtRearOn_B_Stat 1;
BA_ "U_CD4_MY13_Phev_Rx" SG_ 947 FogLghtRearOn_B_Stat 1;
BA_ "U_CD42_MY14_Diesel_Rx" SG_ 947 FogLghtRearOn_B_Stat 1;
BA_ "U_CD42_MY14_Gas_Rx" SG_ 947 FogLghtRearOn_B_Stat 1;
BA_ "U_P552_MY15_Gas_Rx" SG_ 947 FogLghtRearOn_B_Stat 1;
BA_ "U_C489_MY14_Gas_Rx" SG_ 947 FogLghtRearOn_B_Stat 1;
BA_ "U_UP375_MY15_Gas_Rx" SG_ 947 FogLghtRearOn_B_Stat 1;
BA_ "U_UP375_MY15_Diesel_Rx" SG_ 947 FogLghtRearOn_B_Stat 1;
BA_ "CrossOver_InfoCAN" SG_ 947 IgnKeyType_D_Actl 1;
BA_ "GenSigStartValue" SG_ 947 IgnKeyType_D_Actl 14;
BA_ "U_CD4_MY13_Diesel_Rx" SG_ 947 IgnKeyType_D_Actl 1;
BA_ "U_CD4_MY13_Gas_Rx" SG_ 947 IgnKeyType_D_Actl 1;
BA_ "U_CD4_MY13_Hev_Rx" SG_ 947 IgnKeyType_D_Actl 1;
BA_ "U_CD4_MY13_Phev_Rx" SG_ 947 IgnKeyType_D_Actl 1;
BA_ "U_CD42_MY14_Diesel_Rx" SG_ 947 IgnKeyType_D_Actl 1;
BA_ "U_CD42_MY14_Gas_Rx" SG_ 947 IgnKeyType_D_Actl 1;
BA_ "U_P552_MY15_Gas_Rx" SG_ 947 IgnKeyType_D_Actl 1;
BA_ "U_S550_MY15_Gas_Rx" SG_ 947 IgnKeyType_D_Actl 1;
BA_ "U_C489_MY14_Gas_Rx" SG_ 947 IgnKeyType_D_Actl 1;
BA_ "U_B562LC_MY14_Gas_Rx" SG_ 947 IgnKeyType_D_Actl 1;
BA_ "U_U502_MY15_Gas_Rx" SG_ 947 IgnKeyType_D_Actl 1;
BA_ "U_UP375_MY15_Gas_Rx" SG_ 947 IgnKeyType_D_Actl 1;
BA_ "U_UP375_MY15_Diesel_Rx" SG_ 947 IgnKeyType_D_Actl 1;
BA_ "U_CD43_MY16_Gas_Rx" SG_ 947 IgnKeyType_D_Actl 1;
BA_ "U_CD4_MY14_Diesel_Rx" SG_ 947 IgnKeyType_D_Actl 1;
BA_ "U_CD4_MY14_Gas_Rx" SG_ 947 IgnKeyType_D_Actl 1;
BA_ "U_CD4_MY14_Hev_Rx" SG_ 947 IgnKeyType_D_Actl 1;
BA_ "U_CD4_MY14_Phev_Rx" SG_ 947 IgnKeyType_D_Actl 1;
BA_ "WakeupSignal" SG_ 947 TurnLghtRight_D_Rq 1;
BA_ "CrossOver_InfoCAN" SG_ 947 TurnLghtRight_D_Rq 1;
BA_ "U_CD4_MY13_Diesel_Rx" SG_ 947 TurnLghtRight_D_Rq 1;
BA_ "U_CD4_MY13_Gas_Rx" SG_ 947 TurnLghtRight_D_Rq 1;
BA_ "U_CD4_MY13_Hev_Rx" SG_ 947 TurnLghtRight_D_Rq 1;
BA_ "U_CD4_MY13_Phev_Rx" SG_ 947 TurnLghtRight_D_Rq 1;
BA_ "U_CD42_MY14_Diesel_Rx" SG_ 947 TurnLghtRight_D_Rq 1;
BA_ "U_CD42_MY14_Gas_Rx" SG_ 947 TurnLghtRight_D_Rq 1;
BA_ "U_P552_MY15_Gas_Rx" SG_ 947 TurnLghtRight_D_Rq 1;
BA_ "U_C489_MY14_Gas_Rx" SG_ 947 TurnLghtRight_D_Rq 1;
BA_ "U_UP375_MY15_Gas_Rx" SG_ 947 TurnLghtRight_D_Rq 1;
BA_ "U_UP375_MY15_Diesel_Rx" SG_ 947 TurnLghtRight_D_Rq 1;
BA_ "U_S550_MY15_Gas_Rx" SG_ 947 TurnLghtRight_D_Rq 1;
BA_ "U_U502_MY15_Gas_Rx" SG_ 947 TurnLghtRight_D_Rq 1;
BA_ "U_CD43_MY16_Gas_Rx" SG_ 947 TurnLghtRight_D_Rq 1;
BA_ "U_CD4_MY14_Diesel_Rx" SG_ 947 TurnLghtRight_D_Rq 1;
BA_ "U_CD4_MY14_Gas_Rx" SG_ 947 TurnLghtRight_D_Rq 1;
BA_ "U_CD4_MY14_Hev_Rx" SG_ 947 TurnLghtRight_D_Rq 1;
BA_ "U_CD4_MY14_Phev_Rx" SG_ 947 TurnLghtRight_D_Rq 1;
BA_ "WakeupSignal" SG_ 947 Parklamp_Status 1;
BA_ "CrossOver_InfoCAN" SG_ 947 Parklamp_Status 1;
BA_ "GenSigStartValue" SG_ 947 Parklamp_Status 1;
BA_ "U_CD4_MY13_Diesel_Rx" SG_ 947 Parklamp_Status 1;
BA_ "U_CD4_MY13_Gas_Rx" SG_ 947 Parklamp_Status 1;
BA_ "U_CD4_MY13_Hev_Rx" SG_ 947 Parklamp_Status 1;
BA_ "U_CD4_MY13_Phev_Rx" SG_ 947 Parklamp_Status 1;
BA_ "U_CD42_MY14_Diesel_Rx" SG_ 947 Parklamp_Status 1;
BA_ "U_CD42_MY14_Gas_Rx" SG_ 947 Parklamp_Status 1;
BA_ "U_P552_MY15_Gas_Rx" SG_ 947 Parklamp_Status 1;
BA_ "U_S550_MY15_Gas_Rx" SG_ 947 Parklamp_Status 1;
BA_ "U_C489_MY14_Gas_Rx" SG_ 947 Parklamp_Status 1;
BA_ "U_U502_MY15_Gas_Rx" SG_ 947 Parklamp_Status 1;
BA_ "U_UP375_MY15_Gas_Rx" SG_ 947 Parklamp_Status 1;
BA_ "U_UP375_MY15_Diesel_Rx" SG_ 947 Parklamp_Status 1;
BA_ "U_CD43_MY16_Gas_Rx" SG_ 947 Parklamp_Status 1;
BA_ "U_B562LC_MY14_Gas_Rx" SG_ 947 Parklamp_Status 1;
BA_ "U_CD4_MY14_Diesel_Rx" SG_ 947 Parklamp_Status 1;
BA_ "U_CD4_MY14_Gas_Rx" SG_ 947 Parklamp_Status 1;
BA_ "U_CD4_MY14_Hev_Rx" SG_ 947 Parklamp_Status 1;
BA_ "U_CD4_MY14_Phev_Rx" SG_ 947 Parklamp_Status 1;
BA_ "WakeupSignal" SG_ 947 Litval 1;
BA_ "CrossOver_InfoCAN" SG_ 947 Litval 1;
BA_ "U_CD4_MY13_Diesel_Rx" SG_ 947 Litval 1;
BA_ "U_CD4_MY13_Gas_Rx" SG_ 947 Litval 1;
BA_ "U_CD4_MY13_Hev_Rx" SG_ 947 Litval 1;
BA_ "U_CD4_MY13_Phev_Rx" SG_ 947 Litval 1;
BA_ "U_CD42_MY14_Diesel_Rx" SG_ 947 Litval 1;
BA_ "U_CD42_MY14_Gas_Rx" SG_ 947 Litval 1;
BA_ "U_P552_MY15_Gas_Rx" SG_ 947 Litval 1;
BA_ "U_S550_MY15_Gas_Rx" SG_ 947 Litval 1;
BA_ "U_C489_MY14_Gas_Rx" SG_ 947 Litval 1;
BA_ "U_U502_MY15_Gas_Rx" SG_ 947 Litval 1;
BA_ "U_UP375_MY15_Gas_Rx" SG_ 947 Litval 1;
BA_ "U_UP375_MY15_Diesel_Rx" SG_ 947 Litval 1;
BA_ "U_CD43_MY16_Gas_Rx" SG_ 947 Litval 1;
BA_ "U_B562LC_MY14_Gas_Rx" SG_ 947 Litval 1;
BA_ "U_CD4_MY14_Diesel_Rx" SG_ 947 Litval 1;
BA_ "U_CD4_MY14_Gas_Rx" SG_ 947 Litval 1;
BA_ "U_CD4_MY14_Hev_Rx" SG_ 947 Litval 1;
BA_ "U_CD4_MY14_Phev_Rx" SG_ 947 Litval 1;
BA_ "WakeupSignal" SG_ 947 Key_In_Ignition_Stat 1;
BA_ "CrossOver_InfoCAN" SG_ 947 Key_In_Ignition_Stat 1;
BA_ "U_CD4_MY13_Diesel_Rx" SG_ 947 Key_In_Ignition_Stat 1;
BA_ "U_CD4_MY13_Gas_Rx" SG_ 947 Key_In_Ignition_Stat 1;
BA_ "U_CD4_MY13_Hev_Rx" SG_ 947 Key_In_Ignition_Stat 1;
BA_ "U_CD4_MY13_Phev_Rx" SG_ 947 Key_In_Ignition_Stat 1;
BA_ "U_CD42_MY14_Diesel_Rx" SG_ 947 Key_In_Ignition_Stat 1;
BA_ "U_CD42_MY14_Gas_Rx" SG_ 947 Key_In_Ignition_Stat 1;
BA_ "U_P552_MY15_Gas_Rx" SG_ 947 Key_In_Ignition_Stat 1;
BA_ "U_S550_MY15_Gas_Rx" SG_ 947 Key_In_Ignition_Stat 1;
BA_ "U_C489_MY14_Gas_Rx" SG_ 947 Key_In_Ignition_Stat 1;
BA_ "U_U502_MY15_Gas_Rx" SG_ 947 Key_In_Ignition_Stat 1;
BA_ "U_UP375_MY15_Gas_Rx" SG_ 947 Key_In_Ignition_Stat 1;
BA_ "U_UP375_MY15_Diesel_Rx" SG_ 947 Key_In_Ignition_Stat 1;
BA_ "U_CD43_MY16_Gas_Rx" SG_ 947 Key_In_Ignition_Stat 1;
BA_ "U_CD4_MY14_Diesel_Rx" SG_ 947 Key_In_Ignition_Stat 1;
BA_ "U_CD4_MY14_Gas_Rx" SG_ 947 Key_In_Ignition_Stat 1;
BA_ "U_CD4_MY14_Hev_Rx" SG_ 947 Key_In_Ignition_Stat 1;
BA_ "U_CD4_MY14_Phev_Rx" SG_ 947 Key_In_Ignition_Stat 1;
BA_ "WakeupSignal" SG_ 947 Ignition_Status 1;
BA_ "CrossOver_InfoCAN" SG_ 947 Ignition_Status 1;
BA_ "CrossOver_LIN" SG_ 947 Ignition_Status 1;
BA_ "U_CD4_MY13_Diesel_Rx" SG_ 947 Ignition_Status 1;
BA_ "U_CD4_MY13_Gas_Rx" SG_ 947 Ignition_Status 1;
BA_ "U_CD4_MY13_Hev_Rx" SG_ 947 Ignition_Status 1;
BA_ "U_CD4_MY13_Phev_Rx" SG_ 947 Ignition_Status 1;
BA_ "U_CD42_MY14_Diesel_Rx" SG_ 947 Ignition_Status 1;
BA_ "U_CD42_MY14_Gas_Rx" SG_ 947 Ignition_Status 1;
BA_ "U_P552_MY15_Gas_Rx" SG_ 947 Ignition_Status 1;
BA_ "U_S550_MY15_Gas_Rx" SG_ 947 Ignition_Status 1;
BA_ "U_C489_MY14_Gas_Rx" SG_ 947 Ignition_Status 1;
BA_ "U_B562LC_MY14_Gas_Rx" SG_ 947 Ignition_Status 1;
BA_ "U_U502_MY15_Gas_Rx" SG_ 947 Ignition_Status 1;
BA_ "U_UP375_MY15_Gas_Rx" SG_ 947 Ignition_Status 1;
BA_ "U_UP375_MY15_Diesel_Rx" SG_ 947 Ignition_Status 1;
BA_ "U_CD43_MY16_Gas_Rx" SG_ 947 Ignition_Status 1;
BA_ "U_CD4_MY14_Diesel_Rx" SG_ 947 Ignition_Status 1;
BA_ "U_CD4_MY14_Gas_Rx" SG_ 947 Ignition_Status 1;
BA_ "U_CD4_MY14_Hev_Rx" SG_ 947 Ignition_Status 1;
BA_ "U_CD4_MY14_Phev_Rx" SG_ 947 Ignition_Status 1;
BA_ "WakeupSignal" SG_ 947 Dimming_Lvl 1;
BA_ "CrossOver_InfoCAN" SG_ 947 Dimming_Lvl 1;
BA_ "CrossOver_LIN" SG_ 947 Dimming_Lvl 1;
BA_ "GenSigStartValue" SG_ 947 Dimming_Lvl 12;
BA_ "U_CD4_MY13_Diesel_Rx" SG_ 947 Dimming_Lvl 1;
BA_ "U_CD4_MY13_Gas_Rx" SG_ 947 Dimming_Lvl 1;
BA_ "U_CD4_MY13_Hev_Rx" SG_ 947 Dimming_Lvl 1;
BA_ "U_CD4_MY13_Phev_Rx" SG_ 947 Dimming_Lvl 1;
BA_ "U_CD42_MY14_Diesel_Rx" SG_ 947 Dimming_Lvl 1;
BA_ "U_CD42_MY14_Gas_Rx" SG_ 947 Dimming_Lvl 1;
BA_ "U_P552_MY15_Gas_Rx" SG_ 947 Dimming_Lvl 1;
BA_ "U_S550_MY15_Gas_Rx" SG_ 947 Dimming_Lvl 1;
BA_ "U_C489_MY14_Gas_Rx" SG_ 947 Dimming_Lvl 1;
BA_ "U_U502_MY15_Gas_Rx" SG_ 947 Dimming_Lvl 1;
BA_ "U_UP375_MY15_Gas_Rx" SG_ 947 Dimming_Lvl 1;
BA_ "U_UP375_MY15_Diesel_Rx" SG_ 947 Dimming_Lvl 1;
BA_ "U_CD43_MY16_Gas_Rx" SG_ 947 Dimming_Lvl 1;
BA_ "U_CD4_MY14_Diesel_Rx" SG_ 947 Dimming_Lvl 1;
BA_ "U_CD4_MY14_Gas_Rx" SG_ 947 Dimming_Lvl 1;
BA_ "U_CD4_MY14_Hev_Rx" SG_ 947 Dimming_Lvl 1;
BA_ "U_CD4_MY14_Phev_Rx" SG_ 947 Dimming_Lvl 1;
BA_ "WakeupSignal" SG_ 947 Day_Night_Status 1;
BA_ "CrossOver_InfoCAN" SG_ 947 Day_Night_Status 1;
BA_ "U_CD4_MY13_Diesel_Rx" SG_ 947 Day_Night_Status 1;
BA_ "U_CD4_MY13_Gas_Rx" SG_ 947 Day_Night_Status 1;
BA_ "U_CD4_MY13_Hev_Rx" SG_ 947 Day_Night_Status 1;
BA_ "U_CD4_MY13_Phev_Rx" SG_ 947 Day_Night_Status 1;
BA_ "U_CD42_MY14_Diesel_Rx" SG_ 947 Day_Night_Status 1;
BA_ "U_CD42_MY14_Gas_Rx" SG_ 947 Day_Night_Status 1;
BA_ "U_P552_MY15_Gas_Rx" SG_ 947 Day_Night_Status 1;
BA_ "U_S550_MY15_Gas_Rx" SG_ 947 Day_Night_Status 1;
BA_ "U_C489_MY14_Gas_Rx" SG_ 947 Day_Night_Status 1;
BA_ "U_U502_MY15_Gas_Rx" SG_ 947 Day_Night_Status 1;
BA_ "U_UP375_MY15_Gas_Rx" SG_ 947 Day_Night_Status 1;
BA_ "U_UP375_MY15_Diesel_Rx" SG_ 947 Day_Night_Status 1;
BA_ "U_CD43_MY16_Gas_Rx" SG_ 947 Day_Night_Status 1;
BA_ "U_CD4_MY14_Diesel_Rx" SG_ 947 Day_Night_Status 1;
BA_ "U_CD4_MY14_Gas_Rx" SG_ 947 Day_Night_Status 1;
BA_ "U_CD4_MY14_Hev_Rx" SG_ 947 Day_Night_Status 1;
BA_ "U_CD4_MY14_Phev_Rx" SG_ 947 Day_Night_Status 1;
BA_ "WakeupSignal" SG_ 947 Remote_Start_Status 1;
BA_ "CrossOver_InfoCAN" SG_ 947 Remote_Start_Status 1;
BA_ "U_CD4_MY13_Diesel_Rx" SG_ 947 Remote_Start_Status 1;
BA_ "U_CD4_MY13_Gas_Rx" SG_ 947 Remote_Start_Status 1;
BA_ "U_CD4_MY13_Hev_Rx" SG_ 947 Remote_Start_Status 1;
BA_ "U_CD4_MY13_Phev_Rx" SG_ 947 Remote_Start_Status 1;
BA_ "U_CD42_MY14_Diesel_Rx" SG_ 947 Remote_Start_Status 1;
BA_ "U_CD42_MY14_Gas_Rx" SG_ 947 Remote_Start_Status 1;
BA_ "U_P552_MY15_Gas_Rx" SG_ 947 Remote_Start_Status 1;
BA_ "U_S550_MY15_Gas_Rx" SG_ 947 Remote_Start_Status 1;
BA_ "U_C489_MY14_Gas_Rx" SG_ 947 Remote_Start_Status 1;
BA_ "U_U502_MY15_Gas_Rx" SG_ 947 Remote_Start_Status 1;
BA_ "U_UP375_MY15_Gas_Rx" SG_ 947 Remote_Start_Status 1;
BA_ "U_UP375_MY15_Diesel_Rx" SG_ 947 Remote_Start_Status 1;
BA_ "U_CD43_MY16_Gas_Rx" SG_ 947 Remote_Start_Status 1;
BA_ "U_CD4_MY14_Diesel_Rx" SG_ 947 Remote_Start_Status 1;
BA_ "U_CD4_MY14_Gas_Rx" SG_ 947 Remote_Start_Status 1;
BA_ "U_CD4_MY14_Hev_Rx" SG_ 947 Remote_Start_Status 1;
BA_ "U_CD4_MY14_Phev_Rx" SG_ 947 Remote_Start_Status 1;
BA_ "WakeupSignal" SG_ 947 DrStatTgate_B_Actl 1;
BA_ "CrossOver_InfoCAN" SG_ 947 DrStatTgate_B_Actl 1;
BA_ "CrossOver_LIN" SG_ 947 DrStatTgate_B_Actl 1;
BA_ "U_CD4_MY13_Diesel_Rx" SG_ 947 DrStatTgate_B_Actl 1;
BA_ "U_CD4_MY13_Gas_Rx" SG_ 947 DrStatTgate_B_Actl 1;
BA_ "U_CD42_MY14_Diesel_Rx" SG_ 947 DrStatTgate_B_Actl 1;
BA_ "U_CD42_MY14_Gas_Rx" SG_ 947 DrStatTgate_B_Actl 1;
BA_ "U_P552_MY15_Gas_Rx" SG_ 947 DrStatTgate_B_Actl 1;
BA_ "U_S550_MY15_Gas_Rx" SG_ 947 DrStatTgate_B_Actl 1;
BA_ "U_C489_MY14_Gas_Rx" SG_ 947 DrStatTgate_B_Actl 1;
BA_ "U_U502_MY15_Gas_Rx" SG_ 947 DrStatTgate_B_Actl 1;
BA_ "U_CD43_MY16_Gas_Rx" SG_ 947 DrStatTgate_B_Actl 1;
BA_ "U_CD4_MY14_Diesel_Rx" SG_ 947 DrStatTgate_B_Actl 1;
BA_ "U_CD4_MY14_Gas_Rx" SG_ 947 DrStatTgate_B_Actl 1;
BA_ "U_CD4_MY14_Hev_Rx" SG_ 947 DrStatTgate_B_Actl 1;
BA_ "U_CD4_MY14_Phev_Rx" SG_ 947 DrStatTgate_B_Actl 1;
BA_ "WakeupSignal" SG_ 947 DrStatRr_B_Actl 1;
BA_ "CrossOver_InfoCAN" SG_ 947 DrStatRr_B_Actl 1;
BA_ "U_CD4_MY13_Diesel_Rx" SG_ 947 DrStatRr_B_Actl 1;
BA_ "U_CD4_MY13_Gas_Rx" SG_ 947 DrStatRr_B_Actl 1;
BA_ "U_CD42_MY14_Diesel_Rx" SG_ 947 DrStatRr_B_Actl 1;
BA_ "U_CD42_MY14_Gas_Rx" SG_ 947 DrStatRr_B_Actl 1;
BA_ "U_P552_MY15_Gas_Rx" SG_ 947 DrStatRr_B_Actl 1;
BA_ "U_S550_MY15_Gas_Rx" SG_ 947 DrStatRr_B_Actl 1;
BA_ "U_C489_MY14_Gas_Rx" SG_ 947 DrStatRr_B_Actl 1;
BA_ "U_U502_MY15_Gas_Rx" SG_ 947 DrStatRr_B_Actl 1;
BA_ "U_CD43_MY16_Gas_Rx" SG_ 947 DrStatRr_B_Actl 1;
BA_ "U_CD4_MY14_Diesel_Rx" SG_ 947 DrStatRr_B_Actl 1;
BA_ "U_CD4_MY14_Gas_Rx" SG_ 947 DrStatRr_B_Actl 1;
BA_ "U_CD4_MY14_Hev_Rx" SG_ 947 DrStatRr_B_Actl 1;
BA_ "U_CD4_MY14_Phev_Rx" SG_ 947 DrStatRr_B_Actl 1;
BA_ "WakeupSignal" SG_ 947 DrStatRl_B_Actl 1;
BA_ "CrossOver_InfoCAN" SG_ 947 DrStatRl_B_Actl 1;
BA_ "U_CD4_MY13_Diesel_Rx" SG_ 947 DrStatRl_B_Actl 1;
BA_ "U_CD4_MY13_Gas_Rx" SG_ 947 DrStatRl_B_Actl 1;
BA_ "U_CD42_MY14_Diesel_Rx" SG_ 947 DrStatRl_B_Actl 1;
BA_ "U_CD42_MY14_Gas_Rx" SG_ 947 DrStatRl_B_Actl 1;
BA_ "U_P552_MY15_Gas_Rx" SG_ 947 DrStatRl_B_Actl 1;
BA_ "U_S550_MY15_Gas_Rx" SG_ 947 DrStatRl_B_Actl 1;
BA_ "U_C489_MY14_Gas_Rx" SG_ 947 DrStatRl_B_Actl 1;
BA_ "U_U502_MY15_Gas_Rx" SG_ 947 DrStatRl_B_Actl 1;
BA_ "U_CD43_MY16_Gas_Rx" SG_ 947 DrStatRl_B_Actl 1;
BA_ "U_CD4_MY14_Diesel_Rx" SG_ 947 DrStatRl_B_Actl 1;
BA_ "U_CD4_MY14_Gas_Rx" SG_ 947 DrStatRl_B_Actl 1;
BA_ "U_CD4_MY14_Hev_Rx" SG_ 947 DrStatRl_B_Actl 1;
BA_ "U_CD4_MY14_Phev_Rx" SG_ 947 DrStatRl_B_Actl 1;
BA_ "WakeupSignal" SG_ 947 DrStatPsngr_B_Actl 1;
BA_ "CrossOver_InfoCAN" SG_ 947 DrStatPsngr_B_Actl 1;
BA_ "U_CD4_MY13_Diesel_Rx" SG_ 947 DrStatPsngr_B_Actl 1;
BA_ "U_CD4_MY13_Gas_Rx" SG_ 947 DrStatPsngr_B_Actl 1;
BA_ "U_CD42_MY14_Diesel_Rx" SG_ 947 DrStatPsngr_B_Actl 1;
BA_ "U_CD42_MY14_Gas_Rx" SG_ 947 DrStatPsngr_B_Actl 1;
BA_ "U_P552_MY15_Gas_Rx" SG_ 947 DrStatPsngr_B_Actl 1;
BA_ "U_S550_MY15_Gas_Rx" SG_ 947 DrStatPsngr_B_Actl 1;
BA_ "U_C489_MY14_Gas_Rx" SG_ 947 DrStatPsngr_B_Actl 1;
BA_ "U_U502_MY15_Gas_Rx" SG_ 947 DrStatPsngr_B_Actl 1;
BA_ "U_CD43_MY16_Gas_Rx" SG_ 947 DrStatPsngr_B_Actl 1;
BA_ "U_CD4_MY14_Diesel_Rx" SG_ 947 DrStatPsngr_B_Actl 1;
BA_ "U_CD4_MY14_Gas_Rx" SG_ 947 DrStatPsngr_B_Actl 1;
BA_ "U_CD4_MY14_Hev_Rx" SG_ 947 DrStatPsngr_B_Actl 1;
BA_ "U_CD4_MY14_Phev_Rx" SG_ 947 DrStatPsngr_B_Actl 1;
BA_ "WakeupSignal" SG_ 947 DrStatInnrTgate_B_Actl 1;
BA_ "CrossOver_InfoCAN" SG_ 947 DrStatInnrTgate_B_Actl 1;
BA_ "CrossOver_LIN" SG_ 947 DrStatInnrTgate_B_Actl 1;
BA_ "U_CD4_MY13_Diesel_Rx" SG_ 947 DrStatInnrTgate_B_Actl 1;
BA_ "U_CD4_MY13_Gas_Rx" SG_ 947 DrStatInnrTgate_B_Actl 1;
BA_ "U_CD42_MY14_Diesel_Rx" SG_ 947 DrStatInnrTgate_B_Actl 1;
BA_ "U_CD42_MY14_Gas_Rx" SG_ 947 DrStatInnrTgate_B_Actl 1;
BA_ "U_P552_MY15_Gas_Rx" SG_ 947 DrStatInnrTgate_B_Actl 1;
BA_ "U_S550_MY15_Gas_Rx" SG_ 947 DrStatInnrTgate_B_Actl 1;
BA_ "U_C489_MY14_Gas_Rx" SG_ 947 DrStatInnrTgate_B_Actl 1;
BA_ "U_U502_MY15_Gas_Rx" SG_ 947 DrStatInnrTgate_B_Actl 1;
BA_ "U_CD43_MY16_Gas_Rx" SG_ 947 DrStatInnrTgate_B_Actl 1;
BA_ "U_CD4_MY14_Diesel_Rx" SG_ 947 DrStatInnrTgate_B_Actl 1;
BA_ "U_CD4_MY14_Gas_Rx" SG_ 947 DrStatInnrTgate_B_Actl 1;
BA_ "U_CD4_MY14_Hev_Rx" SG_ 947 DrStatInnrTgate_B_Actl 1;
BA_ "U_CD4_MY14_Phev_Rx" SG_ 947 DrStatInnrTgate_B_Actl 1;
BA_ "WakeupSignal" SG_ 947 DrStatHood_B_Actl 1;
BA_ "CrossOver_InfoCAN" SG_ 947 DrStatHood_B_Actl 1;
BA_ "U_CD4_MY13_Diesel_Rx" SG_ 947 DrStatHood_B_Actl 1;
BA_ "U_CD4_MY13_Gas_Rx" SG_ 947 DrStatHood_B_Actl 1;
BA_ "U_CD42_MY14_Diesel_Rx" SG_ 947 DrStatHood_B_Actl 1;
BA_ "U_CD42_MY14_Gas_Rx" SG_ 947 DrStatHood_B_Actl 1;
BA_ "U_P552_MY15_Gas_Rx" SG_ 947 DrStatHood_B_Actl 1;
BA_ "U_S550_MY15_Gas_Rx" SG_ 947 DrStatHood_B_Actl 1;
BA_ "U_C489_MY14_Gas_Rx" SG_ 947 DrStatHood_B_Actl 1;
BA_ "U_U502_MY15_Gas_Rx" SG_ 947 DrStatHood_B_Actl 1;
BA_ "U_CD43_MY16_Gas_Rx" SG_ 947 DrStatHood_B_Actl 1;
BA_ "U_CD4_MY14_Diesel_Rx" SG_ 947 DrStatHood_B_Actl 1;
BA_ "U_CD4_MY14_Gas_Rx" SG_ 947 DrStatHood_B_Actl 1;
BA_ "U_CD4_MY14_Hev_Rx" SG_ 947 DrStatHood_B_Actl 1;
BA_ "U_CD4_MY14_Phev_Rx" SG_ 947 DrStatHood_B_Actl 1;
BA_ "WakeupSignal" SG_ 947 DrStatDrv_B_Actl 1;
BA_ "CrossOver_InfoCAN" SG_ 947 DrStatDrv_B_Actl 1;
BA_ "U_CD4_MY13_Diesel_Rx" SG_ 947 DrStatDrv_B_Actl 1;
BA_ "U_CD4_MY13_Gas_Rx" SG_ 947 DrStatDrv_B_Actl 1;
BA_ "U_CD42_MY14_Diesel_Rx" SG_ 947 DrStatDrv_B_Actl 1;
BA_ "U_CD42_MY14_Gas_Rx" SG_ 947 DrStatDrv_B_Actl 1;
BA_ "U_P552_MY15_Gas_Rx" SG_ 947 DrStatDrv_B_Actl 1;
BA_ "U_S550_MY15_Gas_Rx" SG_ 947 DrStatDrv_B_Actl 1;
BA_ "U_C489_MY14_Gas_Rx" SG_ 947 DrStatDrv_B_Actl 1;
BA_ "U_U502_MY15_Gas_Rx" SG_ 947 DrStatDrv_B_Actl 1;
BA_ "U_CD43_MY16_Gas_Rx" SG_ 947 DrStatDrv_B_Actl 1;
BA_ "U_CD4_MY14_Diesel_Rx" SG_ 947 DrStatDrv_B_Actl 1;
BA_ "U_CD4_MY14_Gas_Rx" SG_ 947 DrStatDrv_B_Actl 1;
BA_ "U_CD4_MY14_Hev_Rx" SG_ 947 DrStatDrv_B_Actl 1;
BA_ "U_CD4_MY14_Phev_Rx" SG_ 947 DrStatDrv_B_Actl 1;
BA_ "WakeupSignal" SG_ 947 PrkBrkActv_B_Actl 1;
BA_ "CrossOver_InfoCAN" SG_ 947 PrkBrkActv_B_Actl 1;
BA_ "ContentDependant" SG_ 947 PrkBrkActv_B_Actl 1;
BA_ "CrossOver_InfoCAN" SG_ 947 LifeCycMde_D_Actl 1;
BA_ "U_CD4_MY13_Diesel_Rx" SG_ 947 LifeCycMde_D_Actl 1;
BA_ "U_CD4_MY13_Gas_Rx" SG_ 947 LifeCycMde_D_Actl 1;
BA_ "U_CD4_MY13_Hev_Rx" SG_ 947 LifeCycMde_D_Actl 1;
BA_ "U_CD4_MY13_Phev_Rx" SG_ 947 LifeCycMde_D_Actl 1;
BA_ "U_CD42_MY14_Diesel_Rx" SG_ 947 LifeCycMde_D_Actl 1;
BA_ "U_CD42_MY14_Gas_Rx" SG_ 947 LifeCycMde_D_Actl 1;
BA_ "U_P552_MY15_Gas_Rx" SG_ 947 LifeCycMde_D_Actl 1;
BA_ "U_C489_MY14_Gas_Rx" SG_ 947 LifeCycMde_D_Actl 1;
BA_ "U_U502_MY15_Gas_Rx" SG_ 947 LifeCycMde_D_Actl 1;
BA_ "U_CD43_MY16_Gas_Rx" SG_ 947 LifeCycMde_D_Actl 1;
BA_ "U_S550_MY15_Gas_Rx" SG_ 947 LifeCycMde_D_Actl 1;
BA_ "U_UP375_MY15_Gas_Rx" SG_ 947 LifeCycMde_D_Actl 1;
BA_ "U_UP375_MY15_Diesel_Rx" SG_ 947 LifeCycMde_D_Actl 1;
BA_ "U_CD4_MY14_Diesel_Rx" SG_ 947 LifeCycMde_D_Actl 1;
BA_ "U_CD4_MY14_Gas_Rx" SG_ 947 LifeCycMde_D_Actl 1;
BA_ "U_CD4_MY14_Hev_Rx" SG_ 947 LifeCycMde_D_Actl 1;
BA_ "U_CD4_MY14_Phev_Rx" SG_ 947 LifeCycMde_D_Actl 1;
BA_ "WakeupSignal" SG_ 947 Delay_Accy 1;
BA_ "CrossOver_InfoCAN" SG_ 947 Delay_Accy 1;
BA_ "U_CD4_MY13_Diesel_Rx" SG_ 947 Delay_Accy 1;
BA_ "U_CD4_MY13_Gas_Rx" SG_ 947 Delay_Accy 1;
BA_ "U_CD4_MY13_Hev_Rx" SG_ 947 Delay_Accy 1;
BA_ "U_CD4_MY13_Phev_Rx" SG_ 947 Delay_Accy 1;
BA_ "U_CD42_MY14_Diesel_Rx" SG_ 947 Delay_Accy 1;
BA_ "U_CD42_MY14_Gas_Rx" SG_ 947 Delay_Accy 1;
BA_ "U_P552_MY15_Gas_Rx" SG_ 947 Delay_Accy 1;
BA_ "U_S550_MY15_Gas_Rx" SG_ 947 Delay_Accy 1;
BA_ "U_C489_MY14_Gas_Rx" SG_ 947 Delay_Accy 1;
BA_ "U_U502_MY15_Gas_Rx" SG_ 947 Delay_Accy 1;
BA_ "U_UP375_MY15_Gas_Rx" SG_ 947 Delay_Accy 1;
BA_ "U_UP375_MY15_Diesel_Rx" SG_ 947 Delay_Accy 1;
BA_ "U_CD43_MY16_Gas_Rx" SG_ 947 Delay_Accy 1;
BA_ "U_CD4_MY14_Diesel_Rx" SG_ 947 Delay_Accy 1;
BA_ "U_CD4_MY14_Gas_Rx" SG_ 947 Delay_Accy 1;
BA_ "U_CD4_MY14_Hev_Rx" SG_ 947 Delay_Accy 1;
BA_ "U_CD4_MY14_Phev_Rx" SG_ 947 Delay_Accy 1;
BA_ "CrossOver_InfoCAN" SG_ 947 FogLghtFrontOn_B_Stat 1;
BA_ "WakeupSignal" SG_ 947 TurnLghtLeft_D_Rq 1;
BA_ "CrossOver_InfoCAN" SG_ 947 TurnLghtLeft_D_Rq 1;
BA_ "U_CD4_MY13_Diesel_Rx" SG_ 947 TurnLghtLeft_D_Rq 1;
BA_ "U_CD4_MY13_Gas_Rx" SG_ 947 TurnLghtLeft_D_Rq 1;
BA_ "U_CD4_MY13_Hev_Rx" SG_ 947 TurnLghtLeft_D_Rq 1;
BA_ "U_CD4_MY13_Phev_Rx" SG_ 947 TurnLghtLeft_D_Rq 1;
BA_ "U_CD42_MY14_Diesel_Rx" SG_ 947 TurnLghtLeft_D_Rq 1;
BA_ "U_CD42_MY14_Gas_Rx" SG_ 947 TurnLghtLeft_D_Rq 1;
BA_ "U_P552_MY15_Gas_Rx" SG_ 947 TurnLghtLeft_D_Rq 1;
BA_ "U_C489_MY14_Gas_Rx" SG_ 947 TurnLghtLeft_D_Rq 1;
BA_ "U_UP375_MY15_Gas_Rx" SG_ 947 TurnLghtLeft_D_Rq 1;
BA_ "U_UP375_MY15_Diesel_Rx" SG_ 947 TurnLghtLeft_D_Rq 1;
BA_ "U_S550_MY15_Gas_Rx" SG_ 947 TurnLghtLeft_D_Rq 1;
BA_ "U_U502_MY15_Gas_Rx" SG_ 947 TurnLghtLeft_D_Rq 1;
BA_ "U_CD43_MY16_Gas_Rx" SG_ 947 TurnLghtLeft_D_Rq 1;
BA_ "U_CD4_MY14_Diesel_Rx" SG_ 947 TurnLghtLeft_D_Rq 1;
BA_ "U_CD4_MY14_Gas_Rx" SG_ 947 TurnLghtLeft_D_Rq 1;
BA_ "U_CD4_MY14_Hev_Rx" SG_ 947 TurnLghtLeft_D_Rq 1;
BA_ "U_CD4_MY14_Phev_Rx" SG_ 947 TurnLghtLeft_D_Rq 1;
BA_ "WakeupSignal" SG_ 947 CrashEvnt_D_Stat 1;
BA_ "CrossOver_InfoCAN" SG_ 947 CrashEvnt_D_Stat 1;
BA_ "GenSigStartValue" SG_ 947 CrashEvnt_D_Stat 3;
BA_ "U_CD4_MY13_Diesel_Rx" SG_ 947 CrashEvnt_D_Stat 1;
BA_ "U_CD4_MY13_Gas_Rx" SG_ 947 CrashEvnt_D_Stat 1;
BA_ "U_CD4_MY13_Hev_Rx" SG_ 947 CrashEvnt_D_Stat 1;
BA_ "U_CD4_MY13_Phev_Rx" SG_ 947 CrashEvnt_D_Stat 1;
BA_ "U_CD42_MY14_Diesel_Rx" SG_ 947 CrashEvnt_D_Stat 1;
BA_ "U_CD42_MY14_Gas_Rx" SG_ 947 CrashEvnt_D_Stat 1;
BA_ "U_P552_MY15_Gas_Rx" SG_ 947 CrashEvnt_D_Stat 1;
BA_ "U_S550_MY15_Gas_Rx" SG_ 947 CrashEvnt_D_Stat 1;
BA_ "U_C489_MY14_Gas_Rx" SG_ 947 CrashEvnt_D_Stat 1;
BA_ "U_U502_MY15_Gas_Rx" SG_ 947 CrashEvnt_D_Stat 1;
BA_ "U_UP375_MY15_Gas_Rx" SG_ 947 CrashEvnt_D_Stat 1;
BA_ "U_UP375_MY15_Diesel_Rx" SG_ 947 CrashEvnt_D_Stat 1;
BA_ "U_CD43_MY16_Gas_Rx" SG_ 947 CrashEvnt_D_Stat 1;
BA_ "CrossOver_InfoCAN" SG_ 947 FuelPmpInhbt_B_Stat 1;
BA_ "U_CD4_MY13_Diesel_Rx" SG_ 947 FuelPmpInhbt_B_Stat 1;
BA_ "U_CD4_MY13_Gas_Rx" SG_ 947 FuelPmpInhbt_B_Stat 1;
BA_ "U_CD4_MY13_Hev_Rx" SG_ 947 FuelPmpInhbt_B_Stat 1;
BA_ "U_CD4_MY13_Phev_Rx" SG_ 947 FuelPmpInhbt_B_Stat 1;
BA_ "U_CD42_MY14_Diesel_Rx" SG_ 947 FuelPmpInhbt_B_Stat 1;
BA_ "U_CD42_MY14_Gas_Rx" SG_ 947 FuelPmpInhbt_B_Stat 1;
BA_ "U_P552_MY15_Gas_Rx" SG_ 947 FuelPmpInhbt_B_Stat 1;
BA_ "U_S550_MY15_Gas_Rx" SG_ 947 FuelPmpInhbt_B_Stat 1;
BA_ "U_C489_MY14_Gas_Rx" SG_ 947 FuelPmpInhbt_B_Stat 1;
BA_ "U_U502_MY15_Gas_Rx" SG_ 947 FuelPmpInhbt_B_Stat 1;
BA_ "U_UP375_MY15_Gas_Rx" SG_ 947 FuelPmpInhbt_B_Stat 1;
BA_ "U_UP375_MY15_Diesel_Rx" SG_ 947 FuelPmpInhbt_B_Stat 1;
BA_ "U_CD43_MY16_Gas_Rx" SG_ 947 FuelPmpInhbt_B_Stat 1;
BA_ "CrossOver_InfoCAN" SG_ 947 BodySrvcRqd_B_Rq 1;
BA_ "GenSigSendType" SG_ 293 ClmtCtrlSeat_SetStat_Psgr 3;
BA_ "U_CD4_MY13_Diesel_Rx" SG_ 293 ClmtCtrlSeat_SetStat_Psgr 1;
BA_ "U_CD4_MY13_Gas_Rx" SG_ 293 ClmtCtrlSeat_SetStat_Psgr 1;
BA_ "U_CD4_MY13_Hev_Rx" SG_ 293 ClmtCtrlSeat_SetStat_Psgr 1;
BA_ "U_CD4_MY13_Phev_Rx" SG_ 293 ClmtCtrlSeat_SetStat_Psgr 1;
BA_ "U_CD42_MY14_Diesel_Rx" SG_ 293 ClmtCtrlSeat_SetStat_Psgr 1;
BA_ "U_CD42_MY14_Gas_Rx" SG_ 293 ClmtCtrlSeat_SetStat_Psgr 1;
BA_ "U_P552_MY15_Gas_Rx" SG_ 293 ClmtCtrlSeat_SetStat_Psgr 1;
BA_ "U_S550_MY15_Gas_Rx" SG_ 293 ClmtCtrlSeat_SetStat_Psgr 1;
BA_ "U_C489_MY14_Gas_Rx" SG_ 293 ClmtCtrlSeat_SetStat_Psgr 1;
BA_ "U_U502_MY15_Gas_Rx" SG_ 293 ClmtCtrlSeat_SetStat_Psgr 1;
BA_ "U_UP375_MY15_Gas_Rx" SG_ 293 ClmtCtrlSeat_SetStat_Psgr 1;
BA_ "U_UP375_MY15_Diesel_Rx" SG_ 293 ClmtCtrlSeat_SetStat_Psgr 1;
BA_ "U_CD43_MY16_Gas_Rx" SG_ 293 ClmtCtrlSeat_SetStat_Psgr 1;
BA_ "U_CD4_MY13_Diesel_Tx" SG_ 293 ClmtCtrlSeat_SetStat_Psgr 1;
BA_ "U_CD4_MY13_Gas_Tx" SG_ 293 ClmtCtrlSeat_SetStat_Psgr 1;
BA_ "U_CD4_MY13_Hev_Tx" SG_ 293 ClmtCtrlSeat_SetStat_Psgr 1;
BA_ "U_CD4_MY13_Phev_Tx" SG_ 293 ClmtCtrlSeat_SetStat_Psgr 1;
BA_ "U_CD42_MY14_Diesel_Tx" SG_ 293 ClmtCtrlSeat_SetStat_Psgr 1;
BA_ "U_CD42_MY14_Gas_Tx" SG_ 293 ClmtCtrlSeat_SetStat_Psgr 1;
BA_ "U_P552_MY15_Gas_Tx" SG_ 293 ClmtCtrlSeat_SetStat_Psgr 1;
BA_ "U_S550_MY15_Gas_Tx" SG_ 293 ClmtCtrlSeat_SetStat_Psgr 1;
BA_ "U_C489_MY14_Gas_Tx" SG_ 293 ClmtCtrlSeat_SetStat_Psgr 1;
BA_ "U_U502_MY15_Gas_Tx" SG_ 293 ClmtCtrlSeat_SetStat_Psgr 1;
BA_ "U_CD43_MY16_Gas_Tx" SG_ 293 ClmtCtrlSeat_SetStat_Psgr 1;
BA_ "U_CD4_MY14_Diesel_Tx" SG_ 293 ClmtCtrlSeat_SetStat_Psgr 1;
BA_ "U_CD4_MY14_Gas_Tx" SG_ 293 ClmtCtrlSeat_SetStat_Psgr 1;
BA_ "U_CD4_MY14_Hev_Tx" SG_ 293 ClmtCtrlSeat_SetStat_Psgr 1;
BA_ "U_CD4_MY14_Phev_Tx" SG_ 293 ClmtCtrlSeat_SetStat_Psgr 1;
BA_ "GenSigSendType" SG_ 293 ClmtCtrlSeat_SetStat_Dvr 3;
BA_ "U_CD4_MY13_Diesel_Rx" SG_ 293 ClmtCtrlSeat_SetStat_Dvr 1;
BA_ "U_CD4_MY13_Gas_Rx" SG_ 293 ClmtCtrlSeat_SetStat_Dvr 1;
BA_ "U_CD4_MY13_Hev_Rx" SG_ 293 ClmtCtrlSeat_SetStat_Dvr 1;
BA_ "U_CD4_MY13_Phev_Rx" SG_ 293 ClmtCtrlSeat_SetStat_Dvr 1;
BA_ "U_CD42_MY14_Diesel_Rx" SG_ 293 ClmtCtrlSeat_SetStat_Dvr 1;
BA_ "U_CD42_MY14_Gas_Rx" SG_ 293 ClmtCtrlSeat_SetStat_Dvr 1;
BA_ "U_P552_MY15_Gas_Rx" SG_ 293 ClmtCtrlSeat_SetStat_Dvr 1;
BA_ "U_S550_MY15_Gas_Rx" SG_ 293 ClmtCtrlSeat_SetStat_Dvr 1;
BA_ "U_C489_MY14_Gas_Rx" SG_ 293 ClmtCtrlSeat_SetStat_Dvr 1;
BA_ "U_U502_MY15_Gas_Rx" SG_ 293 ClmtCtrlSeat_SetStat_Dvr 1;
BA_ "U_UP375_MY15_Gas_Rx" SG_ 293 ClmtCtrlSeat_SetStat_Dvr 1;
BA_ "U_UP375_MY15_Diesel_Rx" SG_ 293 ClmtCtrlSeat_SetStat_Dvr 1;
BA_ "U_CD43_MY16_Gas_Rx" SG_ 293 ClmtCtrlSeat_SetStat_Dvr 1;
BA_ "U_CD4_MY13_Diesel_Tx" SG_ 293 ClmtCtrlSeat_SetStat_Dvr 1;
BA_ "U_CD4_MY13_Gas_Tx" SG_ 293 ClmtCtrlSeat_SetStat_Dvr 1;
BA_ "U_CD4_MY13_Hev_Tx" SG_ 293 ClmtCtrlSeat_SetStat_Dvr 1;
BA_ "U_CD4_MY13_Phev_Tx" SG_ 293 ClmtCtrlSeat_SetStat_Dvr 1;
BA_ "U_CD42_MY14_Diesel_Tx" SG_ 293 ClmtCtrlSeat_SetStat_Dvr 1;
BA_ "U_CD42_MY14_Gas_Tx" SG_ 293 ClmtCtrlSeat_SetStat_Dvr 1;
BA_ "U_P552_MY15_Gas_Tx" SG_ 293 ClmtCtrlSeat_SetStat_Dvr 1;
BA_ "U_S550_MY15_Gas_Tx" SG_ 293 ClmtCtrlSeat_SetStat_Dvr 1;
BA_ "U_C489_MY14_Gas_Tx" SG_ 293 ClmtCtrlSeat_SetStat_Dvr 1;
BA_ "U_U502_MY15_Gas_Tx" SG_ 293 ClmtCtrlSeat_SetStat_Dvr 1;
BA_ "U_CD43_MY16_Gas_Tx" SG_ 293 ClmtCtrlSeat_SetStat_Dvr 1;
BA_ "U_CD4_MY14_Diesel_Tx" SG_ 293 ClmtCtrlSeat_SetStat_Dvr 1;
BA_ "U_CD4_MY14_Gas_Tx" SG_ 293 ClmtCtrlSeat_SetStat_Dvr 1;
BA_ "U_CD4_MY14_Hev_Tx" SG_ 293 ClmtCtrlSeat_SetStat_Dvr 1;
BA_ "U_CD4_MY14_Phev_Tx" SG_ 293 ClmtCtrlSeat_SetStat_Dvr 1;
VAL_ 993 EmButtn_D_Stat 7 "ButtonAssociationFailed" 6 "ButtonAssociationExited" 5 "ButtonAssociationEntered" 4 "Button4Pressed" 3 "Button3Pressed" 2 "Button2Pressed" 1 "Button1Pressed" 0 "Null" ;
VAL_ 993 PersStore_D_Actl 3 "Unused" 2 "Null" 1 "InProgress" 0 "Complete" ;
VAL_ 993 MemSwtch_D_RqRecall 7 "Unused_3" 6 "Unused_2" 5 "Unused_1" 4 "PERS_4" 3 "PERS_3" 2 "PERS_2" 1 "PERS_1" 0 "Null" ;
VAL_ 993 MemSwtch_D_RqAssoc 7 "Unused_3" 6 "Unused_2" 5 "Unused_1" 4 "PERS_4" 3 "PERS_3" 2 "PERS_2" 1 "PERS_1" 0 "Null" ;
VAL_ 993 PersIndexDsm_D_Actl 7 "Unused_3" 6 "Unused_2" 5 "Unused_1" 4 "Vehicle" 3 "PERS_4" 2 "PERS_3" 1 "PERS_2" 0 "PERS_1" ;
VAL_ 806 SnowPlowMde_B_Enbl 1 "Enable" 0 "Disable" ;
VAL_ 806 ClimtDeltaLoad_Pw_Actl 63 "Faulty" 62 "NoDataExists" ;
VAL_ 806 StopStrtDrvMde_B_RqBtn 1 "Pressed" 0 "Not_Pressed" ;
VAL_ 806 ClimtHeat_D_Rq 7 "NotUsed4" 6 "NotUsed3" 5 "NotUsed2" 4 "NotUsed1" 3 "Defrost_Defog" 2 "FastTempPullDownHeatingReq" 1 "OpportunisticHeatingReq" 0 "NoHeatingRequest" ;
VAL_ 806 ClimtCool_D_Rq 7 "NotUsed4" 6 "NotUsed3" 5 "NotUsed2" 4 "NotUsed1" 3 "Defrost_Defog" 2 "FastTempPullDownCoolReq" 1 "OpportunisticCoolingReq" 0 "NoCoolingRequest" ;
VAL_ 806 HvacEvap_Te_Actl 1023 "Fault" ;
VAL_ 806 HvacAirCond_B_Rq 1 "Yes" 0 "No" ;
VAL_ 806 ClimtPw_B_Rq 1 "Yes" 0 "No" ;
VAL_ 950 Modulation_Ctrl 3 "Unused" 2 "FSK" 1 "ASK_FSK" 0 "ASK" ;
VAL_ 950 TirePress_Filter_Ctrl 3 "Streaming" 2 "Filter" 1 "Not_Used" 0 "Null" ;
VAL_ 857 LHS_Temp_Disp_Digit3 2 "_5" 1 "_0" 0 "OFF" ;
VAL_ 857 Front_Blower_Ind 15 "Display_Blank" 14 "14_Indicators_On" 13 "13_Indicators_On" 12 "12_Indicators_On" 11 "11_Indicators_On" 10 "10_Indicators_On" 9 "9_Indicators_On" 8 "8_Indicators_On" 7 "7_Indicators_On" 6 "6_Indicators_On" 5 "5_Indicators_On" 4 "4_Indicators_On" 3 "3_Indicators_On" 2 "2_Indicators_On" 1 "1_Indicator_On" 0 "Indicators_Off" ;
VAL_ 857 EATC_LHS_Unit 2 "Fahrenheit" 1 "Celsius" 0 "Off" ;
VAL_ 856 Rr_Btn_Status_2nd 16 "Rear_Control_Pressed" 15 "RHS_Cld_Seat_Pressed" 14 "LHS_Cld_Seat_Pressed" 13 "RHS_Htd_Seat_Pressed" 12 "LHS_Htd_Seat_Pressed" 11 "Rear_Power_Pressed" 10 "AUTO_Pressed" 9 "Blwr_Dec_Pressed" 8 "Blwr_Inc_Pressed" 7 "RHS_Temp_Dec_Pressed" 6 "RHS_Temp_Inc_Pressed" 5 "LHS_Temp_Dec_Pressed" 4 "LHS_Temp_Inc_Pressed" 3 "Floor_Pressed" 2 "Panel_Floor_Pressed" 1 "Panel_Pressed" 0 "None_Pressed" ;
VAL_ 856 Rr_Btn_Status_1st 16 "Rear_Control_Pressed" 15 "RHS_Cld_Seat_Pressed" 14 "LHS_Cld_Seat_Pressed" 13 "RHS_Htd_Seat_Pressed" 12 "LHS_Htd_Seat_Pressed" 11 "Rear_Power_Pressed" 10 "AUTO_Pressed" 9 "Blwr_Dec_Pressed" 8 "Blwr_Inc_Pressed" 7 "RHS_Temp_Dec_Pressed" 6 "RHS_Temp_Inc_Pressed" 5 "LHS_Temp_Dec_Pressed" 4 "LHS_Temp_Inc_Pressed" 3 "Floor_Pressed" 2 "Panel_Floor_Pressed" 1 "Panel_Pressed" 0 "None_Pressed" ;
VAL_ 856 Frt_Btn_Status_2nd 31 "Defrost_Pressed" 30 "Htg_Strg_Whl_Pressed" 29 "RHS_Cld_Seat_Pressed" 28 "LHS_Cld_Seat_Pressed" 27 "RHS_Htd_Seat_Pressed" 26 "LHS_Htd_Seat_Pressed" 25 "Max_Defrost_Pressed" 24 "My_Temp_Pressed" 23 "Front_Power_Pressed" 22 "Rear_Defrost_Pressed" 21 "Pnl_Flr_Ws_Pressed" 20 "Pnl_Ws_Pressed" 19 "Windscreen_Pressed" 18 "Htd_Frt_Wsh_Pressed" 17 "Auto_Recirc_Pressed" 16 "Outside_Pressed" 15 "Recirc_Pressed" 14 "Max_AC_Pressed" 13 "AUTO_Pressed" 12 "Blwr_Dec_Pressed" 11 "Blwr_Inc_Pressed" 10 "RHS_Temp_Dec_Pressed" 9 "RHS_Temp_Inc_Pressed" 8 "LHS_Temp_Dec_Pressed" 7 "LHS_Temp_Inc_Pressed" 6 "Dual_Pressed" 5 "AC_Pressed" 4 "Floor_Ws_Pressed" 3 "Floor_Pressed" 2 "Panel_Floor_Pressed" 1 "Panel_Pressed" 0 "None_Pressed" ;
VAL_ 856 Frt_Btn_Status_1st 31 "Defrost_Pressed" 30 "Htg_Strg_Whl_Pressed" 29 "RHS_Cld_Seat_Pressed" 28 "LHS_Cld_Seat_Pressed" 27 "RHS_Htd_Seat_Pressed" 26 "LHS_Htd_Seat_Pressed" 25 "Max_Defrost_Pressed" 24 "My_Temp_Pressed" 23 "Front_Power_Pressed" 22 "Rear_Defrost_Pressed" 21 "Pnl_Flr_Ws_Pressed" 20 "Pnl_Ws_Pressed" 19 "Windscreen_Pressed" 18 "Htd_Frt_Wsh_Pressed" 17 "Auto_Recirc_Pressed" 16 "Outside_Pressed" 15 "Recirc_Pressed" 14 "Max_AC_Pressed" 13 "AUTO_Pressed" 12 "Blwr_Dec_Pressed" 11 "Blwr_Inc_Pressed" 10 "RHS_Temp_Dec_Pressed" 9 "RHS_Temp_Inc_Pressed" 8 "LHS_Temp_Dec_Pressed" 7 "LHS_Temp_Inc_Pressed" 6 "Dual_Pressed" 5 "AC_Pressed" 4 "Floor_Ws_Pressed" 3 "Floor_Pressed" 2 "Panel_Floor_Pressed" 1 "Panel_Pressed" 0 "None_Pressed" ;
VAL_ 856 Frt_Blower_Speed 3 "NotUsed" 2 "Max_Blower" 1 "Min_Blower" 0 "No_Request" ;
VAL_ 856 Drv_Set_Temp 31 "HI" 30 "29_5" 29 "29_0" 28 "28_5" 27 "28_0" 26 "27_5" 25 "27_0" 24 "26_5" 23 "26_0" 22 "25_5" 21 "25_0" 20 "24_5" 19 "24_0" 18 "23_5" 17 "23_0" 16 "22_5" 15 "22_0" 14 "21_5" 13 "21_0" 12 "20_5" 11 "20_0" 10 "19_5" 9 "19_0" 8 "18_5" 7 "18_0" 6 "17_5" 5 "17_0" 4 "16_5" 3 "16_0" 2 "15_5" 1 "LO" 0 "No_Request" ;
VAL_ 854 CC_Fr_Stat_User_Adj 7 "Unused4" 6 "Unused3" 5 "Unused2" 4 "Unused1" 3 "Fr_Blwr_Spd_Selection" 2 "FRHS_SetPt_Selection" 1 "FLHS_SetPt_Selection" 0 "None" ;
VAL_ 854 Front_Blower_Indicate 15 "Display_Blank" 14 "14_Indicators_On" 13 "13_Indicators_On" 12 "12_Indicators_On" 11 "11_Indicators_On" 10 "10_Indicators_On" 9 "9_Indicators_On" 8 "8_Indicators_On" 7 "7_Indicators_On" 6 "6_Indicators_On" 5 "5_Indicators_On" 4 "4_Indicators_On" 3 "3_Indicators_On" 2 "2_Indicators_On" 1 "1_Indicator_On" 0 "Indicators_Off" ;
VAL_ 854 CC_Diagnostics_Active 1 "Yes" 0 "No" ;
VAL_ 854 RHS_Temp_Display_Digit3 2 "_5" 1 "_0" 0 "OFF" ;
VAL_ 854 LHS_Temp_Display_Digit3 2 "_5" 1 "_0" 0 "OFF" ;
VAL_ 854 EATC_RHS_Units 2 "Fahrenheit" 1 "Celsius" 0 "Off" ;
VAL_ 854 EATC_LHS_Units 2 "Fahrenheit" 1 "Celsius" 0 "Off" ;
VAL_ 534 WhlDirRr_D_Actl 3 "Failed" 2 "Unknown" 1 "Backward" 0 "Forward" ;
VAL_ 534 WhlDirRl_D_Actl 3 "Failed" 2 "Unknown" 1 "Backward" 0 "Forward" ;
VAL_ 534 WhlDirFr_D_Actl 3 "Failed" 2 "Unknown" 1 "Backward" 0 "Forward" ;
VAL_ 534 WhlDirFl_D_Actl 3 "Failed" 2 "Unknown" 1 "Backward" 0 "Forward" ;
VAL_ 772 MemDrvDeny_B_Stat 1 "Yes" 0 "No" ;
VAL_ 772 Memory_Feedback_Rqst 1 "Yes" 0 "No" ;
VAL_ 772 Easy_Entry_Rqst 2 "Easy_Entry" 1 "Drive" 0 "Null" ;
VAL_ 772 Memory_Cmd 7 "Recall_3" 4 "Store_4" 3 "Store_3" 6 "Recall_2" 5 "Recall_1" 2 "Store_2" 1 "Store_1" 0 "Null" 8 "Recall_4" ;
VAL_ 772 Cancel_Auto_Movement 1 "Cancel" 0 "Null" ;
VAL_ 935 CtaAlrtRight2_D_Stat 7 "NotUsed3" 6 "NotUsed2" 5 "NotUsed1" 4 "AlertZone4" 3 "AlertZone3" 2 "AlertZone2" 1 "AlertZone1" 0 "Off" ;
VAL_ 935 BttRight_D_Stat 7 "NotUsed" 6 "Disabled" 5 "Off" 4 "OffTemp" 3 "NotConnected" 2 "Pending" 1 "Connected" 0 "NotDetermined" ;
VAL_ 935 BttRight_D_RqDrv 3 "NotUsed" 2 "Request" 1 "NoRequest" 0 "Null" ;
VAL_ 935 CtaSnsRight_D_Stat 3 "Invalid" 2 "System_Failure" 1 "Blocked" 0 "Clear" ;
VAL_ 935 CtaAlrtRight_D_Stat 1 "On" 0 "Off" ;
VAL_ 935 CtaRight_D_Stat 4 "Invalid" 3 "Disabled" 2 "On" 1 "Trailer_Tow_Off" 0 "Off" ;
VAL_ 935 SodRight_D_Stat 4 "Invalid" 3 "Disabled" 2 "On" 1 "Trailer_Tow_Off" 0 "Off" ;
VAL_ 935 SodSnsRight_D_Stat 3 "Second_Warning_Audio" 2 "System_Failure" 1 "Blocked" 0 "Clear" ;
VAL_ 935 SodAlrtRight_D_Stat 3 "Bulb_Proveout" 2 "Flash" 1 "On" 0 "Off" ;
VAL_ 935 SodDetctRight_D_Stat 4 "Sensor_Blocked" 3 "Sensor_Fault" 2 "Flash_On" 1 "Alert_On" 0 "AlertOff_FlashOff_SensrClr" ;
VAL_ 935 SodInnrRight_D_Stat 3 "Reporting" 2 "Not_Reporting" 1 "System_Standby" 0 "Initialization" ;
VAL_ 935 CtaInnrRight_D_Stat 3 "Reporting" 2 "Not_Reporting" 1 "System_Standby" 0 "Initialization" ;
VAL_ 934 CtaInnrLeft_D_Stat 3 "Reporting" 2 "Not_Reporting" 1 "System_Standby" 0 "Initialization" ;
VAL_ 934 CtaAlrtLeft2_D_Stat 7 "NotUsed3" 6 "NotUsed2" 5 "NotUsed1" 4 "AlertZone4" 3 "AlertZone3" 2 "AlertZone2" 1 "AlertZone1" 0 "Off" ;
VAL_ 934 BttLeft_D_Stat 7 "NotUsed" 6 "Disabled" 5 "Off" 4 "OffTemp" 3 "NotConnected" 2 "Pending" 1 "Connected" 0 "NotDetermined" ;
VAL_ 934 BttLeft_D_RqDrv 3 "NotUsed" 2 "Request" 1 "NoRequest" 0 "Null" ;
VAL_ 934 CtaSnsLeft_D_Stat 3 "Invalid" 2 "System_Failure" 1 "Blocked" 0 "Clear" ;
VAL_ 934 SodDetctLeft_D_Stat 4 "Sensor_Blocked" 3 "Sensor_Fault" 2 "Flash_On" 1 "Alert_On" 0 "AlertOff_FlashOff_SensrClr" ;
VAL_ 934 CtaLeft_D_Stat 4 "Invalid" 3 "Disabled" 2 "On" 1 "Trailer_Tow_Off" 0 "Off" ;
VAL_ 934 CtaAlrtLeft_D_Stat 1 "On" 0 "Off" ;
VAL_ 934 SodLeft_D_Stat 4 "Invalid" 3 "Disabled" 2 "On" 1 "Trailer_Tow_Off" 0 "Off" ;
VAL_ 934 SodSnsLeft_D_Stat 3 "Second_Warning_Audio" 2 "System_Failure" 1 "Blocked" 0 "Clear" ;
VAL_ 934 SodAlrtLeft_D_Stat 3 "Bulb_Proveout" 2 "Flash" 1 "On" 0 "Off" ;
VAL_ 934 SodInnrLeft_D_Stat 3 "Reporting" 2 "Not_Reporting" 1 "System_Standby" 0 "Initialization" ;
VAL_ 969 Dimming_Level_Stat 3 "Low" 2 "Not_Used" 1 "High" 0 "Null" ;
VAL_ 969 Current_Color_Stat 15 "NotUsed7" 14 "NotUsed6" 13 "NotUsed5" 12 "NotUsed4" 11 "NotUsed3" 10 "NotUsed2" 9 "NotUsed1" 8 "Null" 7 "Color7" 6 "Color6" 5 "Color5" 4 "Color4" 3 "Color3" 2 "Color2" 1 "Color1" 0 "Off" ;
VAL_ 969 BlendedColorRed_Stat 15 "NotUsed10" 14 "NotUsed9" 13 "NotUsed8" 12 "NotUsed7" 11 "NotUsed6" 10 "NotUsed5" 9 "NotUsed4" 8 "NotUsed3" 7 "NotUsed2" 6 "NotUsed1" 5 "_5" 4 "_4" 3 "_3" 2 "_2" 1 "_1" 0 "Null" ;
VAL_ 969 BlendedColorGreen_Stat 15 "NotUsed10" 14 "NotUsed9" 13 "NotUsed8" 12 "NotUsed7" 11 "NotUsed6" 10 "NotUsed5" 9 "NotUsed4" 8 "NotUsed3" 7 "NotUsed2" 6 "NotUsed1" 5 "_5" 4 "_4" 3 "_3" 2 "_2" 1 "_1" 0 "Null" ;
VAL_ 969 BlendedColorBlue_Stat 15 "NotUsed10" 14 "NotUsed9" 13 "NotUsed8" 12 "NotUsed7" 11 "NotUsed6" 10 "NotUsed5" 9 "NotUsed4" 8 "NotUsed3" 7 "NotUsed2" 6 "NotUsed1" 5 "_5" 4 "_4" 3 "_3" 2 "_2" 1 "_1" 0 "Null" ;
VAL_ 969 BlendedColor_Stat 3 "NotUsed" 2 "Null" 1 "On" 0 "Off" ;
VAL_ 969 TurnLampRrOut_B_Stat 1 "Out" 0 "Null" ;
VAL_ 969 TurnLampRlOut_B_Stat 1 "Out" 0 "Null" ;
VAL_ 1070 StopStrtStdby_D_Indic_UB 1 "Fresh_data" 0 "Unchanged_data" ;
VAL_ 1070 PassRstrnInd_Req_UB 1 "Fresh_data" 0 "Unchanged_data" ;
VAL_ 1070 HiElPwInhbt_B_Stat_UB 1 "Fresh_data" 0 "Unchanged_data" ;
VAL_ 1070 HiElPwInhbt_B_Stat 1 "Inhibit" 0 "No_Inibit" ;
VAL_ 1070 StopStrtStdby_D_Indic 6 "NotUsed2" 5 "Telltale_Struck_Out" 4 "Telltale_Flashing_Amber" 3 "Telltale_On_Amber" 2 "Telltale_Flashing_Green" 1 "Telltale_On_Green" 0 "Telltale_Off" 7 "NotUsed3" ;
VAL_ 1070 CoolantFanStepAct_UB 1 "Fresh_data" 0 "Unchanged_data" ;
VAL_ 1070 CoolantFanStepAct 31 "Unused7" 30 "Unused6" 29 "Unused5" 28 "Unused4" 27 "Unused3" 26 "Unused2" 25 "Unused1" 23 "Step23" 22 "Step22" 21 "Step21" 20 "Step20" 19 "Step19" 18 "Step18" 17 "Step17" 16 "Step16" 15 "Step15" 14 "Step14" 13 "Step13" 12 "Step12" 11 "Step11" 10 "Step10" 9 "Step9" 8 "Step8" 7 "Step7" 6 "Step6" 5 "Step5" 4 "Step4" 3 "Step3" 2 "Step2" 1 "Step1" 24 "Max_Fan_Speed_Req" 0 "Fan_Cmd_Off" ;
VAL_ 1070 VehVActlEng_D_Qf_UB 1 "Fresh_data" 0 "Unchanged_data" ;
VAL_ 1070 RstrnImpactEvntStatus_UB 1 "Fresh_data" 0 "Unchanged_data" ;
VAL_ 1070 EngAirIn_Te_Actl_UB 1 "Fresh_data" 0 "Unchanged_data" ;
VAL_ 1070 RstrnImpactEvntStatus 7 "Invalid" 6 "Not_Used_4" 5 "Threshold_2_Exceeded" 4 "Not_Used_3" 3 "Threshold_1_Exceeded" 2 "Not_Used_2" 1 "Not_Used_1" 0 "Normal" ;
VAL_ 1070 EngAirIn_Te_Actl 1023 "Fault" 1022 "Unknown" ;
VAL_ 1070 EngAout_N_Actl_UB 1 "Fresh_data" 0 "Unchanged_data" ;
VAL_ 1070 VehVActlEng_D_Qf 3 "OK" 2 "Not_Within_Specifications" 1 "No_Data_Exists" 0 "Faulty" ;
VAL_ 1070 Veh_V_ActlEng_UB 1 "Fresh_data" 0 "Unchanged_data" ;
VAL_ 1070 PassRstrnInd_Req 3 "ABOnNotIllum_OffNotIllum" 2 "AirbagOnNot_Illum_OffIllum" 1 "AirbagOn_Illum_OffNotIllum" 0 "AirbagOn_Illum_Off_Illum" ;
VAL_ 1050 SteWhlHeat_D_Rq 15 "NotUsed6" 14 "NotUsed5" 13 "NotUsed4" 12 "NotUsed3" 11 "NotUsed2" 10 "NotUsed1" 9 "Reserved_3" 8 "Reserved_2" 7 "Reserved_1" 6 "Level_3_Heating" 5 "Level_3_Heating_LS" 4 "Level_2_Heating" 3 "Level_2_Heating_LS" 2 "Level_1_Heating" 1 "Level_1_Heating_LS" 0 "Off" ;
VAL_ 1050 MirrorHeatOn_B_Rq 1 "True" 0 "False" ;
VAL_ 1050 Remote_Start_QuietMode 1 "Quiet" 0 "Not_Quiet" ;
VAL_ 1050 Outside_Air_Temp_Stat 255 "Invalid" 254 "Unknown" ;
VAL_ 947 ValetMode_D_Mem 1 "On" 0 "Off" ;
VAL_ 947 DrStatDrvErrCnt_B_Stat 1 "Yes" 0 "No" ;
VAL_ 947 TurnLghtRightOn_B_Stat 1 "On" 0 "Off" ;
VAL_ 947 TurnLghtLeftOn_B_Stat 1 "On" 0 "Off" ;
VAL_ 947 Backlit_LED_Status 15 "Unused3" 14 "Unused2" 13 "Unused1" 12 "Night_12" 11 "Night_11" 10 "Night_10" 9 "Night_9" 8 "Night_8" 7 "Night_7" 6 "Night_6" 5 "Night_5" 4 "Night_4" 3 "Night_3" 2 "Night_2" 1 "Night_1" 0 "Off" ;
VAL_ 947 FogLghtRearOn_B_Stat 1 "On" 0 "Off" ;
VAL_ 947 IgnKeyType_D_Actl 15 "Invalid" 14 "Unknown" 3 "Key_Not_Prgrm_Read_Failure" 2 "Key_In_Ign_My_Key" 1 "Key_In_Ign_Standard_Key" 0 "Key_Read_In_Progress" ;
VAL_ 947 TurnLghtRight_D_Rq 3 "Seq" 2 "On" 1 "Off" 0 "Null" ;
VAL_ 947 Parklamp_Status 1 "On" 0 "Off" 3 "Invalid" 2 "Unknown" ;
VAL_ 947 Litval 255 "Invalid" 254 "Unknown" 5 "Day" 4 "Twilight_4" 3 "Twilight_3" 2 "Twilight_2" 1 "Twilight_1" 0 "Night" ;
VAL_ 947 Key_In_Ignition_Stat 1 "In" 0 "Out" ;
VAL_ 947 Ignition_Status 0 "Unknown" 1 "Off" 15 "Invalid" 8 "Start" 4 "Run" 2 "Accessory" ;
VAL_ 947 Dimming_Lvl 255 "Invalid" 254 "Unknown" 18 "Day_6" 17 "Day_5" 16 "Day_4" 15 "Day_3" 14 "Day_2" 13 "Day_1" 12 "Night_12" 11 "Night_11" 10 "Night_10" 9 "Night_9" 8 "Night_8" 7 "Night_7" 6 "Night_6" 5 "Night_5" 4 "Night_4" 3 "Night_3" 2 "Night_2" 1 "Night_1" 0 "Off" ;
VAL_ 947 Day_Night_Status 3 "NotUsed" 2 "Night" 1 "Day" 0 "Null" ;
VAL_ 947 Remote_Start_Status 3 "Invalid" 2 "Unknown" 1 "Remote" 0 "Null" ;
VAL_ 947 DrStatTgate_B_Actl 1 "Ajar" 0 "Closed" ;
VAL_ 947 DrStatRr_B_Actl 1 "Ajar" 0 "Closed" ;
VAL_ 947 DrStatRl_B_Actl 1 "Ajar" 0 "Closed" ;
VAL_ 947 DrStatPsngr_B_Actl 1 "Ajar" 0 "Closed" ;
VAL_ 947 DrStatInnrTgate_B_Actl 1 "Ajar" 0 "Closed" ;
VAL_ 947 DrStatHood_B_Actl 1 "Ajar" 0 "Closed" ;
VAL_ 947 DrStatDrv_B_Actl 1 "Ajar" 0 "Closed" ;
VAL_ 947 PrkBrkActv_B_Actl 1 "Active" 0 "Inactive" ;
VAL_ 947 LifeCycMde_D_Actl 3 "Transport" 2 "NotUsed" 1 "Factory" 0 "Normal" ;
VAL_ 947 Delay_Accy 1 "On" 0 "Off" ;
VAL_ 947 FogLghtFrontOn_B_Stat 1 "On" 0 "Off" ;
VAL_ 947 TurnLghtLeft_D_Rq 3 "Seq" 2 "On" 1 "Off" 0 "Null" ;
VAL_ 947 CrashEvnt_D_Stat 3 "Invalid" 2 "Fuel_Cutoff_Event" 1 "Deploy_Event" 0 "No_Event" ;
VAL_ 947 FuelPmpInhbt_B_Stat 1 "Inhibit" 0 "No_Inibit" ;
VAL_ 947 BodySrvcRqd_B_Rq 1 "Yes" 0 "No" ;
VAL_ 293 ClmtCtrlSeat_SetStat_Psgr 128 "H3_High_Heat__MAX" 64 "H2_Medium_Heat" 32 "H1_Low_Heat" 16 "C3_High_Cool__MAX" 8 "C2_Medium_Cool" 4 "C1_Low_Cool" 2 "Off" ;
VAL_ 293 ClmtCtrlSeat_SetStat_Dvr 128 "H3_High_Heat__MAX" 64 "H2_Medium_Heat" 32 "H1_Low_Heat" 16 "C3_High_Cool__MAX" 8 "C2_Medium_Cool" 4 "C1_Low_Cool" 2 "Off" ;
